VERSION ""

NS_ :

BS_:

BU_:

BO_ 19 PDU_2248: 6 Vector__XXX
 SG_ PrplSysWhlFlrCtlPriAxlRtTrqCmd : 7|15@0+ (2,-22534) [-22534|43000] "Nm" EBCM
 SG_ PrplSysWhlFlrCtlPriAxlRtActv : 8|1@0+ (1,0) [0|1] "" EBCM

BO_ 1026 PDU_2252: 24 Vector__XXX
 SG_ FE44SDGHSR_LtFstHptcStReqSeqNum : 1|2@0+ (1,0) [0|3] "counts" CGM
 SG_ FE44SDGHSR_LtFstHptcStReqPuls : 7|6@0+ (1,0) [0|63] "pulses" CGM
 SG_ FE44SDGHSR_LtSloHptcStReqSeqNum : 9|2@0+ (1,0) [0|3] "counts" CGM
 SG_ FE44SDGHSR_LtSloHptcStReqPuls : 15|6@0+ (1,0) [0|63] "pulses" CGM
 SG_ FE44SDGHSR_RtFstHptcStReqSeqNum : 17|2@0+ (1,0) [0|3] "counts" CGM
 SG_ FE44SDGHSR_RtFstHptcStReqPuls : 23|6@0+ (1,0) [0|63] "pulses" CGM
 SG_ FE44SDGHSR_RtSloHptcStReqSeqNum : 25|2@0+ (1,0) [0|3] "counts" CGM
 SG_ FE44SDGHSR_RtSloHptcStReqPuls : 31|6@0+ (1,0) [0|63] "pulses" CGM
 SG_ FFE44HSR_FrstRptHptcStReqSeqNum : 33|2@0+ (1,0) [0|3] "counts" CGM
 SG_ FFE44HSR_FrstRptHptcStReqPuls : 39|6@0+ (1,0) [0|63] "pulses" CGM
 SG_ FFE44HSR_FstHptcStReqSeqNum : 41|2@0+ (1,0) [0|3] "counts" CGM
 SG_ FFE44HSR_FstHptcStReqPuls : 47|6@0+ (1,0) [0|63] "pulses" CGM
 SG_ FFE44HSR_SloHptcStReqSeqNum : 49|2@0+ (1,0) [0|3] "counts" CGM
 SG_ FFE44HSR_SloHptcStReqPuls : 55|6@0+ (1,0) [0|63] "pulses" CGM
 SG_ FRE44HSR_FrstRptHptcStReqSeqNum : 57|2@0+ (1,0) [0|3] "counts" CGM
 SG_ FRE44HSR_FrstRptHptcStReqPuls : 63|6@0+ (1,0) [0|63] "pulses" CGM
 SG_ FRE44HSR_FstHptcStReqSeqNum : 65|2@0+ (1,0) [0|3] "counts" CGM
 SG_ FRE44HSR_FstHptcStReqPuls : 71|6@0+ (1,0) [0|63] "pulses" CGM
 SG_ FRE44HSR_SloHptcStReqSeqNum : 73|2@0+ (1,0) [0|3] "counts" CGM
 SG_ FRE44HSR_SloHptcStReqPuls : 79|6@0+ (1,0) [0|63] "pulses" CGM
 SG_ PrkAsstFllFrZn2ChEvntSt : 81|2@0+ (1,0) [0|2] "" CGM
 SG_ PrkAsstFllFrZn1ChEvntSt : 83|2@0+ (1,0) [0|2] "" CGM
 SG_ PrkAsstFlChEvntSt : 85|2@0+ (1,0) [0|2] "" CGM
 SG_ E44MutSts : 87|2@0+ (1,0) [0|2] "" CGM
 SG_ PrkAsstFllFrZn6ChEvntSt : 89|2@0+ (1,0) [0|2] "" CGM
 SG_ PrkAsstFllFrZn5ChEvntSt : 91|2@0+ (1,0) [0|2] "" CGM
 SG_ PrkAsstFllFrZn4ChEvntSt : 93|2@0+ (1,0) [0|2] "" CGM
 SG_ PrkAsstFllFrZn3ChEvntSt : 95|2@0+ (1,0) [0|2] "" CGM
 SG_ PrkAsstFllRrZn4ChEvntSt : 97|2@0+ (1,0) [0|2] "" CGM
 SG_ PrkAsstFllRrZn3ChEvntSt : 99|2@0+ (1,0) [0|2] "" CGM
 SG_ PrkAsstFllRrZn2ChEvntSt : 101|2@0+ (1,0) [0|2] "" CGM
 SG_ PrkAsstFllRrZn1ChEvntSt : 103|2@0+ (1,0) [0|2] "" CGM
 SG_ PrkAsstFrLftSdZn1ChEvntSt : 105|2@0+ (1,0) [0|2] "" CGM
 SG_ PrkAsstFrFrstRprtChEvntSt : 107|2@0+ (1,0) [0|2] "" CGM
 SG_ PrkAsstFllRrZn6ChEvntSt : 109|2@0+ (1,0) [0|2] "" CGM
 SG_ PrkAsstFllRrZn5ChEvntSt : 111|2@0+ (1,0) [0|2] "" CGM
 SG_ PrkAsstFrLftSdZn5ChEvntSt : 113|2@0+ (1,0) [0|2] "" CGM
 SG_ PrkAsstFrLftSdZn4ChEvntSt : 115|2@0+ (1,0) [0|2] "" CGM
 SG_ PrkAsstFrLftSdZn3ChEvntSt : 117|2@0+ (1,0) [0|2] "" CGM
 SG_ PrkAsstFrLftSdZn2ChEvntSt : 119|2@0+ (1,0) [0|2] "" CGM
 SG_ PrkAsstFrRghtSdZn3ChEvntSt : 121|2@0+ (1,0) [0|2] "" CGM
 SG_ PrkAsstFrRghtSdZn2ChEvntSt : 123|2@0+ (1,0) [0|2] "" CGM
 SG_ PrkAsstFrRghtSdZn1ChEvntSt : 125|2@0+ (1,0) [0|2] "" CGM
 SG_ PrkAsstFrLftSdZn6ChEvntSt : 127|2@0+ (1,0) [0|2] "" CGM
 SG_ PrkAsstFrRgrChEvntSt : 129|2@0+ (1,0) [0|2] "" CGM
 SG_ PrkAsstFrRghtSdZn6ChEvntSt : 131|2@0+ (1,0) [0|2] "" CGM
 SG_ PrkAsstFrRghtSdZn5ChEvntSt : 133|2@0+ (1,0) [0|2] "" CGM
 SG_ PrkAsstFrRghtSdZn4ChEvntSt : 135|2@0+ (1,0) [0|2] "" CGM
 SG_ PrkAsstRrLftSdZn3ChEvntSt : 137|2@0+ (1,0) [0|2] "" CGM
 SG_ PrkAsstRrLftSdZn2ChEvntSt : 139|2@0+ (1,0) [0|2] "" CGM
 SG_ PrkAsstRrLftSdZn1ChEvntSt : 141|2@0+ (1,0) [0|2] "" CGM
 SG_ PrkAsstRrFrstRprtChEvntSt : 143|2@0+ (1,0) [0|2] "" CGM
 SG_ PrkAsstRrRghtSdZn1ChEvntSt : 145|2@0+ (1,0) [0|2] "" CGM
 SG_ PrkAsstRrLftSdZn6ChEvntSt : 147|2@0+ (1,0) [0|2] "" CGM
 SG_ PrkAsstRrLftSdZn5ChEvntSt : 149|2@0+ (1,0) [0|2] "" CGM
 SG_ PrkAsstRrLftSdZn4ChEvntSt : 151|2@0+ (1,0) [0|2] "" CGM
 SG_ PrkAsstRrRghtSdZn5ChEvntSt : 153|2@0+ (1,0) [0|2] "" CGM
 SG_ PrkAsstRrRghtSdZn4ChEvntSt : 155|2@0+ (1,0) [0|2] "" CGM
 SG_ PrkAsstRrRghtSdZn3ChEvntSt : 157|2@0+ (1,0) [0|2] "" CGM
 SG_ PrkAsstRrRghtSdZn2ChEvntSt : 159|2@0+ (1,0) [0|2] "" CGM
 SG_ SuprRmtPrkMnvrPrgs : 163|14@0+ (0.01,0) [0|163.83] "" CGM
 SG_ PrkAsstRrRgrChEvntSt : 165|2@0+ (1,0) [0|2] "" CGM
 SG_ PrkAsstRrRghtSdZn6ChEvntSt : 167|2@0+ (1,0) [0|2] "" CGM
 SG_ SuprRmtPrkWrnIndReq : 181|7@0+ (1,0) [0|70] "" CGM
 SG_ SuprRmtPrkDctvSftBtnReq : 186|2@0+ (1,0) [0|3] "" CGM
 SG_ SuprRmtPrkFcsReq : 188|2@0+ (1,0) [0|3] "" CGM
 SG_ SuprRmtPrkAutoStrgIconReq : 190|2@0+ (1,0) [0|2] "" CGM

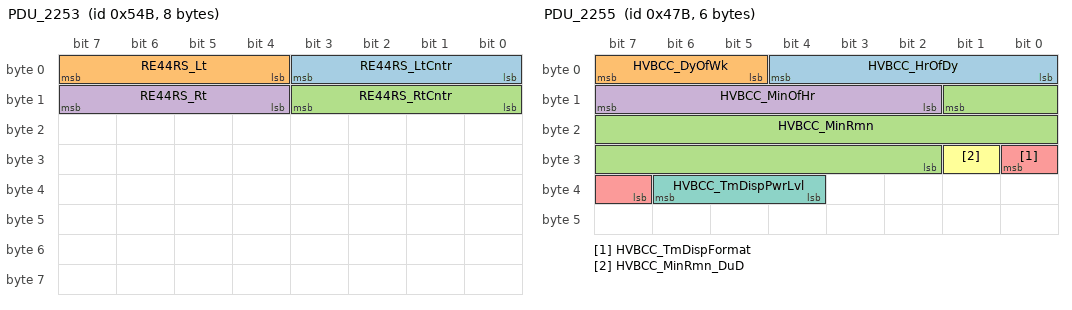
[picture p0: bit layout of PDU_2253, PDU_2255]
BO_ 1355 PDU_2253: 8 Vector__XXX
 SG_ RE44RS_LtCntr : 3|4@0+ (1,0) [0|14] "" CGM
 SG_ RE44RS_Lt : 7|4@0+ (1,0) [0|14] "" CGM
 SG_ RE44RS_RtCntr : 11|4@0+ (1,0) [0|14] "" CGM
 SG_ RE44RS_Rt : 15|4@0+ (1,0) [0|14] "" CGM

BO_ 1147 PDU_2255: 6 Vector__XXX
 SG_ HVBCC_HrOfDy : 4|5@0+ (1,0) [0|31] "h" Vector__XXX
 SG_ HVBCC_DyOfWk : 7|3@0+ (1,0) [0|7] "" Vector__XXX
 SG_ HVBCC_MinRmn : 9|16@0+ (1,0) [0|65535] "min" Vector__XXX
 SG_ HVBCC_MinOfHr : 15|6@0+ (1,0) [0|63] "min" Vector__XXX
 SG_ HVBCC_TmDispFormat : 24|2@0+ (1,0) [0|2] "" Vector__XXX
 SG_ HVBCC_MinRmn_DuD : 25|1@0+ (1,0) [0|1] "" Vector__XXX
 SG_ HVBCC_TmDispPwrLvl : 38|3@0+ (1,0) [0|4] "" VDM

BO_ 669 PDU_2256: 12 Vector__XXX
 SG_ Sig0101 : 7|1@0+ (1,0) [0|1] "" FOPM

BO_ 1321 PDU_2257: 12 Vector__XXX
 SG_ DMSDrwDrvrCstSetAval : 0|1@0+ (1,0) [0|1] "" CGM
 SG_ DMSDrwDrvrCstAvlFlg7 : 1|1@0+ (1,0) [0|1] "" CGM
 SG_ DMSDrwDrvrCstAvlFlg6 : 2|1@0+ (1,0) [0|1] "" CGM
 SG_ DMSDrwDrvrCstAvlFlg5 : 3|1@0+ (1,0) [0|1] "" CGM
 SG_ DMSDrwDrvrCstAvlFlg4 : 4|1@0+ (1,0) [0|1] "" CGM
 SG_ DMSDrwDrvrCstAvlFlg3 : 5|1@0+ (1,0) [0|1] "" CGM
 SG_ DMSDrwDrvrCstAvlFlg2 : 6|1@0+ (1,0) [0|1] "" CGM
 SG_ DMSDrwDrvrCstAvlFlg1 : 7|1@0+ (1,0) [0|1] "" CGM
 SG_ DMSIntnDrvrCstSetAval : 8|1@0+ (1,0) [0|1] "" CGM
 SG_ DMSIntnDrvrCstAvlFlg7 : 9|1@0+ (1,0) [0|1] "" CGM
 SG_ DMSIntnDrvrCstAvlFlg6 : 10|1@0+ (1,0) [0|1] "" CGM
 SG_ DMSIntnDrvrCstAvlFlg5 : 11|1@0+ (1,0) [0|1] "" CGM
 SG_ DMSIntnDrvrCstAvlFlg4 : 12|1@0+ (1,0) [0|1] "" CGM
 SG_ DMSIntnDrvrCstAvlFlg3 : 13|1@0+ (1,0) [0|1] "" CGM
 SG_ DMSIntnDrvrCstAvlFlg2 : 14|1@0+ (1,0) [0|1] "" CGM
 SG_ DMSIntnDrvrCstAvlFlg1 : 15|1@0+ (1,0) [0|1] "" CGM

BO_ 1318 PDU_2258: 12 Vector__XXX
 SG_ DMSDrwIntnDrvrDtnAlrtMutReqd : 3|1@0+ (1,0) [0|1] "" CGM
 SG_ DMSDrwIntnDrvrLvl1ChmEvntStat : 5|2@0+ (1,0) [0|2] "" CGM
 SG_ DMSDrwIntnDrvrLvl2ChmEvntStat : 7|2@0+ (1,0) [0|2] "" CGM

BO_ 1304 PDU_2259: 12 Vector__XXX
 SG_ DMSDrwDrvrDispTmSnLstBrk : 7|11@0+ (1,0) [0|2047] "min" CGM
 SG_ DMSDrwIntnDrvrHptcStReqPuls : 12|6@0+ (1,0) [0|63] "Pulses" CGM
 SG_ DMSDrwDrvrCstCurrSetVal : 16|3@0+ (1,0) [0|3] "" CGM
 SG_ DMSDrwIntnDrvrWrnIndReq : 20|4@0+ (1,0) [0|11] "" CGM
 SG_ DMSDrwIntnDrvrHptcStReqSeqNum : 22|2@0+ (1,0) [0|3] "Counts" CGM
 SG_ DMSDrwDrvrIndReq : 26|3@0+ (1,0) [0|5] "" CGM
 SG_ DMSDrwDrvrDispLvl : 29|3@0+ (1,0) [0|5] "" CGM
 SG_ DMSIntnDrvrIndReq : 33|3@0+ (1,0) [0|5] "" CGM
 SG_ DMSIntnDrvrDispLvl : 36|3@0+ (1,0) [0|5] "" CGM
 SG_ DMSIntnDrvrCstCurrSetVal : 39|3@0+ (1,0) [0|2] "" CGM
 SG_ DMSTnDrvrDrwIntnOffUnvIndOn : 42|1@0+ (1,0) [0|1] "" CGM
 SG_ DMSIntnDrvrDispFcsInd : 44|2@0+ (1,0) [0|2] "" CGM
 SG_ DMSDrwIntnDrvrDtnMtzdStBltPulRq : 46|2@0+ (1,0) [0|1] "" CGM

BO_ 544 PDU_2260: 16 Vector__XXX
 SG_ DMSEyeLocInfoXCrdnt : 7|15@0- (1,0) [-16384|16383] "mm" HUD_CAN
 SG_ DMSEyeLocInfoYCrdnt : 8|15@0- (1,0) [-16384|16383] "mm" HUD_CAN
 SG_ DMSEyeLocInfoZCrdnt : 25|15@0- (1,0) [-16384|16383] "mm" HUD_CAN
 SG_ DMSEyeGzInfoPrd : 42|14@0+ (0.05,0) [0|819.15] "Sec" HUD_CAN
 SG_ DMSEyeGzVctrPtch : 60|13@0- (0.001,0) [-4.096|4.095] "rad" HUD_CAN
 SG_ DMSEyeGzVctrRoll : 79|13@0- (0.001,0) [-4.096|4.095] "rad" HUD_CAN
 SG_ DMSEyeGzVctrYaw : 82|13@0- (0.001,0) [-4.096|4.095] "rad" HUD_CAN

BO_ 1341 PDU_2261: 12 Vector__XXX
 SG_ SD227_ARC : 4|2@0+ (1,0) [0|3] "" ECP_E
 SG_ VehDynsTkDtctSts : 7|3@0+ (1,0) [0|2] "" VICM,ECP_E

BO_ 1239 PDU_2273: 12 Vector__XXX
 SG_ PrkAsstTrHtchPsntCstAvlFlg1 : 0|1@0+ (1,0) [0|1] "" CGM
 SG_ PrkAsstONOFFCstAvlFlg7 : 1|1@0+ (1,0) [0|1] "" CGM
 SG_ PrkAsstONOFFCstAvlFlg6 : 2|1@0+ (1,0) [0|1] "" CGM
 SG_ PrkAsstONOFFCstAvlFlg5 : 3|1@0+ (1,0) [0|1] "" CGM
 SG_ PrkAsstONOFFCstAvlFlg4 : 4|1@0+ (1,0) [0|1] "" CGM
 SG_ PrkAsstONOFFCstAvlFlg3 : 5|1@0+ (1,0) [0|1] "" CGM
 SG_ PrkAsstONOFFCstAvlFlg2 : 6|1@0+ (1,0) [0|1] "" CGM
 SG_ PrkAsstONOFFCstAvlFlg1 : 7|1@0+ (1,0) [0|1] "" CGM
 SG_ PrkAsstTrHtchPsntCstAvlFlg7 : 10|1@0+ (1,0) [0|1] "" CGM
 SG_ PrkAsstTrHtchPsntCstAvlFlg6 : 11|1@0+ (1,0) [0|1] "" CGM
 SG_ PrkAsstTrHtchPsntCstAvlFlg5 : 12|1@0+ (1,0) [0|1] "" CGM
 SG_ PrkAsstTrHtchPsntCstAvlFlg4 : 13|1@0+ (1,0) [0|1] "" CGM
 SG_ PrkAsstTrHtchPsntCstAvlFlg3 : 14|1@0+ (1,0) [0|1] "" CGM
 SG_ PrkAsstTrHtchPsntCstAvlFlg2 : 15|1@0+ (1,0) [0|1] "" CGM

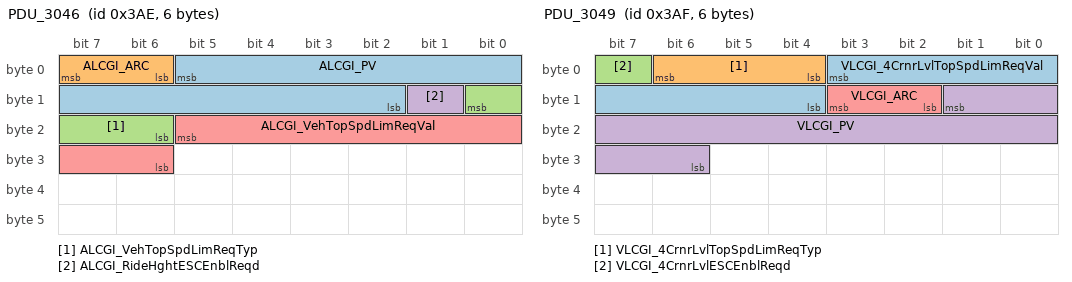
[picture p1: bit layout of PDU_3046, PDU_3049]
BO_ 942 PDU_3046: 6 Vector__XXX
 SG_ ALCGI_PV : 5|12@0+ (1,0) [0|4095] "" ECP_E
 SG_ ALCGI_ARC : 7|2@0+ (1,0) [0|3] "" ECP_E
 SG_ ALCGI_VehTopSpdLimReqTyp : 8|3@0+ (1,0) [0|6] "" ECP_E
 SG_ ALCGI_RideHghtESCEnblReqd : 9|1@0+ (1,0) [0|1] "" ECP_E
 SG_ ALCGI_VehTopSpdLimReqVal : 21|8@0+ (2,0) [0|510] "kph" ECP_E

BO_ 943 PDU_3049: 6 Vector__XXX
 SG_ VLCGI_4CrnrLvlTopSpdLimReqVal : 3|8@0+ (2,0) [0|510] "kph" ECM,PCM,ECP_E
 SG_ VLCGI_4CrnrLvlTopSpdLimReqTyp : 6|3@0+ (1,0) [0|6] "" ECM,PCM,ECP_E
 SG_ VLCGI_4CrnrLvlESCEnblReqd : 7|1@0+ (1,0) [0|1] "" ECM,PCM,ECP_E
 SG_ VLCGI_PV : 9|12@0+ (1,0) [0|4095] "" ECM,PCM,ECP_E
 SG_ VLCGI_ARC : 11|2@0+ (1,0) [0|3] "" ECM,PCM,ECP_E

BO_ 1346 PDU_3052: 6 Vector__XXX
 SG_ RrwdImpMtgnAval : 7|1@0+ (1,0) [0|1] "" Vector__XXX

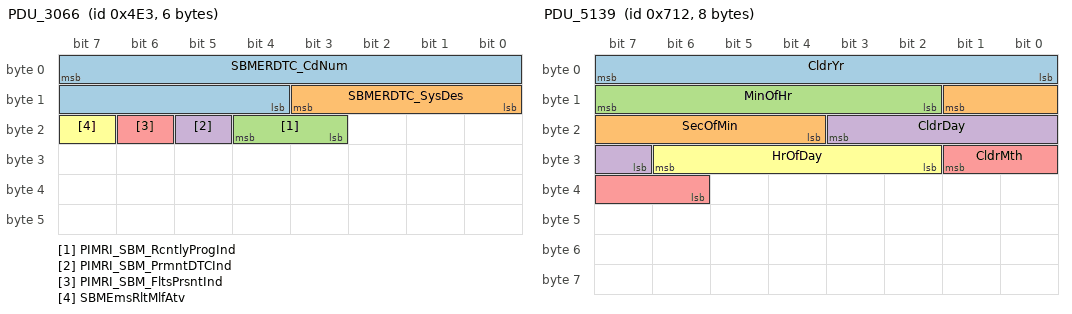
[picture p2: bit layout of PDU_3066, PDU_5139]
BO_ 1251 PDU_3066: 6 Vector__XXX
 SG_ SBMERDTC_CdNum : 7|12@0+ (1,0) [0|4095] "count" ECP_E
 SG_ SBMERDTC_SysDes : 11|4@0+ (1,0) [0|15] "" ECP_E
 SG_ PIMRI_SBM_RcntlyProgInd : 20|2@0+ (1,0) [0|3] "" ECM,PCM,ECP_E
 SG_ PIMRI_SBM_PrmntDTCInd : 21|1@0+ (1,0) [0|1] "" ECM,PCM,ECP_E
 SG_ PIMRI_SBM_FltsPrsntInd : 22|1@0+ (1,0) [0|1] "" ECM,PCM,ECP_E
 SG_ SBMEmsRltMlfAtv : 23|1@0+ (1,0) [0|1] "" ECP_E

BO_ 1429 PDU_4058: 6 Vector__XXX
 SG_ RrClsrAjrStat : 6|1@0+ (1,0) [0|1] "" ACP2_MCU,BSM,VICM,EOCM,EOCM_HC_Superset,FCM,E44
 SG_ RrClsrAjrStat_Inv : 7|1@0+ (1,0) [0|1] "" ACP2_MCU,BSM,VICM,EOCM,EOCM_HC_Superset,FCM

BO_ 1810 PDU_5139: 8 Vector__XXX
 SG_ CldrYr : 7|8@0+ (1,2000) [2000|2255] "year" BSM,VICM,FCM
 SG_ SecOfMin : 9|6@0+ (1,0) [0|63] "seconds" BSM,VICM,FCM
 SG_ MinOfHr : 15|6@0+ (1,0) [0|63] "minutes" BSM,VICM,FCM
 SG_ CldrDay : 19|5@0+ (1,0) [0|31] "day" BSM,VICM,FCM
 SG_ CldrMth : 25|4@0+ (1,0) [0|12] "" BSM,VICM,FCM
 SG_ HrOfDay : 30|5@0+ (1,0) [0|31] "hour" BSM,VICM,FCM

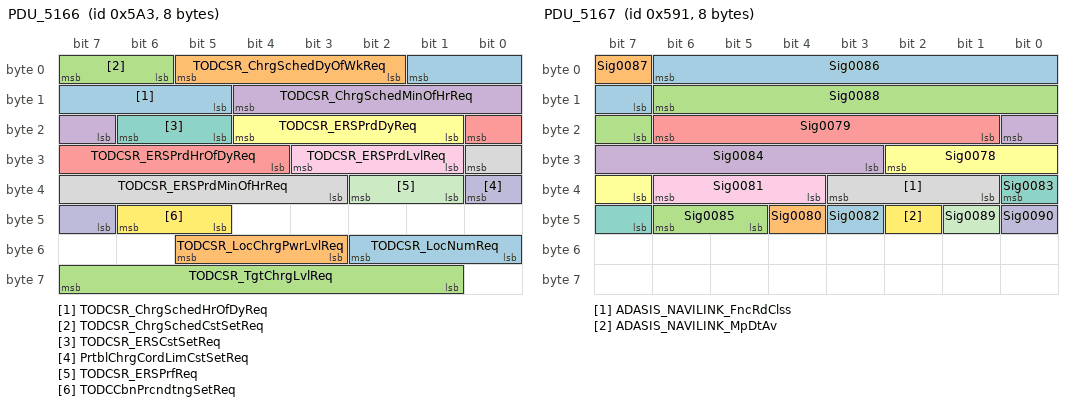
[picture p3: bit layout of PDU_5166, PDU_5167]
BO_ 1443 PDU_5166: 8 Vector__XXX
 SG_ TODCSR_ChrgSchedHrOfDyReq : 1|5@0+ (1,0) [0|31] "h" VICM
 SG_ TODCSR_ChrgSchedDyOfWkReq : 5|4@0+ (1,0) [0|10] "" VICM
 SG_ TODCSR_ChrgSchedCstSetReq : 7|2@0+ (1,0) [0|2] "" VICM
 SG_ TODCSR_ChrgSchedMinOfHrReq : 12|6@0+ (1,0) [0|63] "min" VICM
 SG_ TODCSR_ERSPrdHrOfDyReq : 16|5@0+ (1,0) [0|31] "h" VICM
 SG_ TODCSR_ERSPrdDyReq : 20|4@0+ (1,0) [0|10] "" VICM
 SG_ TODCSR_ERSCstSetReq : 22|2@0+ (1,0) [0|2] "" VICM
 SG_ TODCSR_ERSPrdMinOfHrReq : 24|6@0+ (1,0) [0|63] "min" VICM
 SG_ TODCSR_ERSPrdLvlReq : 27|3@0+ (1,0) [0|5] "" VICM
 SG_ PrtblChrgCordLimCstSetReq : 32|2@0+ (1,0) [0|2] "" VICM
 SG_ TODCSR_ERSPrfReq : 34|2@0+ (1,0) [0|3] "" VICM
 SG_ TODCCbnPrcndtngSetReq : 46|2@0+ (1,0) [0|2] "" VICM
 SG_ TODCSR_LocNumReq : 50|3@0+ (1,0) [0|5] "" VICM
 SG_ TODCSR_LocChrgPwrLvlReq : 53|3@0+ (1,0) [0|4] "" VICM
 SG_ TODCSR_TgtChrgLvlReq : 63|7@0+ (1,0) [0|127] "%" VICM

BO_ 1425 PDU_5167: 8 Vector__XXX
 SG_ Sig0086 : 6|8@0+ (1,0) [0|255] "" AHL_AFL,FCM
 SG_ Sig0087 : 7|1@0+ (1,0) [0|1] "" FCM
 SG_ Sig0088 : 14|8@0+ (1,0) [0|255] "" FCM
 SG_ Sig0084 : 16|6@0+ (1,0) [0|63] "" AHL_AFL,FCM
 SG_ Sig0079 : 22|6@0+ (1,0) [0|31] "" FCM
 SG_ Sig0078 : 26|4@0+ (1,0) [0|8] "" FCM
 SG_ Sig0083 : 32|2@0+ (1,0) [0|3] "" FCM
 SG_ ADASIS_NAVILINK_FncRdClss : 35|3@0+ (1,0) [0|7] "" AHL_AFL,FCM
 SG_ Sig0081 : 38|3@0+ (1,0) [0|7] "" FCM
 SG_ Sig0090 : 40|1@0+ (1,0) [0|1] "" AHL_AFL,FCM
 SG_ Sig0089 : 41|1@0+ (1,0) [0|1] "" AHL_AFL,FCM
 SG_ ADASIS_NAVILINK_MpDtAv : 42|1@0+ (1,0) [0|1] "" FCM
 SG_ Sig0082 : 43|1@0+ (1,0) [0|1] "" AHL_AFL,FCM
 SG_ Sig0080 : 44|1@0+ (1,0) [0|1] "" AHL_AFL,FCM
 SG_ Sig0085 : 46|2@0+ (1,0) [0|3] "" FCM

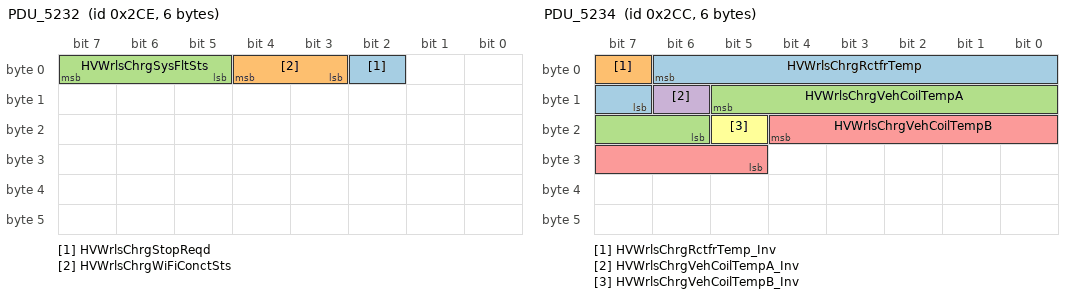
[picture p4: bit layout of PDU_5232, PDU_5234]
BO_ 718 PDU_5232: 6 Vector__XXX
 SG_ HVWrlsChrgStopReqd : 2|1@0+ (1,0) [0|1] "" VICM
 SG_ HVWrlsChrgWiFiConctSts : 4|2@0+ (1,0) [0|2] "" VICM
 SG_ HVWrlsChrgSysFltSts : 7|3@0+ (1,0) [0|6] "" VICM

BO_ 730 PDU_5233: 6 Vector__XXX
 SG_ HVWrlsChrgLivngObjDtd : 6|1@0+ (1,0) [0|1] "" VICM
 SG_ HVWrlsChrgFrgnObjDtd : 7|1@0+ (1,0) [0|1] "" VICM

BO_ 716 PDU_5234: 6 Vector__XXX
 SG_ HVWrlsChrgRctfrTemp : 6|8@0+ (1,-40) [-40|215] "deg C" VICM
 SG_ HVWrlsChrgRctfrTemp_Inv : 7|1@0+ (1,0) [0|1] "" VICM
 SG_ HVWrlsChrgVehCoilTempA : 13|8@0+ (1,-40) [-40|215] "deg C" VICM
 SG_ HVWrlsChrgVehCoilTempA_Inv : 14|1@0+ (1,0) [0|1] "" VICM
 SG_ HVWrlsChrgVehCoilTempB : 20|8@0+ (1,-40) [-40|215] "deg C" VICM
 SG_ HVWrlsChrgVehCoilTempB_Inv : 21|1@0+ (1,0) [0|1] "" VICM

BO_ 717 PDU_5235: 6 Vector__XXX
 SG_ HVWrlsChrgIntopbltCkSts : 5|2@0+ (1,0) [0|2] "" VICM
 SG_ HVWrlsChrgIntopbltCkFldRsn : 7|2@0+ (1,0) [0|2] "" VICM

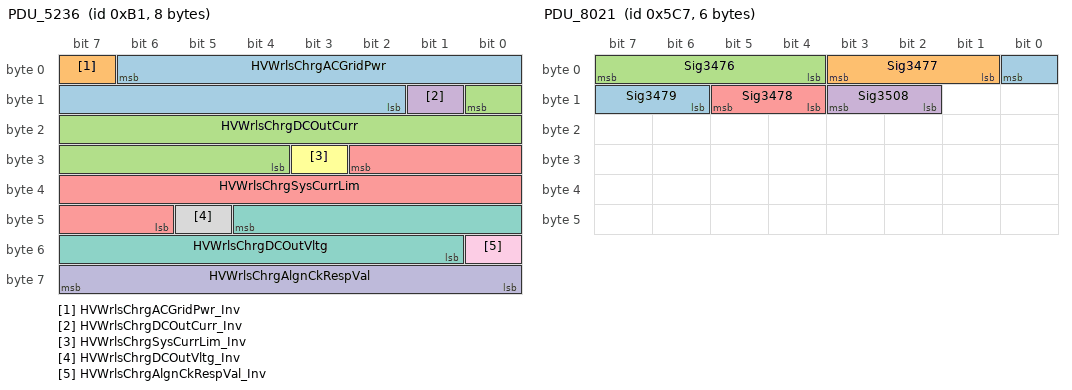
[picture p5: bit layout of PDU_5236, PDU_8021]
BO_ 177 PDU_5236: 8 Vector__XXX
 SG_ HVWrlsChrgACGridPwr : 6|13@0+ (0.1,0) [0|819.1] "KW" VICM
 SG_ HVWrlsChrgACGridPwr_Inv : 7|1@0+ (1,0) [0|1] "" VICM
 SG_ HVWrlsChrgDCOutCurr : 8|13@0+ (0.02,0) [0|163.82] "A" VICM
 SG_ HVWrlsChrgDCOutCurr_Inv : 9|1@0+ (1,0) [0|1] "" VICM
 SG_ HVWrlsChrgSysCurrLim : 26|13@0+ (0.02,0) [0|163.82] "A" VICM
 SG_ HVWrlsChrgSysCurrLim_Inv : 27|1@0+ (1,0) [0|1] "" VICM
 SG_ HVWrlsChrgDCOutVltg : 44|12@0+ (0.125,0) [0|511.875] "V" VICM
 SG_ HVWrlsChrgDCOutVltg_Inv : 45|1@0+ (1,0) [0|1] "" VICM
 SG_ HVWrlsChrgAlgnCkRespVal_Inv : 48|1@0+ (1,0) [0|1] "" VICM
 SG_ HVWrlsChrgAlgnCkRespVal : 63|8@0+ (0.392157,0) [0|100] "pct" VICM

BO_ 535 PDU_5237: 6 Vector__XXX
 SG_ HVWrlsChrgSysStat : 7|3@0+ (1,0) [0|6] "" VICM

BO_ 1479 PDU_8021: 6 Vector__XXX
 SG_ Sig3479 : 0|3@0+ (1,0) [0|7] "" AHL_AFL
 SG_ Sig3477 : 3|3@0+ (1,0) [0|7] "" AHL_AFL
 SG_ Sig3476 : 7|4@0+ (1,0) [0|9] "" AHL_AFL,NVM
 SG_ Sig3508 : 11|2@0+ (1,0) [0|2] "" AHL_AFL,CGM
 SG_ Sig3478 : 13|2@0+ (1,0) [0|3] "" AHL_AFL

BO_ 1824 PDU_8061: 8 Vector__XXX
 SG_ Sig7678 : 0|1@0+ (1,0) [0|1] "" Vector__XXX
 SG_ Sig7675 : 1|1@0+ (1,0) [0|1] "" Vector__XXX
 SG_ Sig7674 : 2|1@0+ (1,0) [0|1] "" Vector__XXX
 SG_ Sig7673 : 3|1@0+ (1,0) [0|1] "" Vector__XXX
 SG_ Sig7672 : 4|1@0+ (1,0) [0|1] "" Vector__XXX
 SG_ Sig7671 : 5|1@0+ (1,0) [0|1] "" Vector__XXX
 SG_ Sig7670 : 6|1@0+ (1,0) [0|1] "" Vector__XXX
 SG_ Sig7669 : 7|1@0+ (1,0) [0|1] "" Vector__XXX
 SG_ Sig7686 : 8|1@0+ (1,0) [0|1] "" Vector__XXX
 SG_ Sig7685 : 9|1@0+ (1,0) [0|1] "" Vector__XXX
 SG_ Sig7684 : 10|1@0+ (1,0) [0|1] "" Vector__XXX
 SG_ Sig7683 : 11|1@0+ (1,0) [0|1] "" Vector__XXX
 SG_ Sig7682 : 12|1@0+ (1,0) [0|1] "" Vector__XXX
 SG_ Sig7681 : 13|1@0+ (1,0) [0|1] "" Vector__XXX
 SG_ Sig7680 : 14|1@0+ (1,0) [0|1] "" Vector__XXX
 SG_ TrfcSgnMemOfstEnbld : 15|1@0+ (1,0) [0|1] "" ECM,PCM,ECP_E
 SG_ Sig7698 : 16|1@0+ (1,0) [0|1] "" Vector__XXX
 SG_ Sig7697 : 17|1@0+ (1,0) [0|1] "" Vector__XXX
 SG_ Sig7696 : 18|1@0+ (1,0) [0|1] "" Vector__XXX
 SG_ Sig7695 : 19|1@0+ (1,0) [0|1] "" Vector__XXX
 SG_ Sig7694 : 20|1@0+ (1,0) [0|1] "" Vector__XXX
 SG_ Sig7693 : 21|1@0+ (1,0) [0|1] "" Vector__XXX
 SG_ Sig7692 : 22|1@0+ (1,0) [0|1] "" Vector__XXX
 SG_ Sig7688 : 23|1@0+ (1,0) [0|1] "" Vector__XXX
 SG_ Sig7699 : 31|1@0+ (1,0) [0|1] "" Vector__XXX

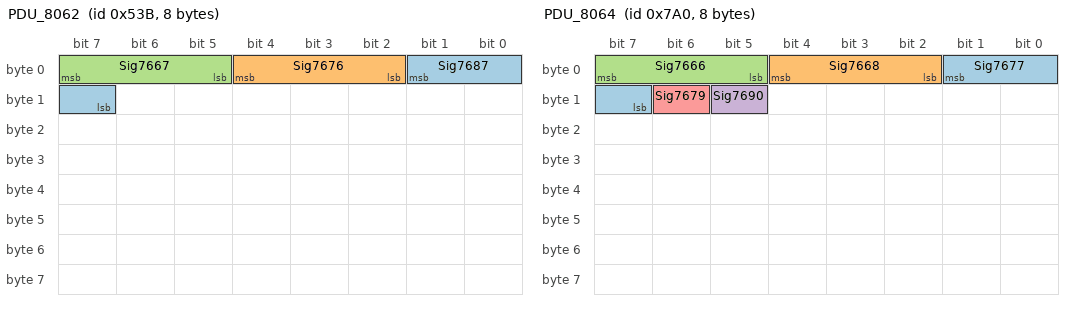
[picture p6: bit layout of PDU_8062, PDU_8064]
BO_ 1339 PDU_8062: 8 Vector__XXX
 SG_ Sig7687 : 1|3@0+ (1,0) [0|2] "" FCM
 SG_ Sig7676 : 4|3@0+ (1,0) [0|2] "" FCM
 SG_ Sig7667 : 7|3@0+ (1,0) [0|2] "" FCM

BO_ 1242 PDU_8063: 8 Vector__XXX
 SG_ Sig7691 : 5|2@0+ (1,0) [0|2] "" Vector__XXX
 SG_ Sig7689 : 7|2@0+ (1,0) [0|2] "" Vector__XXX

BO_ 1952 PDU_8064: 8 Vector__XXX
 SG_ Sig7677 : 1|3@0+ (1,0) [0|2] "" Vector__XXX
 SG_ Sig7668 : 4|3@0+ (1,0) [0|2] "" Vector__XXX
 SG_ Sig7666 : 7|3@0+ (1,0) [0|2] "" Vector__XXX
 SG_ Sig7690 : 13|1@0+ (1,0) [0|1] "" Vector__XXX
 SG_ Sig7679 : 14|1@0+ (1,0) [0|1] "" Vector__XXX

BO_ 728 PDU_9034: 8 Vector__XXX
 SG_ EE46ecGridVltgTgt : 7|11@0+ (0.01,0) [0|20.47] "Volts" FOPM
 SG_ OutsdAmbtLgtLvl : 12|8@0+ (20,0) [0|5100] "Lux" NVM
 SG_ ACCompNormLd : 17|8@0+ (0.1,0) [0|25.5] "l/min" ECM,PCM
 SG_ ACCompNormLd_Inv : 18|1@0+ (1,0) [0|1] "" ECM,PCM
 SG_ OutsdAmbtLgtLvl_Inv : 19|1@0+ (1,0) [0|1] "" NVM
 SG_ OutsdAmbtLgtLvl_DuD : 20|1@0+ (1,0) [0|1] "" NVM
 SG_ PFMinIdlBsRq : 33|3@0+ (1,0) [0|4] "" ECM,PCM
 SG_ StBltShfIntlkReqSts : 40|2@0+ (1,0) [0|3] "" ECM,PCM
 SG_ LDWCtrlSwSts : 42|2@0+ (1,0) [0|3] "" ACP2_MCU,EOCM,EOCM_HC_Superset,FCM
 SG_ EE46ecGridVltgOvrrdPrty : 44|2@0+ (1,0) [0|3] "" FOPM
 SG_ ACCompModReq : 46|2@0+ (1,0) [0|3] "" ECM,PCM
 SG_ FOPPriGridOvrrdActv : 48|1@0+ (1,0) [0|1] "" FOPM
 SG_ EPMGridIsltnReqd : 49|1@0+ (1,0) [0|1] "" FOPM
 SG_ ClntCircPmpRq : 50|1@0+ (1,0) [0|1] "" ECM,PCM
 SG_ ClmtCtrlHtrEngRunRq : 51|1@0+ (1,0) [0|1] "" ECM,PCM,ECP_X1
 SG_ BdyCtrlEmsRltMlfAtv : 52|1@0+ (1,0) [0|1] "" ECM,PCM
 SG_ ACCmpsrFldOn : 53|1@0+ (1,0) [0|1] "" ECM,PCM
 SG_ ACCmEngRunReq : 54|1@0+ (1,0) [0|1] "" ECM,PCM,ECP_X1
 SG_ PlatEngSpdCmdSysTyp : 62|2@0+ (1,0) [0|2] "" ECM
 SG_ LdMeToCarActv : 63|1@0+ (1,0) [0|1] "" AHL_AFL

BO_ 1442 PDU_9035: 32 Vector__XXX
 SG_ IBS12VBatCurrExtndRng : 0|22@0+ (0.001,-2097.15) [-2097.15|2097.15] "Amp" ECM,PCM
 SG_ IBS12VEnhdBatSOC : 32|8@0+ (0.39,0) [0|99.45] "%" ECM,PCM
 SG_ IBS12VBatCurrExtndRng_Inv : 33|1@0+ (1,0) [0|1] "" ECM,PCM
 SG_ IBS12VEnhdBatSOCErr : 40|8@0+ (0.39,0) [0|99.45] "%" ECM,PCM
 SG_ IBS12VEnhdBatSOCMin : 48|8@0+ (0.39,0) [0|99.45] "%" ECM,PCM
 SG_ IBS12VEstdBatTemp : 56|8@0+ (1,-40) [-40|215] "Degree C" ECM,PCM
 SG_ IBS12VEstdBatTemp_Inv : 64|1@0+ (1,0) [0|1] "" ECM,PCM
 SG_ IBSBatSOH : 79|8@0+ (0.39,0) [0|99.45] "%" ECM,PCM
 SG_ IBSEnhdBatSOF : 87|8@0+ (0.05,0) [0|12.75] "Volts" ECM,PCM
 SG_ IBSMinCrnkgVltg : 93|15@0+ (0.001,0) [0|32.767] "Volts" ECM,PCM
 SG_ IBSIntrnlFltPr_Inv : 94|1@0+ (1,0) [0|1] "" ECM,PCM
 SG_ IBSIntrnlFltPr : 95|1@0+ (1,0) [0|1] "" ECM,PCM
 SG_ IBSRwBatSOC : 110|8@0+ (0.39,0) [0|99.45] "%" ECM,PCM
 SG_ IBSRwBatSOCErr : 118|8@0+ (0.39,0) [0|99.45] "%" ECM,PCM
 SG_ ElpsdTimeCnt : 125|24@0+ (1,0) [0|1.67772e+007] "min" ECM,PCM,RDCM,TCM
 SG_ EnhdElpsdTmCnt : 149|24@0+ (1,0) [0|1.67772e+007] "min" ECM,PCM,TCM
 SG_ BCERDTC_CdNum : 173|12@0+ (1,0) [0|4095] "counts" ECM,PCM
 SG_ BCERDTC_SysDes : 177|4@0+ (1,0) [0|15] "" ECM,PCM
 SG_ EngOffTmExtndRng : 189|8@0+ (4,0) [0|1020] "min" ADIMa,ADIMb,DCM,ECM,PCM,RDCM,TCCM,TCM,ECP_E
 SG_ EngOffTmExtndRng_Inv : 197|1@0+ (1,0) [0|1] "" ADIMa,ADIMb,DCM,ECM,PCM,RDCM,TCCM,TCM,ECP_E
 SG_ EngPrfID : 204|8@0+ (2,0) [0|510] "kW" ECM,PCM
 SG_ EnhdElpsdTmCntDgrd : 208|1@0+ (1,0) [0|1] "" ECM,PCM,TCM
 SG_ ElpsdTimeCntRstOcc : 209|1@0+ (1,0) [0|1] "" ECM,PCM,RDCM,TCM
 SG_ IBS12VBatVlt : 219|15@0+ (0.001,0) [0|32.767] "" ECM,PCM
 SG_ TrnstStrgLogisticsMdActivation : 220|1@0+ (1,0) [0|1] "" ACP2_MCU,EOCM,EOCM_HC_Superset
 SG_ RstrctdPwrtrnOpModeReqd : 221|1@0+ (1,0) [0|1] "" ECM,PCM
 SG_ PrtctdIdlShftrLckReq : 222|1@0+ (1,0) [0|1] "" ECM,PCM
 SG_ FgLmpFrtFncActv : 223|1@0+ (1,0) [0|1] "" AHL_AFL
 SG_ ExtLgtChrgphyFrtActvn : 235|4@0+ (1,0) [0|6] "" AHL_AFL
 SG_ IBS12VBatVlt_Inv : 236|1@0+ (1,0) [0|1] "" ECM,PCM

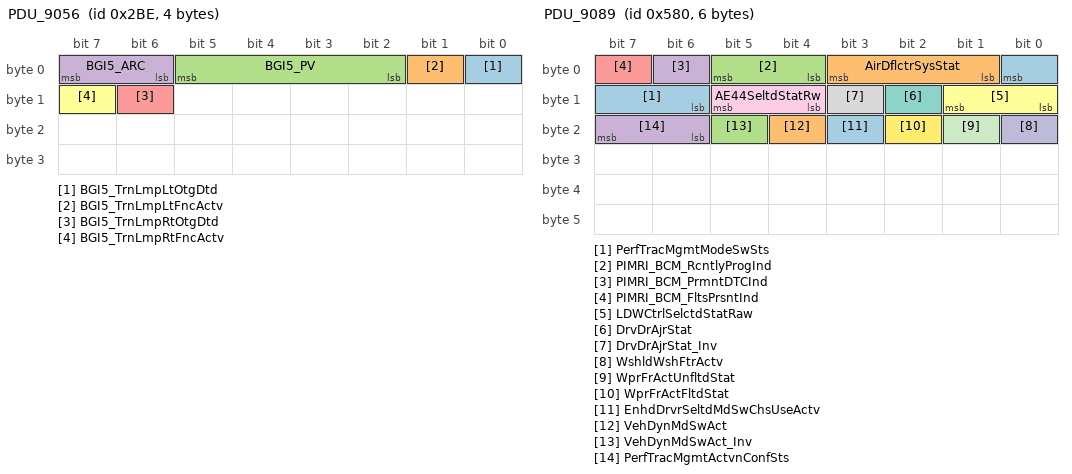
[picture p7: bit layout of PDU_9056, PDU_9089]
BO_ 702 PDU_9056: 4 Vector__XXX
 SG_ BGI5_TrnLmpLtOtgDtd : 0|1@0+ (1,0) [0|1] "" ACP2_MCU,EOCM,EOCM_HC_Superset
 SG_ BGI5_TrnLmpLtFncActv : 1|1@0+ (1,0) [0|1] "" ACP2_MCU,EOCM,EOCM_HC_Superset
 SG_ BGI5_PV : 5|4@0+ (1,0) [0|15] "" ACP2_MCU,EOCM,EOCM_HC_Superset
 SG_ BGI5_ARC : 7|2@0+ (1,0) [0|3] "" ACP2_MCU,EOCM,EOCM_HC_Superset
 SG_ BGI5_TrnLmpRtOtgDtd : 14|1@0+ (1,0) [0|1] "" ACP2_MCU,EOCM,EOCM_HC_Superset
 SG_ BGI5_TrnLmpRtFncActv : 15|1@0+ (1,0) [0|1] "" ACP2_MCU,EOCM,EOCM_HC_Superset

BO_ 1464 PDU_9064: 2 Vector__XXX
 SG_ VehIdNmDig1 : 7|8@0+ (1,0) [0|255] "" AHL_AFL,ARS,ECM,PCM

BO_ 1408 PDU_9089: 6 Vector__XXX
 SG_ PerfTracMgmtModeSwSts : 0|3@0+ (1,0) [0|4] "" EBCM
 SG_ AirDflctrSysStat : 3|3@0+ (1,0) [0|5] "" EBCM
 SG_ PIMRI_BCM_RcntlyProgInd : 5|2@0+ (1,0) [0|3] "" ECM,PCM
 SG_ PIMRI_BCM_PrmntDTCInd : 6|1@0+ (1,0) [0|1] "" ECM,PCM
 SG_ PIMRI_BCM_FltsPrsntInd : 7|1@0+ (1,0) [0|1] "" ECM,PCM
 SG_ LDWCtrlSelctdStatRaw : 9|2@0+ (1,0) [0|2] "" ACP2_MCU,EOCM,EOCM_HC_Superset,FCM
 SG_ DrvDrAjrStat : 10|1@0+ (1,0) [0|1] "" ACP2_MCU,EBCM,ECM,EOCM,EOCM_HC_Superset,FCM,PCM
 SG_ DrvDrAjrStat_Inv : 11|1@0+ (1,0) [0|1] "" ACP2_MCU,EBCM,ECM,EOCM,EOCM_HC_Superset,FCM,PCM
 SG_ AE44SeltdStatRw : 13|2@0+ (1,0) [0|3] "" E44
 SG_ WshldWshFtrActv : 16|1@0+ (1,0) [0|1] "" ACP2_MCU,EOCM,EOCM_HC_Superset,FCM
 SG_ WprFrActUnfltdStat : 17|1@0+ (1,0) [0|1] "" ACP2_MCU,ECM,EOCM,EOCM_HC_Superset,FCM,PCM
 SG_ WprFrActFltdStat : 18|1@0+ (1,0) [0|1] "" ACP2_MCU,AHL_AFL,EBCM,EOCM,EOCM_HC_Superset,FCM
 SG_ EnhdDrvrSeltdMdSwChsUseActv : 19|1@0+ (1,0) [0|1] "" EBCM
 SG_ VehDynMdSwAct : 20|1@0+ (1,0) [0|1] "" EBCM,ECM,PCM
 SG_ VehDynMdSwAct_Inv : 21|1@0+ (1,0) [0|1] "" EBCM
 SG_ PerfTracMgmtActvnConfSts : 23|2@0+ (1,0) [0|2] "" EBCM

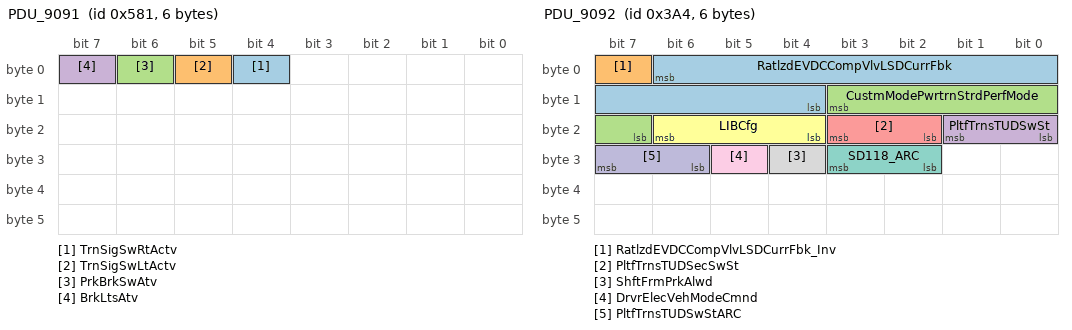
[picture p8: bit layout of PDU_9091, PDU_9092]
BO_ 1409 PDU_9091: 6 Vector__XXX
 SG_ TrnSigSwRtActv : 4|1@0+ (1,0) [0|1] "" ACP2_MCU,EOCM,EOCM_HC_Superset,FCM,E44
 SG_ TrnSigSwLtActv : 5|1@0+ (1,0) [0|1] "" ACP2_MCU,EOCM,EOCM_HC_Superset,FCM,E44
 SG_ PrkBrkSwAtv : 6|1@0+ (1,0) [0|1] "" ACP2_MCU,ECM,EOCM,EOCM_HC_Superset,FCM,PCM,TCM
 SG_ BrkLtsAtv : 7|1@0+ (1,0) [0|1] "" AHL_AFL

BO_ 932 PDU_9092: 6 Vector__XXX
 SG_ RatlzdEVDCCompVlvLSDCurrFbk : 6|11@0+ (1,0) [0|2047] "mA" BSM
 SG_ RatlzdEVDCCompVlvLSDCurrFbk_Inv : 7|1@0+ (1,0) [0|1] "" BSM
 SG_ CustmModePwrtrnStrdPerfMode : 11|5@0+ (1,0) [0|14] "" EBCM,ECM,PCM
 SG_ PltfTrnsTUDSwSt : 17|2@0+ (1,0) [0|3] "" ECM,PCM,TCM
 SG_ PltfTrnsTUDSecSwSt : 19|2@0+ (1,0) [0|3] "" PCM,TCM
 SG_ LIBCfg : 22|3@0+ (1,0) [0|2] "" LIB1
 SG_ SD118_ARC : 27|2@0+ (1,0) [0|3] "" BSM
 SG_ ShftFrmPrkAlwd : 28|1@0+ (1,0) [0|1] "" ECM,PCM
 SG_ DrvrElecVehModeCmnd : 29|1@0+ (1,0) [0|1] "" BSM,ECM,PCM,ECP_X1
 SG_ PltfTrnsTUDSwStARC : 31|2@0+ (1,0) [0|3] "" PCM,TCM

BO_ 1426 PDU_9094: 8 Vector__XXX
 SG_ DM1Unavailable : 0|1@0+ (1,0) [0|1] "" EBCM,ECM,PCM
 SG_ DM1Status : 1|1@0+ (1,0) [0|1] "" ACP2_MCU,AHL_AFL,BSM,EBCM,ECM,EOCM,EOCM_HC_Superset,FCM,PCM,RDCM
 SG_ DM1Pending : 2|1@0+ (1,0) [0|1] "" EBCM,ECM,PCM
 SG_ DM1Name : 7|5@0+ (1,0) [0|25] "" ACP2_MCU,AHL_AFL,BSM,EBCM,ECM,EOCM,EOCM_HC_Superset,FCM,PCM,RDCM
 SG_ DM2Unavailable : 8|1@0+ (1,0) [0|1] "" EBCM,ECM,PCM
 SG_ DM2Status : 9|1@0+ (1,0) [0|1] "" ACP2_MCU,AHL_AFL,BSM,EBCM,ECM,EOCM,EOCM_HC_Superset,FCM,PCM,RDCM
 SG_ DM2Pending : 10|1@0+ (1,0) [0|1] "" EBCM,ECM,PCM
 SG_ DM2Name : 15|5@0+ (1,0) [0|25] "" ACP2_MCU,AHL_AFL,BSM,EBCM,ECM,EOCM,EOCM_HC_Superset,FCM,PCM,RDCM
 SG_ DM3Unavailable : 16|1@0+ (1,0) [0|1] "" EBCM,ECM,PCM
 SG_ DM3Status : 17|1@0+ (1,0) [0|1] "" ACP2_MCU,AHL_AFL,BSM,EBCM,ECM,EOCM,EOCM_HC_Superset,FCM,PCM,RDCM
 SG_ DM3Pending : 18|1@0+ (1,0) [0|1] "" EBCM,ECM,PCM
 SG_ DM3Name : 23|5@0+ (1,0) [0|25] "" ACP2_MCU,AHL_AFL,BSM,EBCM,ECM,EOCM,EOCM_HC_Superset,FCM,PCM,RDCM
 SG_ DM4Unavailable : 24|1@0+ (1,0) [0|1] "" EBCM,ECM,PCM
 SG_ DM4Status : 25|1@0+ (1,0) [0|1] "" ACP2_MCU,AHL_AFL,BSM,EBCM,ECM,EOCM,EOCM_HC_Superset,FCM,PCM,RDCM
 SG_ DM4Pending : 26|1@0+ (1,0) [0|1] "" EBCM,ECM,PCM
 SG_ DM4Name : 31|5@0+ (1,0) [0|25] "" ACP2_MCU,AHL_AFL,BSM,EBCM,ECM,EOCM,EOCM_HC_Superset,FCM,PCM,RDCM
 SG_ DM5Unavailable : 32|1@0+ (1,0) [0|1] "" EBCM,ECM,PCM
 SG_ DM5Status : 33|1@0+ (1,0) [0|1] "" ACP2_MCU,AHL_AFL,BSM,EBCM,ECM,EOCM,EOCM_HC_Superset,FCM,PCM,RDCM
 SG_ DM5Pending : 34|1@0+ (1,0) [0|1] "" EBCM,ECM,PCM
 SG_ DM5Name : 39|5@0+ (1,0) [0|25] "" ACP2_MCU,AHL_AFL,BSM,EBCM,ECM,EOCM,EOCM_HC_Superset,FCM,PCM,RDCM
 SG_ DM6Unavailable : 40|1@0+ (1,0) [0|1] "" EBCM,ECM,PCM
 SG_ DM6Status : 41|1@0+ (1,0) [0|1] "" ACP2_MCU,AHL_AFL,BSM,EBCM,ECM,EOCM,EOCM_HC_Superset,FCM,PCM,RDCM
 SG_ DM6Pending : 42|1@0+ (1,0) [0|1] "" EBCM,ECM,PCM
 SG_ DM6Name : 47|5@0+ (1,0) [0|25] "" ACP2_MCU,AHL_AFL,BSM,EBCM,ECM,EOCM,EOCM_HC_Superset,FCM,PCM,RDCM
 SG_ DM7Unavailable : 48|1@0+ (1,0) [0|1] "" EBCM,ECM,PCM
 SG_ DM7Status : 49|1@0+ (1,0) [0|1] "" ACP2_MCU,AHL_AFL,BSM,EBCM,ECM,EOCM,EOCM_HC_Superset,FCM,PCM,RDCM
 SG_ DM7Pending : 50|1@0+ (1,0) [0|1] "" EBCM,ECM,PCM
 SG_ DM7Name : 55|5@0+ (1,0) [0|25] "" ACP2_MCU,AHL_AFL,BSM,EBCM,ECM,EOCM,EOCM_HC_Superset,FCM,PCM,RDCM
 SG_ DM8Unavailable : 56|1@0+ (1,0) [0|1] "" EBCM,ECM,PCM
 SG_ DM8Status : 57|1@0+ (1,0) [0|1] "" ACP2_MCU,AHL_AFL,BSM,EBCM,ECM,EOCM,EOCM_HC_Superset,FCM,PCM,RDCM
 SG_ DM8Pending : 58|1@0+ (1,0) [0|1] "" EBCM,ECM,PCM
 SG_ DM8Name : 63|5@0+ (1,0) [0|25] "" ACP2_MCU,AHL_AFL,BSM,EBCM,ECM,EOCM,EOCM_HC_Superset,FCM,PCM,RDCM

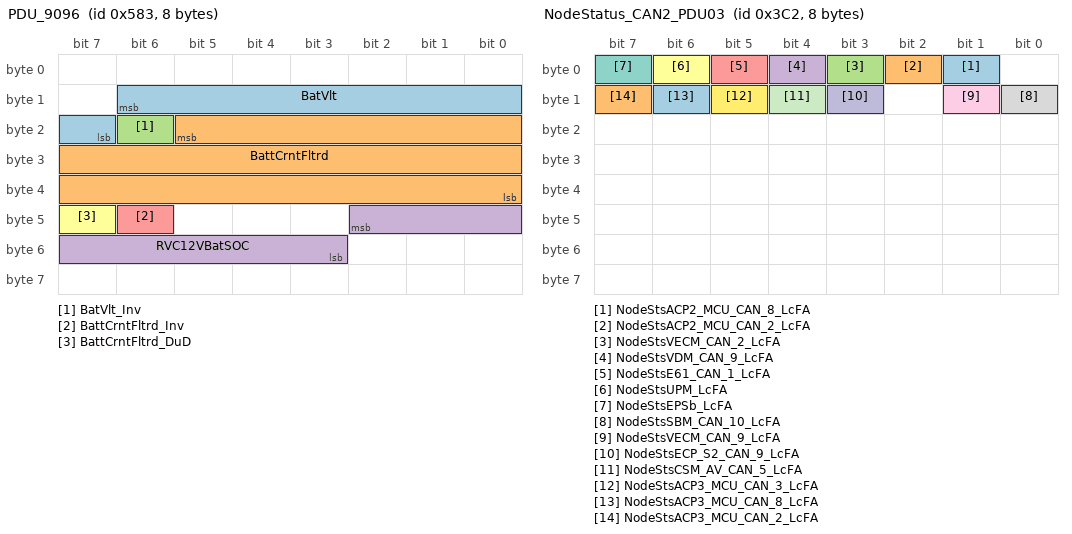
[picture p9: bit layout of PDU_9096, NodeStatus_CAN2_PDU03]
BO_ 1411 PDU_9096: 8 Vector__XXX
 SG_ BatVlt : 14|8@0+ (0.1,3) [3|28.5] "volts" ECM,PCM,TCM
 SG_ BattCrntFltrd : 21|22@0- (0.001,0) [-2097.15|2097.15] "Amps" BSM
 SG_ BatVlt_Inv : 22|1@0+ (1,0) [0|1] "" ECM,PCM
 SG_ RVC12VBatSOC : 42|8@0+ (0.5,0) [0|127.5] "%" ECM,PCM
 SG_ BattCrntFltrd_Inv : 46|1@0+ (1,0) [0|1] "" BSM
 SG_ BattCrntFltrd_DuD : 47|1@0+ (1,0) [0|1] "" BSM

BO_ 2147745822 Message0890_PDU: 1 Vector__XXX
 SG_ Sig4411 : 7|1@0+ (1,0) [0|1] "" CGM

BO_ 963 NodeStatus_CAN2_PDU01: 8 Vector__XXX
 SG_ NodeStsADIMb_CAN_9_LcFA : 0|1@0+ (1,0) [0|1] "" ACP2_MCU,ADIMa,AHL_AFL,AHS,ARS,BSM,VECM,VICM,BSM_MH,DCM,DMS,EBCM,ECM,ECP_MC,EOCM,EOCM_HC_Superset,EPSRAa,EPS,EPSb,FCM,HUD_CAN,LIB1,NVM,E44,PCM,RDCM,TCCM,TCM,ECP_E,ECP_S,ECP_S2,ECP_X1
 SG_ NodeStsADIMb_CAN_3_LcFA : 1|1@0+ (1,0) [0|1] "" ACP2_MCU,ADIMa,AHL_AFL,AHS,ARS,BSM,VECM,VICM,BSM_MH,DCM,DMS,EBCM,ECM,ECP_MC,EOCM,EOCM_HC_Superset,EPSRAa,EPS,EPSb,FCM,HUD_CAN,LIB1,NVM,E44,PCM,RDCM,TCCM,TCM,ECP_E,ECP_S,ECP_S2,ECP_X1
 SG_ NodeStsADIMb_CAN_2_LcFA : 2|1@0+ (1,0) [0|1] "" ACP2_MCU,ADIMa,AHL_AFL,AHS,ARS,BSM,VECM,VICM,BSM_MH,DCM,DMS,EBCM,ECM,ECP_MC,EOCM,EOCM_HC_Superset,EPSRAa,EPS,EPSb,FCM,HUD_CAN,LIB1,NVM,E44,PCM,RDCM,TCCM,TCM,ECP_E,ECP_S,ECP_S2,ECP_X1
 SG_ NodeStsADIMb_CAN_10_LcFA : 3|1@0+ (1,0) [0|1] "" ACP2_MCU,ADIMa,AHL_AFL,AHS,ARS,BSM,VECM,VICM,BSM_MH,DCM,DMS,ECM,ECP_MC,EOCM,EOCM_HC_Superset,EPSRAa,EPS,EPSb,FCM,HUD_CAN,LIB1,NVM,E44,PCM,RDCM,TCCM,TCM,ECP_E,ECP_S,ECP_S2,ECP_X1
 SG_ NodeStsADIMa_CAN_9_LcFA : 4|1@0+ (1,0) [0|1] "" ACP2_MCU,ADIMb,AHL_AFL,AHS,ARS,BSM,VECM,VICM,BSM_MH,DCM,DMS,EBCM,ECM,ECP_MC,EOCM,EOCM_HC_Superset,EPSRAa,EPS,EPSb,FCM,HUD_CAN,LIB1,NVM,E44,PCM,RDCM,TCCM,TCM,ECP_E,ECP_S,ECP_S2,ECP_X1
 SG_ NodeStsADIMa_CAN_3_LcFA : 5|1@0+ (1,0) [0|1] "" ACP2_MCU,ADIMb,AHL_AFL,AHS,ARS,BSM,VECM,VICM,BSM_MH,DCM,DMS,EBCM,ECM,ECP_MC,EOCM,EOCM_HC_Superset,EPSRAa,EPS,EPSb,FCM,HUD_CAN,LIB1,NVM,E44,PCM,RDCM,TCCM,TCM,ECP_E,ECP_S,ECP_S2,ECP_X1
 SG_ NodeStsADIMa_CAN_2_LcFA : 6|1@0+ (1,0) [0|1] "" ACP2_MCU,ADIMb,AHL_AFL,AHS,ARS,BSM,VECM,VICM,BSM_MH,DCM,DMS,EBCM,ECM,ECP_MC,EOCM,EOCM_HC_Superset,EPSRAa,EPS,EPSb,FCM,HUD_CAN,LIB1,NVM,E44,PCM,RDCM,TCCM,TCM,ECP_E,ECP_S,ECP_S2,ECP_X1
 SG_ NodeStsADIMa_CAN_10_LcFA : 7|1@0+ (1,0) [0|1] "" ACP2_MCU,ADIMb,AHL_AFL,AHS,ARS,BSM,VECM,VICM,BSM_MH,DCM,DMS,EBCM,ECM,ECP_MC,EOCM,EOCM_HC_Superset,EPSRAa,EPS,EPSb,FCM,HUD_CAN,LIB1,NVM,E44,PCM,RDCM,TCCM,TCM,ECP_E,ECP_S,ECP_S2,ECP_X1
 SG_ NodeStsAE44_CAN_1_LcFA : 8|1@0+ (1,0) [0|1] "" ACP2_MCU,ADIMa,ADIMb,AHL_AFL,AHS,ARS,BSM,VECM,VICM,BSM_MH,DCM,DMS,EBCM,ECM,ECP_MC,EOCM,EOCM_HC_Superset,EPSRAa,EPS,EPSb,FCM,HUD_CAN,LIB1,NVM,PCM,RDCM,TCCM,TCM,ECP_E,ECP_S,ECP_S2,ECP_X1
 SG_ NodeStsE5_LcFA : 10|1@0+ (1,0) [0|1] "" ACP2_MCU,ADIMb,AHL_AFL,AHS,ARS,BSM,VECM,VICM,BSM_MH,DCM,DMS,EBCM,ECM,ECP_MC,EOCM,EOCM_HC_Superset,EPSRAa,EPS,EPSb,FCM,HUD_CAN,LIB1,NVM,E44,PCM,RDCM,TCCM,TCM,ECP_E,ECP_S,ECP_S2,ECP_X1
 SG_ NodeStsAMP_LcFA : 11|1@0+ (1,0) [0|1] "" ACP2_MCU,ADIMa,ADIMb,AHL_AFL,AHS,ARS,BSM,VECM,VICM,BSM_MH,DCM,DMS,EBCM,ECM,ECP_MC,EOCM,EOCM_HC_Superset,EPSRAa,EPS,EPSb,FCM,HUD_CAN,LIB1,NVM,E44,PCM,RDCM,TCCM,TCM,ECP_E,ECP_S,ECP_S2,ECP_X1
 SG_ NodeStsALC_LcFA : 12|1@0+ (1,0) [0|1] "" ACP2_MCU,ADIMa,ADIMb,AHL_AFL,AHS,ARS,BSM,VECM,VICM,BSM_MH,DCM,DMS,EBCM,ECM,ECP_MC,EOCM,EOCM_HC_Superset,EPSRAa,EPS,EPSb,FCM,HUD_CAN,LIB1,NVM,E44,PCM,RDCM,TCCM,TCM,ECP_E,ECP_S,ECP_S2,ECP_X1
 SG_ NodeStsAHS_LcFA : 13|1@0+ (1,0) [0|1] "" ACP2_MCU,ADIMa,ADIMb,AHL_AFL,ARS,BSM,VECM,VICM,BSM_MH,DCM,DMS,EBCM,ECM,ECP_MC,EOCM,EOCM_HC_Superset,EPSRAa,EPS,EPSb,FCM,HUD_CAN,LIB1,NVM,E44,PCM,RDCM,TCCM,TCM,ECP_E,ECP_S,ECP_S2,ECP_X1
 SG_ NodeStsAHL_AFL_CAN_2_LcFA : 14|1@0+ (1,0) [0|1] "" ACP2_MCU,ADIMa,ADIMb,AHS,ARS,BSM,VECM,VICM,BSM_MH,DCM,DMS,EBCM,ECM,ECP_MC,EOCM,EOCM_HC_Superset,EPSRAa,EPS,EPSb,FCM,HUD_CAN,LIB1,NVM,E44,PCM,RDCM,TCCM,TCM,ECP_E,ECP_S,ECP_S2,ECP_X1
 SG_ NodeStsAGC_LcFA : 15|1@0+ (1,0) [0|1] "" ACP2_MCU,ADIMa,ADIMb,AHL_AFL,AHS,ARS,BSM,VECM,VICM,BSM_MH,DCM,DMS,EBCM,ECM,ECP_MC,EOCM,EOCM_HC_Superset,EPSRAa,EPS,EPSb,FCM,HUD_CAN,LIB1,NVM,E44,PCM,RDCM,TCCM,TCM,ECP_E,ECP_S,ECP_S2,ECP_X1
 SG_ NodeStsBSM_MH_LcFA : 17|1@0+ (1,0) [0|1] "" ACP2_MCU,ADIMa,ADIMb,AHL_AFL,AHS,ARS,BSM,VECM,VICM,DCM,DMS,EBCM,ECM,ECP_MC,EOCM,EOCM_HC_Superset,EPSRAa,EPS,EPSb,FCM,HUD_CAN,LIB1,NVM,E44,PCM,RDCM,TCCM,TCM,ECP_E,ECP_S,ECP_S2,ECP_X1
 SG_ NodeStsBSM_CAN_3_LcFA : 18|1@0+ (1,0) [0|1] "" ACP2_MCU,ADIMa,ADIMb,AHL_AFL,AHS,ARS,VECM,VICM,BSM_MH,DCM,DMS,EBCM,ECM,ECP_MC,EOCM,EOCM_HC_Superset,EPSRAa,EPS,EPSb,FCM,HUD_CAN,LIB1,NVM,E44,PCM,RDCM,TCCM,TCM,ECP_E,ECP_S,ECP_S2,ECP_X1
 SG_ NodeStsBSM_CAN_2_LcFA : 19|1@0+ (1,0) [0|1] "" ACP2_MCU,ADIMa,ADIMb,AHL_AFL,AHS,ARS,VECM,VICM,BSM_MH,DCM,DMS,EBCM,ECM,ECP_MC,EOCM,EOCM_HC_Superset,EPSRAa,EPS,EPSb,FCM,HUD_CAN,LIB1,NVM,E44,PCM,RDCM,TCCM,TCM,ECP_E,ECP_S,ECP_S2,ECP_X1
 SG_ NodeStsBCM_LcFA : 20|1@0+ (1,0) [0|1] "" ACP2_MCU,AHL_AFL,AHS,ARS,BSM,VECM,VICM,BSM_MH,DCM,DMS,EBCM,ECM,ECP_MC,EOCM,EOCM_HC_Superset,EPSRAa,EPS,EPSb,FCM,HUD_CAN,LIB1,NVM,PCM,RDCM,TCCM,TCM,ECP_E,ECP_S,ECP_S2,ECP_X1
 SG_ NodeStsARS_LcFA : 21|1@0+ (1,0) [0|1] "" ACP2_MCU,ADIMa,ADIMb,AHL_AFL,AHS,BSM,VECM,VICM,BSM_MH,DCM,DMS,EBCM,ECM,ECP_MC,EOCM,EOCM_HC_Superset,EPSRAa,EPS,EPSb,FCM,HUD_CAN,LIB1,NVM,E44,PCM,RDCM,TCCM,TCM,ECP_E,ECP_S,ECP_S2,ECP_X1
 SG_ NodeStsE8_LcFA : 22|1@0+ (1,0) [0|1] "" ACP2_MCU,ADIMa,ADIMb,AHL_AFL,AHS,ARS,BSM,VECM,VICM,BSM_MH,DCM,DMS,EBCM,ECM,ECP_MC,EOCM,EOCM_HC_Superset,EPSRAa,EPS,EPSb,FCM,HUD_CAN,LIB1,NVM,E44,PCM,RDCM,TCCM,TCM,ECP_E,ECP_S,ECP_S2,ECP_X1
 SG_ NodeStsAE44_CAN_2_LcFA : 23|1@0+ (1,0) [0|1] "" ACP2_MCU,ADIMa,ADIMb,AHL_AFL,AHS,ARS,BSM,VECM,VICM,BSM_MH,DCM,DMS,EBCM,ECM,ECP_MC,EOCM,EOCM_HC_Superset,EPSRAa,EPS,EPSb,FCM,HUD_CAN,LIB1,NVM,PCM,RDCM,TCCM,TCM,ECP_E,ECP_S,ECP_S2,ECP_X1
 SG_ NodeStsEBCM_AV_CAN_2_LcFA : 24|1@0+ (1,0) [0|1] "" ACP2_MCU,ADIMa,ADIMb,AHL_AFL,AHS,ARS,BSM,VECM,VICM,BSM_MH,DCM,DMS,EBCM,ECM,ECP_MC,EOCM,EOCM_HC_Superset,EPSRAa,EPS,EPSb,FCM,HUD_CAN,LIB1,NVM,E44,PCM,RDCM,TCCM,TCM,ECP_E,ECP_S,ECP_S2,ECP_X1
 SG_ NodeStsDMS_LcFA : 25|1@0+ (1,0) [0|1] "" ACP2_MCU,ADIMa,ADIMb,AHL_AFL,AHS,ARS,BSM,VECM,VICM,BSM_MH,DCM,EBCM,ECM,ECP_MC,EOCM,EOCM_HC_Superset,EPSRAa,EPS,EPSb,FCM,HUD_CAN,LIB1,NVM,E44,PCM,RDCM,TCCM,TCM,ECP_E,ECP_S,ECP_S2,ECP_X1
 SG_ NodeStsE12_LcFA : 26|1@0+ (1,0) [0|1] "" ACP2_MCU,ADIMa,ADIMb,AHL_AFL,AHS,ARS,BSM,VECM,VICM,BSM_MH,DCM,DMS,EBCM,ECM,ECP_MC,EOCM,EOCM_HC_Superset,EPSRAa,EPS,EPSb,FCM,HUD_CAN,LIB1,NVM,E44,PCM,RDCM,TCCM,TCM,ECP_E,ECP_S,ECP_S2,ECP_X1
 SG_ NodeStsDCM_LcFA : 27|1@0+ (1,0) [0|1] "" ACP2_MCU,ADIMa,ADIMb,AHL_AFL,AHS,ARS,BSM,VECM,VICM,BSM_MH,DMS,EBCM,ECM,ECP_MC,EOCM,EOCM_HC_Superset,EPSRAa,EPS,EPSb,FCM,HUD_CAN,LIB1,NVM,E44,PCM,RDCM,TCCM,TCM,ECP_E,ECP_S,ECP_S2,ECP_X1
 SG_ NodeStsCSM_CAN_5_LcFA : 28|1@0+ (1,0) [0|1] "" ACP2_MCU,ADIMa,ADIMb,AHL_AFL,AHS,ARS,BSM,VECM,VICM,BSM_MH,DCM,DMS,EBCM,ECM,ECP_MC,EOCM,EOCM_HC_Superset,EPSRAa,EPS,EPSb,FCM,HUD_CAN,LIB1,NVM,E44,PCM,RDCM,TCCM,TCM,ECP_E,ECP_S,ECP_S2,ECP_X1
 SG_ NodeStsECP_E_CAN_9_LcFA : 32|1@0+ (1,0) [0|1] "" ACP2_MCU,ADIMa,ADIMb,AHL_AFL,AHS,ARS,BSM,VECM,VICM,BSM_MH,DCM,DMS,EBCM,ECM,ECP_MC,EOCM,EOCM_HC_Superset,EPSRAa,EPS,EPSb,FCM,HUD_CAN,LIB1,NVM,E44,PCM,RDCM,TCCM,TCM,ECP_S,ECP_S2,ECP_X1
 SG_ NodeStsECP_E_CAN_2_LcFA : 33|1@0+ (1,0) [0|1] "" ACP2_MCU,ADIMa,ADIMb,AHL_AFL,AHS,ARS,BSM,VECM,VICM,BSM_MH,DCM,DMS,EBCM,ECM,ECP_MC,EOCM,EOCM_HC_Superset,EPSRAa,EPS,EPSb,FCM,HUD_CAN,LIB1,NVM,E44,PCM,RDCM,TCCM,TCM,ECP_S,ECP_S2,ECP_X1
 SG_ NodeStsECM_CAN_3_LcFA : 34|1@0+ (1,0) [0|1] "" ACP2_MCU,ADIMa,ADIMb,AHL_AFL,AHS,ARS,BSM,VECM,VICM,BSM_MH,DCM,DMS,EBCM,ECP_MC,EOCM,EOCM_HC_Superset,EPSRAa,EPS,EPSb,FCM,HUD_CAN,LIB1,NVM,E44,PCM,RDCM,TCCM,TCM,ECP_E,ECP_S,ECP_S2,ECP_X1
 SG_ NodeStsECM_CAN_2_LcFA : 35|1@0+ (1,0) [0|1] "" ACP2_MCU,ADIMa,ADIMb,AHL_AFL,AHS,ARS,BSM,VECM,VICM,BSM_MH,DCM,DMS,EBCM,ECP_MC,EOCM,EOCM_HC_Superset,EPSRAa,EPS,EPSb,FCM,HUD_CAN,LIB1,NVM,E44,PCM,RDCM,TCCM,TCM,ECP_E,ECP_S,ECP_S2,ECP_X1
 SG_ NodeStsEBCM_CAN_3_LcFA : 37|1@0+ (1,0) [0|1] "" ACP2_MCU,ADIMa,ADIMb,AHL_AFL,AHS,ARS,BSM,VECM,VICM,BSM_MH,DCM,DMS,EBCM,ECM,ECP_MC,EOCM,EOCM_HC_Superset,EPSRAa,EPS,EPSb,FCM,HUD_CAN,LIB1,NVM,E44,PCM,RDCM,TCCM,TCM,ECP_E,ECP_S,ECP_S2,ECP_X1
 SG_ NodeStsEBCM_CAN_2_LcFA : 38|1@0+ (1,0) [0|1] "" ACP2_MCU,ADIMa,ADIMb,AHL_AFL,AHS,ARS,BSM,VECM,VICM,BSM_MH,DCM,DMS,EBCM,ECM,ECP_MC,EOCM,EOCM_HC_Superset,EPSRAa,EPS,EPSb,FCM,HUD_CAN,LIB1,NVM,E44,PCM,RDCM,TCCM,TCM,ECP_E,ECP_S,ECP_S2,ECP_X1
 SG_ NodeStsEBCM_AV_CAN_3_LcFA : 39|1@0+ (1,0) [0|1] "" ACP2_MCU,ADIMa,ADIMb,AHL_AFL,AHS,ARS,BSM,VECM,VICM,BSM_MH,DCM,DMS,EBCM,ECM,ECP_MC,EOCM,EOCM_HC_Superset,EPSRAa,EPS,EPSb,FCM,HUD_CAN,LIB1,NVM,E44,PCM,RDCM,TCCM,TCM,ECP_E,ECP_S,ECP_S2,ECP_X1
 SG_ NodeStsEOCM_CAN_3_LcFA : 40|1@0+ (1,0) [0|1] "" ACP2_MCU,ADIMa,ADIMb,AHL_AFL,AHS,ARS,BSM,VECM,VICM,BSM_MH,DCM,DMS,EBCM,ECM,ECP_MC,EOCM_HC_Superset,EPSRAa,EPS,EPSb,FCM,HUD_CAN,LIB1,NVM,E44,PCM,RDCM,TCCM,TCM,ECP_E,ECP_S,ECP_S2,ECP_X1
 SG_ NodeStsEOCM_CAN_2_LcFA : 41|1@0+ (1,0) [0|1] "" ACP2_MCU,ADIMa,ADIMb,AHL_AFL,AHS,ARS,BSM,VECM,VICM,BSM_MH,DCM,DMS,EBCM,ECM,ECP_MC,EOCM_HC_Superset,EPSRAa,EPS,EPSb,FCM,HUD_CAN,LIB1,NVM,E44,PCM,RDCM,TCCM,TCM,ECP_E,ECP_S,ECP_S2,ECP_X1
 SG_ NodeStsELM_LcFA : 42|1@0+ (1,0) [0|1] "" ACP2_MCU,ADIMa,ADIMb,AHL_AFL,AHS,ARS,BSM,VECM,VICM,BSM_MH,DCM,DMS,EBCM,ECM,ECP_MC,EOCM,EOCM_HC_Superset,EPSRAa,EPS,EPSb,FCM,HUD_CAN,LIB1,NVM,E44,PCM,RDCM,TCCM,TCM,ECP_E,ECP_S,ECP_S2,ECP_X1
 SG_ NodeStsECP_X1_CAN_3_LcFA : 43|1@0+ (1,0) [0|1] "" ACP2_MCU,ADIMa,ADIMb,AHL_AFL,AHS,ARS,BSM,VECM,VICM,BSM_MH,DCM,DMS,EBCM,ECM,ECP_MC,EOCM,EOCM_HC_Superset,EPSRAa,EPS,EPSb,FCM,HUD_CAN,LIB1,NVM,E44,PCM,RDCM,TCCM,TCM,ECP_E,ECP_S,ECP_S2
 SG_ NodeStsECP_X1_CAN_2_LcFA : 44|1@0+ (1,0) [0|1] "" ACP2_MCU,ADIMa,ADIMb,AHL_AFL,AHS,ARS,BSM,VECM,VICM,BSM_MH,DCM,DMS,EBCM,ECM,ECP_MC,EOCM,EOCM_HC_Superset,EPSRAa,EPS,EPSb,FCM,HUD_CAN,LIB1,NVM,E44,PCM,RDCM,TCCM,TCM,ECP_E,ECP_S,ECP_S2
 SG_ NodeStsECP_S_CAN_9_LcFA : 45|1@0+ (1,0) [0|1] "" ACP2_MCU,ADIMa,ADIMb,AHL_AFL,AHS,ARS,BSM,VECM,VICM,BSM_MH,DCM,DMS,EBCM,ECM,ECP_MC,EOCM,EOCM_HC_Superset,EPSRAa,EPS,EPSb,FCM,HUD_CAN,LIB1,NVM,E44,PCM,RDCM,TCCM,TCM,ECP_E,ECP_S2,ECP_X1
 SG_ NodeStsECP_S_CAN_2_LcFA : 46|1@0+ (1,0) [0|1] "" ACP2_MCU,ADIMa,ADIMb,AHL_AFL,AHS,ARS,BSM,VECM,VICM,BSM_MH,DCM,DMS,EBCM,ECM,ECP_MC,EOCM,EOCM_HC_Superset,EPSRAa,EPS,EPSb,FCM,HUD_CAN,LIB1,NVM,E44,PCM,RDCM,TCCM,TCM,ECP_E,ECP_S2,ECP_X1
 SG_ NodeStsECP_MC_LcFA : 47|1@0+ (1,0) [0|1] "" ACP2_MCU,ADIMa,ADIMb,AHL_AFL,AHS,ARS,BSM,VECM,VICM,BSM_MH,DCM,DMS,EBCM,ECM,EOCM,EOCM_HC_Superset,EPSRAa,EPS,EPSb,FCM,HUD_CAN,LIB1,NVM,E44,PCM,RDCM,TCCM,TCM,ECP_E,ECP_S,ECP_S2,ECP_X1
 SG_ NodeStsEPSRAa_LcFA : 48|1@0+ (1,0) [0|1] "" ACP2_MCU,ADIMa,ADIMb,AHL_AFL,AHS,ARS,BSM,VECM,VICM,BSM_MH,DCM,DMS,EBCM,ECM,ECP_MC,EOCM,EOCM_HC_Superset,EPS,EPSb,FCM,HUD_CAN,LIB1,NVM,E44,PCM,RDCM,TCCM,TCM,ECP_E,ECP_S,ECP_S2,ECP_X1
 SG_ NodeStsEPS_LcFA : 49|1@0+ (1,0) [0|1] "" ACP2_MCU,ADIMa,ADIMb,AHL_AFL,AHS,ARS,BSM,VECM,VICM,BSM_MH,DCM,DMS,EBCM,ECM,ECP_MC,EOCM,EOCM_HC_Superset,EPSRAa,EPSb,FCM,HUD_CAN,LIB1,NVM,E44,PCM,RDCM,TCCM,TCM,ECP_E,ECP_S,ECP_S2,ECP_X1
 SG_ NodeStsE19_LcFA : 50|1@0+ (1,0) [0|1] "" ACP2_MCU,ADIMa,ADIMb,AHL_AFL,AHS,ARS,BSM,VECM,VICM,BSM_MH,DCM,DMS,EBCM,ECM,ECP_MC,EOCM,EOCM_HC_Superset,EPSRAa,EPS,EPSb,FCM,HUD_CAN,LIB1,NVM,E44,PCM,RDCM,TCCM,TCM,VDM,ECP_E,ECP_S,ECP_S2,ECP_X1
 SG_ NodeStsEOCM_HCP2_LcFA : 51|1@0+ (1,0) [0|1] "" ACP2_MCU,ADIMa,ADIMb,AHL_AFL,AHS,ARS,BSM,VECM,VICM,BSM_MH,DCM,DMS,EBCM,ECM,ECP_MC,EOCM,EOCM_HC_Superset,EPSRAa,EPS,EPSb,FCM,HUD_CAN,LIB1,NVM,E44,PCM,RDCM,TCCM,TCM,ECP_E,ECP_S,ECP_S2,ECP_X1
 SG_ NodeStsEOCM_HCP1_CAN_8_LcFA : 52|1@0+ (1,0) [0|1] "" ACP2_MCU,ADIMa,ADIMb,AHL_AFL,AHS,ARS,BSM,VECM,VICM,BSM_MH,DCM,DMS,EBCM,ECM,ECP_MC,EOCM,EOCM_HC_Superset,EPSRAa,EPS,EPSb,FCM,HUD_CAN,LIB1,NVM,E44,PCM,RDCM,TCCM,TCM,ECP_E,ECP_S,ECP_S2,ECP_X1
 SG_ NodeStsEOCM_HCP1_CAN_3_LcFA : 53|1@0+ (1,0) [0|1] "" ACP2_MCU,ADIMa,ADIMb,AHL_AFL,AHS,ARS,BSM,VECM,VICM,BSM_MH,DCM,DMS,EBCM,ECM,ECP_MC,EOCM,EOCM_HC_Superset,EPSRAa,EPS,EPSb,FCM,HUD_CAN,LIB1,NVM,E44,PCM,RDCM,TCCM,TCM,ECP_E,ECP_S,ECP_S2,ECP_X1
 SG_ NodeStsEOCM_HCP1_CAN_2_LcFA : 54|1@0+ (1,0) [0|1] "" ACP2_MCU,ADIMa,ADIMb,AHL_AFL,AHS,ARS,BSM,VECM,VICM,BSM_MH,DCM,DMS,EBCM,ECM,ECP_MC,EOCM,EOCM_HC_Superset,EPSRAa,EPS,EPSb,FCM,HUD_CAN,LIB1,NVM,E44,PCM,RDCM,TCCM,TCM,ECP_E,ECP_S,ECP_S2,ECP_X1
 SG_ NodeStsEOCM_CAN_8_LcFA : 55|1@0+ (1,0) [0|1] "" ACP2_MCU,ADIMa,ADIMb,AHL_AFL,AHS,ARS,BSM,VECM,VICM,BSM_MH,DCM,DMS,EBCM,ECM,ECP_MC,EOCM_HC_Superset,EPSRAa,EPS,EPSb,FCM,HUD_CAN,LIB1,NVM,E44,PCM,RDCM,TCCM,TCM,ECP_E,ECP_S,ECP_S2,ECP_X1
 SG_ NodeStsHVAC_FP_F_LcFA : 56|1@0+ (1,0) [0|1] "" ACP2_MCU,ADIMa,ADIMb,AHL_AFL,AHS,ARS,BSM,VECM,VICM,BSM_MH,DCM,DMS,EBCM,ECM,ECP_MC,EOCM,EOCM_HC_Superset,EPSRAa,EPS,EPSb,FCM,HUD_CAN,LIB1,NVM,E44,PCM,RDCM,TCCM,TCM,ECP_E,ECP_S,ECP_S2,ECP_X1
 SG_ NodeStsHUD_CAN_LcFA : 57|1@0+ (1,0) [0|1] "" ACP2_MCU,ADIMa,ADIMb,AHL_AFL,AHS,ARS,BSM,VECM,VICM,BSM_MH,DCM,DMS,EBCM,ECM,ECP_MC,EOCM,EOCM_HC_Superset,EPSRAa,EPS,EPSb,FCM,LIB1,NVM,E44,PCM,RDCM,TCCM,TCM,ECP_E,ECP_S,ECP_S2,ECP_X1
 SG_ NodeStsE22_LcFA : 58|1@0+ (1,0) [0|1] "" ACP2_MCU,ADIMa,ADIMb,AHL_AFL,AHS,ARS,BSM,VECM,VICM,BSM_MH,DCM,DMS,EBCM,ECM,ECP_MC,EOCM,EOCM_HC_Superset,EPSRAa,EPS,EPSb,FCM,HUD_CAN,LIB1,NVM,E44,PCM,RDCM,TCCM,TCM,ECP_E,ECP_S,ECP_S2,ECP_X1
 SG_ NodeStsFOPM_CAN_3_LcFA : 59|1@0+ (1,0) [0|1] "" ACP2_MCU,ADIMa,ADIMb,AHL_AFL,AHS,ARS,BSM,VECM,VICM,BSM_MH,DCM,DMS,EBCM,ECM,ECP_MC,EOCM,EOCM_HC_Superset,EPSRAa,EPS,EPSb,FCM,HUD_CAN,LIB1,NVM,E44,PCM,RDCM,TCCM,TCM,ECP_E,ECP_S,ECP_S2,ECP_X1
 SG_ NodeStsFOPM_CAN_2_LcFA : 60|1@0+ (1,0) [0|1] "" ACP2_MCU,ADIMa,ADIMb,AHL_AFL,AHS,ARS,BSM,VECM,VICM,BSM_MH,DCM,DMS,EBCM,ECM,ECP_MC,EOCM,EOCM_HC_Superset,EPSRAa,EPS,EPSb,FCM,HUD_CAN,LIB1,NVM,E44,PCM,RDCM,TCCM,TCM,ECP_E,ECP_S,ECP_S2,ECP_X1
 SG_ NodeStsFCM_LcFA : 61|1@0+ (1,0) [0|1] "" ACP2_MCU,ADIMa,ADIMb,AHL_AFL,AHS,ARS,BSM,VECM,VICM,BSM_MH,DCM,DMS,EBCM,ECM,ECP_MC,EOCM,EOCM_HC_Superset,EPSRAa,EPS,EPSb,HUD_CAN,LIB1,NVM,E44,PCM,RDCM,TCCM,TCM,ECP_E,ECP_S,ECP_S2,ECP_X1
 SG_ NodeStsFCM_LC_LcFA : 62|1@0+ (1,0) [0|1] "" ACP2_MCU,ADIMa,ADIMb,AHL_AFL,AHS,ARS,BSM,VECM,VICM,BSM_MH,DCM,DMS,EBCM,ECM,ECP_MC,EOCM,EOCM_HC_Superset,EPSRAa,EPS,EPSb,FCM,HUD_CAN,LIB1,NVM,E44,PCM,RDCM,TCCM,TCM,ECP_E,ECP_S,ECP_S2,ECP_X1
 SG_ NodeStsE20_LcFA : 63|1@0+ (1,0) [0|1] "" ACP2_MCU,ADIMa,ADIMb,AHL_AFL,AHS,ARS,BSM,VECM,VICM,BSM_MH,DCM,DMS,EBCM,ECM,ECP_MC,EOCM,EOCM_HC_Superset,EPSRAa,EPS,EPSb,FCM,HUD_CAN,LIB1,NVM,E44,PCM,RDCM,TCCM,TCM,ECP_E,ECP_S,ECP_S2,ECP_X1

BO_ 964 NodeStatus_CAN2_PDU02: 8 Vector__XXX
 SG_ NodeStsMFC_LcFA : 0|1@0+ (1,0) [0|1] "" ACP2_MCU,ADIMa,ADIMb,AHL_AFL,AHS,ARS,BSM,VECM,VICM,BSM_MH,DCM,DMS,EBCM,ECM,ECP_MC,EOCM,EOCM_HC_Superset,EPSRAa,EPS,EPSb,FCM,HUD_CAN,LIB1,NVM,E44,PCM,RDCM,TCCM,TCM,ECP_E,ECP_S,ECP_S2,ECP_X1
 SG_ NodeStsLRR_LcFA : 1|1@0+ (1,0) [0|1] "" ACP2_MCU,ADIMa,ADIMb,AHL_AFL,AHS,ARS,BSM,VECM,VICM,BSM_MH,DCM,DMS,EBCM,ECM,ECP_MC,EOCM,EOCM_HC_Superset,EPSRAa,EPS,EPSb,FCM,HUD_CAN,LIB1,NVM,E44,PCM,RDCM,TCCM,TCM,ECP_E,ECP_S,ECP_S2,ECP_X1
 SG_ NodeStsLIB1_LcFA : 3|1@0+ (1,0) [0|1] "" ACP2_MCU,ADIMa,ADIMb,AHL_AFL,AHS,ARS,BSM,VECM,VICM,BSM_MH,DCM,DMS,EBCM,ECM,ECP_MC,EOCM,EOCM_HC_Superset,EPSRAa,EPS,EPSb,FCM,HUD_CAN,NVM,E44,PCM,RDCM,TCCM,TCM,ECP_E,ECP_S,ECP_S2,ECP_X1
 SG_ NodeStsIPC_CAN_5_LcFA : 4|1@0+ (1,0) [0|1] "" ACP2_MCU,ADIMa,ADIMb,AHL_AFL,AHS,ARS,BSM,VECM,VICM,BSM_MH,DCM,DMS,EBCM,ECM,ECP_MC,EOCM,EOCM_HC_Superset,EPSRAa,EPS,EPSb,FCM,HUD_CAN,LIB1,NVM,PCM,RDCM,TCCM,TCM,ECP_E,ECP_S,ECP_S2,ECP_X1
 SG_ NodeStsICS_Info_LcFA : 5|1@0+ (1,0) [0|1] "" ACP2_MCU,ADIMa,ADIMb,AHL_AFL,AHS,ARS,BSM,VECM,VICM,BSM_MH,DCM,DMS,EBCM,ECM,ECP_MC,EOCM,EOCM_HC_Superset,EPSRAa,EPS,EPSb,FCM,HUD_CAN,LIB1,NVM,E44,PCM,RDCM,TCCM,TCM,ECP_E,ECP_S,ECP_S2,ECP_X1
 SG_ NodeStsICCM_CAN_3_LcFA : 6|1@0+ (1,0) [0|1] "" ACP2_MCU,ADIMa,ADIMb,AHL_AFL,AHS,ARS,BSM,VECM,VICM,BSM_MH,DCM,DMS,EBCM,ECM,ECP_MC,EOCM,EOCM_HC_Superset,EPSRAa,EPS,EPSb,FCM,HUD_CAN,LIB1,NVM,E44,PCM,RDCM,TCCM,TCM,ECP_E,ECP_S,ECP_S2,ECP_X1
 SG_ NodeStsHVAC_FP_R_LcFA : 7|1@0+ (1,0) [0|1] "" ACP2_MCU,ADIMa,ADIMb,AHL_AFL,AHS,ARS,BSM,VECM,VICM,BSM_MH,DCM,DMS,EBCM,ECM,ECP_MC,EOCM,EOCM_HC_Superset,EPSRAa,EPS,EPSb,FCM,HUD_CAN,LIB1,NVM,E44,PCM,RDCM,TCCM,TCM,ECP_E,ECP_S,ECP_S2,ECP_X1
 SG_ NodeStsE38_LcFA : 8|1@0+ (1,0) [0|1] "" ACP2_MCU,ADIMa,ADIMb,AHL_AFL,AHS,ARS,BSM,VECM,VICM,BSM_MH,DCM,DMS,EBCM,ECM,ECP_MC,EOCM,EOCM_HC_Superset,EPSRAa,EPS,EPSb,FCM,HUD_CAN,LIB1,NVM,E44,PCM,RDCM,TCCM,TCM,ECP_E,ECP_S,ECP_S2,ECP_X1
 SG_ NodeStsE37_LcFA : 9|1@0+ (1,0) [0|1] "" ACP2_MCU,ADIMa,ADIMb,AHL_AFL,AHS,ARS,BSM,VECM,VICM,BSM_MH,DCM,DMS,EBCM,ECM,ECP_MC,EOCM,EOCM_HC_Superset,EPSRAa,EPS,EPSb,FCM,HUD_CAN,LIB1,NVM,E44,PCM,RDCM,TCCM,TCM,ECP_E,ECP_S,ECP_S2,ECP_X1
 SG_ NodeStsE36_LcFA : 10|1@0+ (1,0) [0|1] "" ACP2_MCU,ADIMa,ADIMb,AHL_AFL,AHS,ARS,BSM,VECM,VICM,BSM_MH,DCM,DMS,EBCM,ECM,ECP_MC,EOCM,EOCM_HC_Superset,EPSRAa,EPS,EPSb,FCM,HUD_CAN,LIB1,NVM,E44,PCM,RDCM,TCCM,TCM,ECP_E,ECP_S,ECP_S2,ECP_X1
 SG_ NodeStsE35_LcFA : 11|1@0+ (1,0) [0|1] "" ACP2_MCU,ADIMa,ADIMb,AHL_AFL,AHS,ARS,BSM,VECM,VICM,BSM_MH,DCM,DMS,EBCM,ECM,ECP_MC,EOCM,EOCM_HC_Superset,EPSRAa,EPS,EPSb,FCM,HUD_CAN,LIB1,NVM,E44,PCM,RDCM,TCCM,TCM,ECP_E,ECP_S,ECP_S2,ECP_X1
 SG_ NodeStsE34_LcFA : 12|1@0+ (1,0) [0|1] "" ACP2_MCU,ADIMa,ADIMb,AHL_AFL,AHS,ARS,BSM,VECM,VICM,BSM_MH,DCM,DMS,EBCM,ECM,ECP_MC,EOCM,EOCM_HC_Superset,EPSRAa,EPS,EPSb,FCM,HUD_CAN,LIB1,NVM,E44,PCM,RDCM,TCCM,TCM,ECP_E,ECP_S,ECP_S2,ECP_X1
 SG_ NodeStsE33_LcFA : 13|1@0+ (1,0) [0|1] "" ACP2_MCU,ADIMa,ADIMb,AHL_AFL,AHS,ARS,BSM,VECM,VICM,BSM_MH,DCM,DMS,EBCM,ECM,ECP_MC,EOCM,EOCM_HC_Superset,EPSRAa,EPS,EPSb,FCM,HUD_CAN,LIB1,NVM,E44,PCM,RDCM,TCCM,TCM,ECP_E,ECP_S,ECP_S2,ECP_X1
 SG_ NodeStsE32_LcFA : 14|1@0+ (1,0) [0|1] "" ACP2_MCU,ADIMa,ADIMb,AHL_AFL,AHS,ARS,BSM,VECM,VICM,BSM_MH,DCM,DMS,EBCM,ECM,ECP_MC,EOCM,EOCM_HC_Superset,EPSRAa,EPS,EPSb,FCM,HUD_CAN,LIB1,NVM,E44,PCM,RDCM,TCCM,TCM,ECP_E,ECP_S,ECP_S2,ECP_X1
 SG_ NodeStsE31_LcFA : 15|1@0+ (1,0) [0|1] "" ACP2_MCU,ADIMa,ADIMb,AHL_AFL,AHS,ARS,BSM,VECM,VICM,BSM_MH,DCM,DMS,EBCM,ECM,ECP_MC,EOCM,EOCM_HC_Superset,EPSRAa,EPS,EPSb,FCM,HUD_CAN,LIB1,NVM,E44,PCM,RDCM,TCCM,TCM,ECP_E,ECP_S,ECP_S2,ECP_X1
 SG_ NodeStsRDCM_LcFA : 16|1@0+ (1,0) [0|1] "" ACP2_MCU,ADIMa,ADIMb,AHL_AFL,AHS,ARS,BSM,VECM,VICM,BSM_MH,DCM,DMS,EBCM,ECM,ECP_MC,EOCM,EOCM_HC_Superset,EPSRAa,EPS,EPSb,FCM,HUD_CAN,LIB1,NVM,E44,PCM,TCCM,TCM,ECP_E,ECP_S,ECP_S2,ECP_X1
 SG_ NodeStsRadioLow_LcFA : 17|1@0+ (1,0) [0|1] "" ACP2_MCU,ADIMa,ADIMb,AHL_AFL,AHS,ARS,BSM,VECM,VICM,BSM_MH,DCM,DMS,EBCM,ECM,ECP_MC,EOCM,EOCM_HC_Superset,EPSRAa,EPS,EPSb,FCM,HUD_CAN,LIB1,NVM,PCM,RDCM,TCCM,TCM,ECP_E,ECP_S,ECP_S2,ECP_X1
 SG_ NodeStsE48_LcFA : 18|1@0+ (1,0) [0|1] "" ACP2_MCU,AHL_AFL,AHS,ARS,BSM,VECM,VICM,BSM_MH,DCM,DMS,EBCM,ECM,ECP_MC,EOCM,EOCM_HC_Superset,EPSRAa,EPS,EPSb,FCM,HUD_CAN,LIB1,NVM,E44,PCM,RDCM,TCCM,TCM,ECP_E,ECP_S,ECP_S2,ECP_X1
 SG_ NodeStsPDR_LcFA : 19|1@0+ (1,0) [0|1] "" ACP2_MCU,ADIMa,ADIMb,AHL_AFL,AHS,ARS,BSM,VECM,VICM,BSM_MH,DCM,DMS,EBCM,ECM,ECP_MC,EOCM,EOCM_HC_Superset,EPSRAa,EPS,EPSb,FCM,HUD_CAN,LIB1,NVM,E44,PCM,RDCM,TCCM,TCM,ECP_E,ECP_S,ECP_S2,ECP_X1
 SG_ NodeStsE44_LcFA : 20|1@0+ (1,0) [0|1] "" ACP2_MCU,ADIMa,ADIMb,AHL_AFL,AHS,ARS,BSM,VECM,VICM,BSM_MH,DCM,DMS,EBCM,ECM,ECP_MC,EOCM,EOCM_HC_Superset,EPSRAa,EPS,EPSb,FCM,HUD_CAN,LIB1,NVM,E44,PCM,RDCM,TCCM,TCM,ECP_E,ECP_S,ECP_S2,ECP_X1
 SG_ NodeStsNVM_LcFA : 21|1@0+ (1,0) [0|1] "" ACP2_MCU,ADIMa,ADIMb,AHL_AFL,AHS,ARS,BSM,VECM,VICM,BSM_MH,DCM,DMS,EBCM,ECM,ECP_MC,EOCM,EOCM_HC_Superset,EPSRAa,EPS,EPSb,FCM,HUD_CAN,LIB1,E44,PCM,RDCM,TCCM,TCM,ECP_E,ECP_S,ECP_S2,ECP_X1
 SG_ NodeStsE40_LcFA : 22|1@0+ (1,0) [0|1] "" ACP2_MCU,ADIMa,ADIMb,AHL_AFL,AHS,ARS,BSM,VECM,VICM,BSM_MH,DCM,DMS,EBCM,ECM,ECP_MC,EOCM,EOCM_HC_Superset,EPSRAa,EPS,EPSb,FCM,HUD_CAN,LIB1,NVM,E44,PCM,RDCM,TCCM,TCM,ECP_E,ECP_S,ECP_S2,ECP_X1
 SG_ NodeStsE39_LcFA : 23|1@0+ (1,0) [0|1] "" ACP2_MCU,ADIMa,ADIMb,AHL_AFL,AHS,ARS,BSM,VECM,VICM,BSM_MH,DCM,DMS,EBCM,ECM,ECP_MC,EOCM,EOCM_HC_Superset,EPSRAa,EPS,EPSb,FCM,HUD_CAN,LIB1,NVM,E44,PCM,RDCM,TCCM,TCM,ECP_E,ECP_S,ECP_S2,ECP_X1
 SG_ Sig4413 : 25|1@0+ (1,0) [0|1] "" Vector__XXX
 SG_ NodeStsE53_LcFA : 26|1@0+ (1,0) [0|1] "" ACP2_MCU,ADIMb,AHL_AFL,AHS,ARS,BSM,VECM,VICM,BSM_MH,DCM,DMS,EBCM,ECM,ECP_MC,EOCM,EOCM_HC_Superset,EPSRAa,EPS,EPSb,FCM,HUD_CAN,LIB1,NVM,E44,PCM,RDCM,TCCM,TCM,ECP_E,ECP_S,ECP_S2,ECP_X1
 SG_ NodeStsE52_LcFA : 27|1@0+ (1,0) [0|1] "" ACP2_MCU,ADIMb,AHL_AFL,AHS,ARS,BSM,VECM,VICM,BSM_MH,DCM,DMS,EBCM,ECM,ECP_MC,EOCM,EOCM_HC_Superset,EPSRAa,EPS,EPSb,FCM,HUD_CAN,LIB1,NVM,E44,PCM,RDCM,TCCM,TCM,ECP_E,ECP_S,ECP_S2,ECP_X1
 SG_ NodeStsE51_LcFA : 28|1@0+ (1,0) [0|1] "" ACP2_MCU,ADIMb,AHL_AFL,AHS,ARS,BSM,VECM,VICM,BSM_MH,DCM,DMS,EBCM,ECM,ECP_MC,EOCM,EOCM_HC_Superset,EPSRAa,EPS,EPSb,FCM,HUD_CAN,LIB1,NVM,E44,PCM,RDCM,TCCM,TCM,ECP_E,ECP_S,ECP_S2,ECP_X1
 SG_ NodeStsE50_LcFA : 29|1@0+ (1,0) [0|1] "" ACP2_MCU,ADIMb,AHL_AFL,AHS,ARS,BSM,VECM,VICM,BSM_MH,DCM,DMS,EBCM,ECM,ECP_MC,EOCM,EOCM_HC_Superset,EPSRAa,EPS,EPSb,FCM,HUD_CAN,LIB1,NVM,E44,PCM,RDCM,TCCM,TCM,ECP_E,ECP_S,ECP_S2,ECP_X1
 SG_ NodeStsSADS_LcFA : 30|1@0+ (1,0) [0|1] "" ACP2_MCU,ADIMa,ADIMb,AHL_AFL,AHS,ARS,BSM,VECM,VICM,BSM_MH,DCM,DMS,EBCM,ECM,ECP_MC,EOCM,EOCM_HC_Superset,EPSRAa,EPS,EPSb,FCM,HUD_CAN,LIB1,NVM,E44,PCM,RDCM,TCCM,TCM,ECP_E,ECP_S,ECP_S2,ECP_X1
 SG_ NodeStsRSC_LcFA : 31|1@0+ (1,0) [0|1] "" ACP2_MCU,ADIMa,ADIMb,AHL_AFL,AHS,ARS,BSM,VECM,VICM,BSM_MH,DCM,DMS,EBCM,ECM,ECP_MC,EOCM,EOCM_HC_Superset,EPSRAa,EPS,EPSb,FCM,HUD_CAN,LIB1,NVM,E44,PCM,RDCM,TCCM,TCM,ECP_E,ECP_S,ECP_S2,ECP_X1
 SG_ NodeStsSRR_RF_LcFA : 32|1@0+ (1,0) [0|1] "" ACP2_MCU,ADIMa,ADIMb,AHL_AFL,AHS,ARS,BSM,VECM,VICM,BSM_MH,DCM,DMS,EBCM,ECM,ECP_MC,EOCM,EOCM_HC_Superset,EPSRAa,EPS,EPSb,FCM,HUD_CAN,LIB1,NVM,E44,PCM,RDCM,TCCM,TCM,ECP_E,ECP_S,ECP_S2,ECP_X1
 SG_ NodeStsSRR_LR_CR_LcFA : 33|1@0+ (1,0) [0|1] "" ACP2_MCU,ADIMa,ADIMb,AHL_AFL,AHS,ARS,BSM,VECM,VICM,BSM_MH,DCM,DMS,EBCM,ECM,ECP_MC,EOCM,EOCM_HC_Superset,EPSRAa,EPS,EPSb,FCM,HUD_CAN,LIB1,NVM,E44,PCM,RDCM,TCCM,TCM,ECP_E,ECP_S,ECP_S2,ECP_X1
 SG_ NodeStsSRR_LF_LcFA : 34|1@0+ (1,0) [0|1] "" ACP2_MCU,ADIMa,ADIMb,AHL_AFL,AHS,ARS,BSM,VECM,VICM,BSM_MH,DCM,DMS,EBCM,ECM,ECP_MC,EOCM,EOCM_HC_Superset,EPSRAa,EPS,EPSb,FCM,HUD_CAN,LIB1,NVM,E44,PCM,RDCM,TCCM,TCM,ECP_E,ECP_S,ECP_S2,ECP_X1
 SG_ NodeStsSIB_LcFA : 35|1@0+ (1,0) [0|1] "" ACP2_MCU,ADIMa,ADIMb,AHL_AFL,AHS,ARS,BSM,VECM,VICM,BSM_MH,DCM,DMS,EBCM,ECM,ECP_MC,EOCM,EOCM_HC_Superset,EPSRAa,EPS,EPSb,FCM,HUD_CAN,LIB1,NVM,E44,PCM,RDCM,TCCM,TCM,ECP_E,ECP_S,ECP_S2,ECP_X1
 SG_ NodeStsSDM_LcFA : 36|1@0+ (1,0) [0|1] "" ACP2_MCU,ADIMa,ADIMb,AHL_AFL,AHS,ARS,BSM,VECM,VICM,BSM_MH,DCM,DMS,EBCM,ECM,ECP_MC,EOCM,EOCM_HC_Superset,EPSRAa,EPS,EPSb,FCM,HUD_CAN,LIB1,NVM,E44,PCM,RDCM,TCCM,TCM,ECP_E,ECP_S,ECP_S2,ECP_X1
 SG_ NodeStsE56_LcFA : 37|1@0+ (1,0) [0|1] "" ACP2_MCU,ADIMa,ADIMb,AHL_AFL,AHS,ARS,BSM,VECM,VICM,BSM_MH,DCM,DMS,EBCM,ECM,ECP_MC,EOCM,EOCM_HC_Superset,EPSRAa,EPS,EPSb,FCM,HUD_CAN,LIB1,NVM,E44,PCM,RDCM,TCCM,TCM,ECP_E,ECP_S,ECP_S2,ECP_X1
 SG_ NodeStsE55_LcFA : 38|1@0+ (1,0) [0|1] "" ACP2_MCU,ADIMa,ADIMb,AHL_AFL,AHS,ARS,BSM,VECM,VICM,BSM_MH,DCM,DMS,EBCM,ECM,ECP_MC,EOCM,EOCM_HC_Superset,EPSRAa,EPS,EPSb,FCM,HUD_CAN,LIB1,NVM,E44,PCM,RDCM,TCCM,TCM,ECP_E,ECP_S,ECP_S2,ECP_X1
 SG_ NodeStsE54_LcFA : 39|1@0+ (1,0) [0|1] "" ACP2_MCU,ADIMa,ADIMb,AHL_AFL,AHS,ARS,BSM,VECM,VICM,BSM_MH,DCM,DMS,EBCM,ECM,ECP_MC,EOCM,EOCM_HC_Superset,EPSRAa,EPS,EPSb,FCM,HUD_CAN,LIB1,NVM,E44,PCM,RDCM,TCCM,TCM,ECP_E,ECP_S,ECP_S2,ECP_X1
 SG_ NodeStsTCP_CAN_5_LcFA : 40|1@0+ (1,0) [0|1] "" ACP2_MCU,ADIMa,ADIMb,AHL_AFL,AHS,ARS,BSM,VECM,VICM,BSM_MH,DCM,DMS,EBCM,ECM,ECP_MC,EOCM,EOCM_HC_Superset,EPSRAa,EPS,EPSb,FCM,HUD_CAN,LIB1,NVM,E44,PCM,RDCM,TCCM,TCM,VDM,ECP_E,ECP_S,ECP_S2,ECP_X1
 SG_ NodeStsTCM_CAN_2_LcFA : 41|1@0+ (1,0) [0|1] "" ACP2_MCU,ADIMa,ADIMb,AHL_AFL,AHS,ARS,BSM,VECM,VICM,BSM_MH,DCM,DMS,EBCM,ECM,ECP_MC,EOCM,EOCM_HC_Superset,EPSRAa,EPS,EPSb,FCM,HUD_CAN,LIB1,NVM,E44,PCM,RDCM,TCCM,ECP_E,ECP_S,ECP_S2,ECP_X1
 SG_ NodeStsTCCM_LcFA : 43|1@0+ (1,0) [0|1] "" ACP2_MCU,ADIMa,ADIMb,AHL_AFL,AHS,ARS,BSM,VECM,VICM,BSM_MH,DCM,DMS,EBCM,ECM,ECP_MC,EOCM,EOCM_HC_Superset,EPSRAa,EPS,EPSb,FCM,HUD_CAN,LIB1,NVM,E44,PCM,RDCM,TCM,ECP_E,ECP_S,ECP_S2,ECP_X1
 SG_ NodeStsE57_LcFA : 44|1@0+ (1,0) [0|1] "" ACP2_MCU,ADIMa,ADIMb,AHL_AFL,AHS,ARS,BSM,VECM,VICM,BSM_MH,DCM,DMS,EBCM,ECM,ECP_MC,EOCM,EOCM_HC_Superset,EPSRAa,EPS,EPSb,FCM,HUD_CAN,LIB1,NVM,E44,PCM,RDCM,TCCM,TCM,ECP_E,ECP_S,ECP_S2,ECP_X1
 SG_ NodeStsSRR_SRR_LcFA : 45|1@0+ (1,0) [0|1] "" ACP2_MCU,ADIMa,ADIMb,AHL_AFL,AHS,ARS,BSM,VECM,VICM,BSM_MH,DCM,DMS,EBCM,ECM,ECP_MC,EOCM,EOCM_HC_Superset,EPSRAa,EPS,EPSb,FCM,HUD_CAN,LIB1,NVM,E44,PCM,RDCM,TCCM,TCM,ECP_E,ECP_S,ECP_S2,ECP_X1
 SG_ NodeStsSRR_SLR_LcFA : 46|1@0+ (1,0) [0|1] "" ACP2_MCU,ADIMa,ADIMb,AHL_AFL,AHS,ARS,BSM,VECM,VICM,BSM_MH,DCM,DMS,EBCM,ECM,ECP_MC,EOCM,EOCM_HC_Superset,EPSRAa,EPS,EPSb,FCM,HUD_CAN,LIB1,NVM,E44,PCM,RDCM,TCCM,TCM,ECP_E,ECP_S,ECP_S2,ECP_X1
 SG_ NodeStsSRR_RR_LcFA : 47|1@0+ (1,0) [0|1] "" ACP2_MCU,ADIMa,ADIMb,AHL_AFL,AHS,ARS,BSM,VECM,VICM,BSM_MH,DCM,DMS,EBCM,ECM,ECP_MC,EOCM,EOCM_HC_Superset,EPSRAa,EPS,EPSb,FCM,HUD_CAN,LIB1,NVM,E44,PCM,RDCM,TCCM,TCM,ECP_E,ECP_S,ECP_S2,ECP_X1
 SG_ NodeStsWCM_LcFA : 48|1@0+ (1,0) [0|1] "" ACP2_MCU,ADIMa,ADIMb,AHL_AFL,AHS,ARS,BSM,VECM,VICM,BSM_MH,DCM,DMS,EBCM,ECM,ECP_MC,EOCM,EOCM_HC_Superset,EPSRAa,EPS,EPSb,FCM,HUD_CAN,LIB1,NVM,E44,PCM,RDCM,TCCM,TCM,ECP_E,ECP_S,ECP_S2,ECP_X1
 SG_ NodeStsE63_LcFA : 49|1@0+ (1,0) [0|1] "" ACP2_MCU,ADIMa,ADIMb,AHL_AFL,AHS,ARS,BSM,VECM,VICM,BSM_MH,DCM,DMS,EBCM,ECM,ECP_MC,EOCM,EOCM_HC_Superset,EPSRAa,EPS,EPSb,FCM,HUD_CAN,LIB1,NVM,E44,PCM,RDCM,TCCM,TCM,ECP_E,ECP_S,ECP_S2,ECP_X1
 SG_ NodeStsVLM_LcFA : 50|1@0+ (1,0) [0|1] "" ACP2_MCU,ADIMa,ADIMb,AHL_AFL,AHS,ARS,BSM,VECM,VICM,BSM_MH,DCM,DMS,EBCM,ECM,ECP_MC,EOCM,EOCM_HC_Superset,EPSRAa,EPS,EPSb,FCM,HUD_CAN,LIB1,NVM,E44,PCM,RDCM,TCCM,TCM,ECP_E,ECP_S,ECP_S2,ECP_X1
 SG_ NodeStsVKM_LcFA : 51|1@0+ (1,0) [0|1] "" ACP2_MCU,ADIMa,ADIMb,AHL_AFL,AHS,ARS,BSM,VECM,VICM,BSM_MH,DCM,DMS,EBCM,ECM,ECP_MC,EOCM,EOCM_HC_Superset,EPSRAa,EPS,EPSb,FCM,HUD_CAN,LIB1,NVM,E44,PCM,RDCM,TCCM,TCM,ECP_E,ECP_S,ECP_S2,ECP_X1
 SG_ NodeStsVICM_CAN_9_LcFA : 52|1@0+ (1,0) [0|1] "" ACP2_MCU,ADIMa,ADIMb,AHL_AFL,AHS,ARS,BSM,VECM,BSM_MH,DCM,DMS,EBCM,ECM,ECP_MC,EOCM,EOCM_HC_Superset,EPSRAa,EPS,EPSb,FCM,HUD_CAN,LIB1,NVM,E44,PCM,RDCM,TCCM,TCM,ECP_E,ECP_S,ECP_S2,ECP_X1
 SG_ NodeStsVICM_CAN_2_LcFA : 53|1@0+ (1,0) [0|1] "" ACP2_MCU,ADIMa,ADIMb,AHL_AFL,AHS,ARS,BSM,VECM,BSM_MH,DCM,DMS,EBCM,ECM,ECP_MC,EOCM,EOCM_HC_Superset,EPSRAa,EPS,EPSb,FCM,HUD_CAN,LIB1,NVM,E44,PCM,RDCM,TCCM,TCM,ECP_E,ECP_S,ECP_S2,ECP_X1
 SG_ NodeStsVCU_CAN_5_LcFA : 54|1@0+ (1,0) [0|1] "" ACP2_MCU,ADIMa,ADIMb,AHL_AFL,AHS,ARS,BSM,VECM,VICM,BSM_MH,DCM,DMS,EBCM,ECM,ECP_MC,EOCM,EOCM_HC_Superset,EPSRAa,EPS,EPSb,FCM,HUD_CAN,LIB1,NVM,PCM,RDCM,TCCM,TCM,ECP_E,ECP_S,ECP_S2,ECP_X1
 SG_ NodeStsE60_LcFA : 55|1@0+ (1,0) [0|1] "" ACP2_MCU,ADIMa,ADIMb,AHL_AFL,AHS,ARS,BSM,VECM,VICM,BSM_MH,DCM,DMS,EBCM,ECM,ECP_MC,EOCM,EOCM_HC_Superset,EPSRAa,EPS,EPSb,FCM,HUD_CAN,LIB1,NVM,E44,PCM,RDCM,TCCM,TCM,ECP_E,ECP_S,ECP_S2,ECP_X1
 SG_ NodeStsECP_S2_CAN_2_LcFA : 56|1@0+ (1,0) [0|1] "" ACP2_MCU,ADIMa,ADIMb,AHL_AFL,AHS,ARS,BSM,VECM,VICM,BSM_MH,DCM,DMS,EBCM,ECM,ECP_MC,EOCM,EOCM_HC_Superset,EPSRAa,EPS,EPSb,FCM,HUD_CAN,LIB1,NVM,E44,PCM,RDCM,TCCM,TCM,ECP_E,ECP_S,ECP_X1
 SG_ NodeStsE45_LcFA : 57|1@0+ (1,0) [0|1] "" ACP2_MCU,ADIMa,ADIMb,AHL_AFL,AHS,ARS,BSM,VECM,VICM,BSM_MH,DCM,DMS,EBCM,ECM,ECP_MC,EOCM,EOCM_HC_Superset,EPSRAa,EPS,EPSb,FCM,HUD_CAN,LIB1,NVM,E44,PCM,RDCM,TCCM,TCM,ECP_E,ECP_S,ECP_S2,ECP_X1
 SG_ NodeStsVDM_CAN_2_LcFA : 58|1@0+ (1,0) [0|1] "" ACP2_MCU,ADIMa,ADIMb,AHL_AFL,AHS,ARS,BSM,VECM,VICM,BSM_MH,DCM,DMS,EBCM,ECM,ECP_MC,EOCM,EOCM_HC_Superset,EPSRAa,EPS,EPSb,FCM,HUD_CAN,LIB1,NVM,E44,PCM,RDCM,TCCM,TCM,ECP_E,ECP_S,ECP_S2,ECP_X1
 SG_ NodeStsWE48_LcFA : 59|1@0+ (1,0) [0|1] "" ACP2_MCU,ADIMa,ADIMb,AHL_AFL,AHS,ARS,BSM,VECM,VICM,BSM_MH,DCM,DMS,EBCM,ECM,ECP_MC,EOCM,EOCM_HC_Superset,EPSRAa,EPS,EPSb,FCM,HUD_CAN,LIB1,NVM,E44,PCM,RDCM,TCCM,TCM,ECP_E,ECP_S,ECP_S2,ECP_X1
 SG_ NodeStsPCM_CAN_3_LcFA : 60|1@0+ (1,0) [0|1] "" ACP2_MCU,ADIMa,ADIMb,AHL_AFL,AHS,ARS,BSM,VECM,VICM,BSM_MH,DCM,DMS,EBCM,ECM,ECP_MC,EOCM,EOCM_HC_Superset,EPSRAa,EPS,EPSb,FCM,HUD_CAN,LIB1,NVM,E44,RDCM,TCCM,TCM,ECP_E,ECP_S,ECP_S2,ECP_X1
 SG_ NodeStsPCM_CAN_2_LcFA : 61|1@0+ (1,0) [0|1] "" ACP2_MCU,ADIMa,ADIMb,AHL_AFL,AHS,ARS,BSM,VECM,VICM,BSM_MH,DCM,DMS,EBCM,ECM,ECP_MC,EOCM,EOCM_HC_Superset,EPSRAa,EPS,EPSb,FCM,HUD_CAN,LIB1,NVM,E44,RDCM,TCCM,TCM,ECP_E,ECP_S,ECP_S2,ECP_X1
 SG_ NodeStsSDM_AV_LcFA : 62|1@0+ (1,0) [0|1] "" ACP2_MCU,ADIMa,ADIMb,AHL_AFL,AHS,ARS,BSM,VECM,VICM,BSM_MH,DCM,DMS,EBCM,ECM,ECP_MC,EOCM,EOCM_HC_Superset,EPSRAa,EPS,EPSb,FCM,HUD_CAN,LIB1,NVM,E44,PCM,RDCM,TCCM,TCM,ECP_E,ECP_S,ECP_S2,ECP_X1

BO_ 962 NodeStatus_CAN2_PDU03: 8 Vector__XXX
 SG_ NodeStsACP2_MCU_CAN_8_LcFA : 1|1@0+ (1,0) [0|1] "" ADIMa,ADIMb,AHL_AFL,AHS,ARS,BSM,VECM,VICM,BSM_MH,DCM,DMS,ECP_MC,EOCM,EOCM_HC_Superset,EPSRAa,EPS,EPSb,FCM,HUD_CAN,LIB1,NVM,E44,RDCM,TCCM,TCM,ECP_E,ECP_S,ECP_S2,ECP_X1
 SG_ NodeStsACP2_MCU_CAN_2_LcFA : 2|1@0+ (1,0) [0|1] "" ADIMa,ADIMb,AHL_AFL,AHS,ARS,BSM,VECM,VICM,BSM_MH,DCM,DMS,EBCM,ECM,ECP_MC,EOCM,EOCM_HC_Superset,EPSRAa,EPS,EPSb,FCM,HUD_CAN,LIB1,NVM,E44,PCM,RDCM,TCCM,TCM,ECP_E,ECP_S,ECP_S2,ECP_X1
 SG_ NodeStsVECM_CAN_2_LcFA : 3|1@0+ (1,0) [0|1] "" ACP2_MCU,ADIMa,ADIMb,AHL_AFL,AHS,ARS,BSM,VICM,BSM_MH,DCM,DMS,EBCM,ECM,ECP_MC,EOCM,EOCM_HC_Superset,EPSRAa,EPS,EPSb,FCM,HUD_CAN,LIB1,NVM,E44,PCM,RDCM,TCCM,TCM,ECP_E,ECP_S,ECP_S2,ECP_X1
 SG_ NodeStsVDM_CAN_9_LcFA : 4|1@0+ (1,0) [0|1] "" ACP2_MCU,ADIMa,ADIMb,AHL_AFL,AHS,ARS,BSM,VECM,VICM,BSM_MH,DCM,DMS,EBCM,ECM,ECP_MC,EOCM,EOCM_HC_Superset,EPSRAa,EPS,EPSb,FCM,HUD_CAN,LIB1,NVM,E44,PCM,RDCM,TCCM,TCM,ECP_E,ECP_S,ECP_S2,ECP_X1
 SG_ NodeStsE61_CAN_1_LcFA : 5|1@0+ (1,0) [0|1] "" ACP2_MCU,ADIMa,ADIMb,AHL_AFL,AHS,ARS,BSM,VECM,VICM,BSM_MH,DCM,DMS,EBCM,ECM,ECP_MC,EOCM,EOCM_HC_Superset,EPSRAa,EPS,EPSb,FCM,HUD_CAN,LIB1,NVM,E44,PCM,RDCM,TCCM,TCM,ECP_E,ECP_S,ECP_S2,ECP_X1
 SG_ NodeStsUPM_LcFA : 6|1@0+ (1,0) [0|1] "" ACP2_MCU,ADIMa,ADIMb,AHL_AFL,AHS,ARS,BSM,VECM,VICM,BSM_MH,DCM,DMS,EBCM,ECM,ECP_MC,EOCM,EOCM_HC_Superset,EPSRAa,EPS,EPSb,FCM,HUD_CAN,LIB1,NVM,E44,PCM,RDCM,TCCM,TCM,ECP_E,ECP_S,ECP_S2,ECP_X1
 SG_ NodeStsEPSb_LcFA : 7|1@0+ (1,0) [0|1] "" ACP2_MCU,ADIMa,ADIMb,AHL_AFL,AHS,ARS,BSM,VECM,VICM,BSM_MH,DCM,DMS,EBCM,ECM,ECP_MC,EOCM,EOCM_HC_Superset,EPSRAa,EPS,FCM,HUD_CAN,LIB1,NVM,E44,PCM,RDCM,TCCM,TCM,ECP_E,ECP_S,ECP_S2,ECP_X1
 SG_ NodeStsSBM_CAN_10_LcFA : 8|1@0+ (1,0) [0|1] "" ACP2_MCU,ADIMa,ADIMb,AHL_AFL,AHS,ARS,BSM,VECM,VICM,BSM_MH,DCM,DMS,EBCM,ECM,ECP_MC,EOCM,EOCM_HC_Superset,EPSRAa,EPS,EPSb,FCM,HUD_CAN,LIB1,NVM,E44,PCM,RDCM,TCCM,TCM,ECP_E,ECP_S,ECP_S2,ECP_X1
 SG_ NodeStsVECM_CAN_9_LcFA : 9|1@0+ (1,0) [0|1] "" ACP2_MCU,ADIMa,ADIMb,AHL_AFL,AHS,ARS,BSM,VICM,BSM_MH,DCM,DMS,EBCM,ECM,ECP_MC,EOCM,EOCM_HC_Superset,EPSRAa,EPS,EPSb,FCM,HUD_CAN,LIB1,NVM,E44,PCM,RDCM,TCCM,TCM,ECP_E,ECP_S,ECP_S2,ECP_X1
 SG_ NodeStsECP_S2_CAN_9_LcFA : 11|1@0+ (1,0) [0|1] "" ACP2_MCU,ADIMa,ADIMb,AHL_AFL,AHS,ARS,BSM,VECM,VICM,BSM_MH,DCM,DMS,EBCM,ECM,ECP_MC,EOCM,EOCM_HC_Superset,EPSRAa,EPS,EPSb,FCM,HUD_CAN,LIB1,NVM,E44,PCM,RDCM,TCCM,TCM,ECP_E,ECP_S,ECP_X1
 SG_ NodeStsCSM_AV_CAN_5_LcFA : 12|1@0+ (1,0) [0|1] "" ACP2_MCU,ADIMa,ADIMb,AHL_AFL,AHS,ARS,BSM,VECM,VICM,BSM_MH,DCM,DMS,EBCM,ECM,ECP_MC,EOCM,EOCM_HC_Superset,EPSRAa,EPS,EPSb,FCM,HUD_CAN,LIB1,NVM,E44,PCM,RDCM,TCCM,TCM,ECP_E,ECP_S,ECP_S2,ECP_X1
 SG_ NodeStsACP3_MCU_CAN_3_LcFA : 13|1@0+ (1,0) [0|1] "" ACP2_MCU,ADIMa,ADIMb,AHL_AFL,AHS,ARS,BSM,VECM,VICM,BSM_MH,DCM,DMS,EBCM,ECM,ECP_MC,EOCM,EOCM_HC_Superset,EPSRAa,EPS,EPSb,FCM,HUD_CAN,LIB1,NVM,E44,PCM,RDCM,TCCM,TCM,ECP_E,ECP_S,ECP_S2,ECP_X1
 SG_ NodeStsACP3_MCU_CAN_8_LcFA : 14|1@0+ (1,0) [0|1] "" ACP2_MCU,ADIMa,ADIMb,AHL_AFL,AHS,ARS,BSM,VECM,VICM,BSM_MH,DCM,DMS,EBCM,ECM,ECP_MC,EOCM,EOCM_HC_Superset,EPSRAa,EPS,EPSb,FCM,HUD_CAN,LIB1,NVM,E44,PCM,RDCM,TCCM,TCM,ECP_E,ECP_S,ECP_S2,ECP_X1
 SG_ NodeStsACP3_MCU_CAN_2_LcFA : 15|1@0+ (1,0) [0|1] "" ACP2_MCU,ADIMa,ADIMb,AHL_AFL,AHS,ARS,BSM,VECM,VICM,BSM_MH,DCM,DMS,EBCM,ECM,ECP_MC,EOCM,EOCM_HC_Superset,EPSRAa,EPS,EPSb,FCM,HUD_CAN,LIB1,NVM,E44,PCM,RDCM,TCCM,TCM,ECP_E,ECP_S,ECP_S2,ECP_X1

BO_ 2564502513 OBD_Req_From_E58_To_AllOBDNodes_: 7 Vector__XXX

BO_ 2564475889 Message0911_PDU: 8 Vector__XXX

BO_ 2564434161 OBD_Req_From_E58_To_EBCM_CAN_2_c: 8 Vector__XXX

BO_ 2564428273 Message0917_PDU: 8 Vector__XXX

BO_ 2564429809 OBD_Req_From_E58_To_ECP_E_CAN_2_: 8 Vector__XXX

BO_ 2564431345 Message0920_PDU: 8 Vector__XXX

BO_ 2564431601 Message0922_PDU: 8 Vector__XXX

BO_ 2564482545 Message0928_PDU: 8 Vector__XXX

BO_ 2564482801 Message0932_PDU: 8 Vector__XXX

BO_ 2564428017 Message0934_PDU: 8 Vector__XXX

BO_ 2564430065 Message0936_PDU: 8 Vector__XXX

BO_ 2564476401 Message0938_PDU: 8 Vector__XXX

BO_ 2564485579 Message0944_PDU: 8 Vector__XXX

BO_ 2564485416 OBD_Rsp_From_EBCM_CAN_2_connecto: 8 Vector__XXX

BO_ 2564485393 Message0950_PDU: 8 Vector__XXX

BO_ 2564485399 OBD_Rsp_From_ECP_E_CAN_2_connect: 8 Vector__XXX

BO_ 2564485405 Message0953_PDU: 8 Vector__XXX

BO_ 2564485406 Message0955_PDU: 8 Vector__XXX

BO_ 2564485605 Message0961_PDU: 8 Vector__XXX

BO_ 2564485606 Message0965_PDU: 8 Vector__XXX

BO_ 2564485392 Message0967_PDU: 8 Vector__XXX

BO_ 2564485400 Message0969_PDU: 8 Vector__XXX

BO_ 2564485581 Message0971_PDU: 8 Vector__XXX

BO_ 1382 OccptRstrntInfo_PCSM_PDU: 8 Vector__XXX
 SG_ OccptRstrntInfo_PCSM : 7|64@0+ (1,0) [0|1.84467e+019] "" VICM,ECM,FCM,PCM

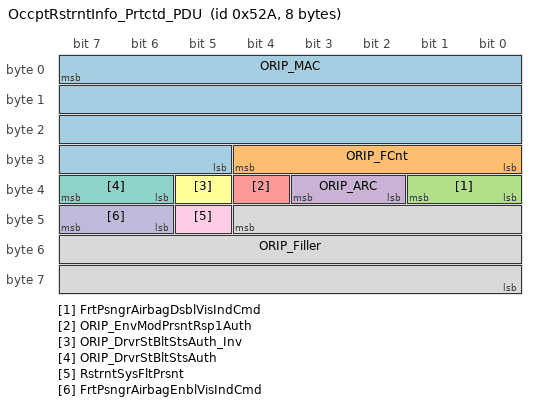
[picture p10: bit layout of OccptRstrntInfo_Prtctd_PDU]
BO_ 1322 OccptRstrntInfo_Prtctd_PDU: 8 Vector__XXX
 SG_ ORIP_MAC : 7|27@0+ (1,0) [0|1.34218e+008] "" VICM,ECM,FCM,PCM
 SG_ ORIP_FCnt : 28|5@0+ (1,0) [0|31] "" VICM,ECM,FCM,PCM
 SG_ FrtPsngrAirbagDsblVisIndCmd : 33|2@0+ (1,0) [0|2] "" VICM,ECM,FCM,PCM
 SG_ ORIP_ARC : 35|2@0+ (1,0) [0|3] "" VICM,ECM,FCM,PCM
 SG_ ORIP_EnvModPrsntRsp1Auth : 36|1@0+ (1,0) [0|1] "" VICM,ECM,FCM,PCM,TCM
 SG_ ORIP_DrvrStBltStsAuth_Inv : 37|1@0+ (1,0) [0|1] "" VICM,ECM,FCM,E44,PCM
 SG_ ORIP_DrvrStBltStsAuth : 39|2@0+ (1,0) [0|2] "" VICM,ECM,FCM,E44,PCM
 SG_ ORIP_Filler : 44|21@0+ (1,0) [0|2.09715e+006] "" VICM,ECM,FCM,PCM
 SG_ RstrntSysFltPrsnt : 45|1@0+ (1,0) [0|1] "" VICM,ECM,FCM,PCM
 SG_ FrtPsngrAirbagEnblVisIndCmd : 47|2@0+ (1,0) [0|2] "" VICM,ECM,FCM,PCM

BO_ 2147745833 Message0976_PDU: 1 Vector__XXX
 SG_ Sig4429 : 7|1@0+ (1,0) [0|1] "" CGM

BO_ 272 PCM_NM_PDU_On_CAN_2_Cluster: 8 Vector__XXX
 SG_ ISignal_PCM_CAN_2_Cluster : 23|48@0+ (1,0) [0|281474976710655] "" ACP2_MCU,ADIMa,ADIMb,AHL_AFL,AHS,ARS,BSM,VECM,VICM,BSM_MH,CGM,DCM,DMS,EBCM,ECM,ECP_MC,EOCM,EOCM_HC_Superset,EPSRAa,EPS,EPSb,FCM,FOPM,HUD_CAN,LIB1,NVM,E44,RDCM,TCCM,TCM,VDM,ECP_E,ECP_S,ECP_S2,ECP_X1

BO_ 713 PTImmblzerInfo_PDU: 8 Vector__XXX
 SG_ PTImmblzerInfo : 7|64@0+ (1,0) [0|1.84467e+019] "" ECM,PCM

BO_ 1354 Park_Assist_CAN1_PDU05: 8 Vector__XXX
 SG_ FE44RS_LtCntr : 3|4@0+ (1,0) [0|14] "" CGM
 SG_ FE44RS_Lt : 7|4@0+ (1,0) [0|14] "" CGM
 SG_ FE44RS_RtCntr : 11|4@0+ (1,0) [0|14] "" CGM
 SG_ FE44RS_Rt : 15|4@0+ (1,0) [0|14] "" CGM
 SG_ E44VehPathCrv : 23|12@0- (0.001,0) [-2.048|2.047] "" CGM
 SG_ E44IM_FaildIndOn : 24|1@0+ (1,0) [0|1] "" CGM
 SG_ E44IM_DsbldIndOn : 25|1@0+ (1,0) [0|1] "" CGM
 SG_ E44VisObjIndStatReq : 27|2@0+ (1,0) [0|3] "" CGM
 SG_ E44Rgn : 32|3@0+ (1,0) [0|1] "" CGM
 SG_ E44IM_TeenDrvrE44OffUnvIndOn : 33|1@0+ (1,0) [0|1] "" CGM
 SG_ E44IM_SnsrDstbdIndOn : 34|1@0+ (1,0) [0|1] "" CGM
 SG_ E44IM_SnsrClnIndOn : 35|1@0+ (1,0) [0|1] "" CGM
 SG_ E44IM_SnsrBlckdIndOn : 36|1@0+ (1,0) [0|1] "" CGM
 SG_ E44IM_RrOffIndOn : 37|1@0+ (1,0) [0|1] "" CGM
 SG_ E44IM_OffIndOn : 38|1@0+ (1,0) [0|1] "" CGM
 SG_ E44IM_FrtOffIndOn : 39|1@0+ (1,0) [0|1] "" CGM
 SG_ PrkAsstActIndCmnd : 42|1@0+ (1,0) [0|1] "" CGM
 SG_ PrkAsstStat : 45|3@0+ (1,0) [0|7] "" ACP2_MCU,CGM,EOCM,EOCM_HC_Superset,FCM

BO_ 913 PrplGenInfo3_PCSM_PDU: 8 Vector__XXX
 SG_ PrplGenInfo3_PCSM : 7|64@0+ (1,0) [0|1.84467e+019] "" ADIMa,ADIMb,EBCM

BA_DEF_ SG_  "SignalType" STRING ;
BA_DEF_ SG_  "SignalLongName" STRING ;
BA_DEF_ BO_  "GenMsgCycleTime" INT 0 10000;
BA_DEF_ BO_  "GenMsgSendType" ENUM "cyclicX","spontanX","cyclicIfActiveX","spontanWithDelay","cyclicAndSpontanX","cyclicAndSpontanWithDelay","spontanWithRepetition","cyclicIfActiveAndSpontanWD";
BA_DEF_ BO_  "VFrameFormat" ENUM  "StandardCAN","ExtendedCAN","reserved","reserved","reserved","reserved","reserved","reserved","reserved","reserved","reserved","reserved","reserved","reserved","StandardCAN_FD","ExtendedCAN_FD";
BA_DEF_DEF_  "SignalType" "";
BA_DEF_DEF_  "SignalLongName" "";
BA_DEF_DEF_  "GenMsgCycleTime" 0;
BA_DEF_DEF_  "GenMsgSendType" "cyclicX";
BA_DEF_DEF_  "VFrameFormat" "StandardCAN";
BA_ "GenMsgCycleTime" BO_ 19 12.5;
BA_ "VFrameFormat" BO_ 19 14;
BA_ "GenMsgCycleTime" BO_ 1026 1000;
BA_ "VFrameFormat" BO_ 1026 14;
BA_ "GenMsgCycleTime" BO_ 1355 1000;
BA_ "VFrameFormat" BO_ 1355 14;
BA_ "GenMsgCycleTime" BO_ 1147 1000;
BA_ "VFrameFormat" BO_ 1147 14;
BA_ "GenMsgCycleTime" BO_ 669 100;
BA_ "VFrameFormat" BO_ 669 14;
BA_ "GenMsgCycleTime" BO_ 1321 1000;
BA_ "VFrameFormat" BO_ 1321 14;
BA_ "GenMsgCycleTime" BO_ 1318 1000;
BA_ "VFrameFormat" BO_ 1318 14;
BA_ "GenMsgCycleTime" BO_ 1304 1000;
BA_ "VFrameFormat" BO_ 1304 14;
BA_ "GenMsgCycleTime" BO_ 544 50;
BA_ "VFrameFormat" BO_ 544 14;
BA_ "GenMsgCycleTime" BO_ 1341 1000;
BA_ "VFrameFormat" BO_ 1341 14;
BA_ "GenMsgCycleTime" BO_ 1239 1000;
BA_ "VFrameFormat" BO_ 1239 14;
BA_ "GenMsgCycleTime" BO_ 942 250;
BA_ "VFrameFormat" BO_ 942 14;
BA_ "GenMsgCycleTime" BO_ 943 250;
BA_ "VFrameFormat" BO_ 943 14;
BA_ "GenMsgCycleTime" BO_ 1346 1000;
BA_ "VFrameFormat" BO_ 1346 14;
BA_ "GenMsgCycleTime" BO_ 1251 1000;
BA_ "VFrameFormat" BO_ 1251 14;
BA_ "GenMsgCycleTime" BO_ 1429 1000;
BA_ "VFrameFormat" BO_ 1429 14;
BA_ "GenMsgCycleTime" BO_ 1810 1000;
BA_ "VFrameFormat" BO_ 1810 14;
BA_ "GenMsgCycleTime" BO_ 1443 1000;
BA_ "VFrameFormat" BO_ 1443 14;
BA_ "GenMsgCycleTime" BO_ 1425 1000;
BA_ "VFrameFormat" BO_ 1425 14;
BA_ "GenMsgCycleTime" BO_ 718 100;
BA_ "VFrameFormat" BO_ 718 14;
BA_ "GenMsgCycleTime" BO_ 730 150;
BA_ "VFrameFormat" BO_ 730 14;
BA_ "GenMsgCycleTime" BO_ 716 200;
BA_ "VFrameFormat" BO_ 716 14;
BA_ "GenMsgCycleTime" BO_ 717 250;
BA_ "VFrameFormat" BO_ 717 14;
BA_ "GenMsgCycleTime" BO_ 177 50;
BA_ "VFrameFormat" BO_ 177 14;
BA_ "GenMsgCycleTime" BO_ 535 50;
BA_ "VFrameFormat" BO_ 535 14;
BA_ "GenMsgCycleTime" BO_ 1479 1000;
BA_ "VFrameFormat" BO_ 1479 14;
BA_ "GenMsgCycleTime" BO_ 1824 1000;
BA_ "VFrameFormat" BO_ 1824 14;
BA_ "GenMsgCycleTime" BO_ 1339 1000;
BA_ "VFrameFormat" BO_ 1339 14;
BA_ "GenMsgCycleTime" BO_ 1242 1000;
BA_ "VFrameFormat" BO_ 1242 14;
BA_ "GenMsgCycleTime" BO_ 1952 1000;
BA_ "VFrameFormat" BO_ 1952 14;
BA_ "GenMsgCycleTime" BO_ 728 100;
BA_ "VFrameFormat" BO_ 728 14;
BA_ "GenMsgCycleTime" BO_ 1442 1000;
BA_ "VFrameFormat" BO_ 1442 14;
BA_ "GenMsgCycleTime" BO_ 702 100;
BA_ "VFrameFormat" BO_ 702 14;
BA_ "GenMsgCycleTime" BO_ 1464 1000;
BA_ "VFrameFormat" BO_ 1464 14;
BA_ "GenMsgCycleTime" BO_ 1408 1000;
BA_ "VFrameFormat" BO_ 1408 14;
BA_ "GenMsgCycleTime" BO_ 1409 1000;
BA_ "VFrameFormat" BO_ 1409 14;
BA_ "GenMsgCycleTime" BO_ 932 250;
BA_ "VFrameFormat" BO_ 932 14;
BA_ "GenMsgCycleTime" BO_ 1426 1000;
BA_ "VFrameFormat" BO_ 1426 14;
BA_ "GenMsgCycleTime" BO_ 1411 1000;
BA_ "VFrameFormat" BO_ 1411 14;
BA_ "GenMsgCycleTime" BO_ 2147745822 1000;
BA_ "GenMsgCycleTime" BO_ 963 1000;
BA_ "VFrameFormat" BO_ 963 14;
BA_ "GenMsgCycleTime" BO_ 964 1000;
BA_ "VFrameFormat" BO_ 964 14;
BA_ "GenMsgCycleTime" BO_ 962 1000;
BA_ "VFrameFormat" BO_ 962 14;
BA_ "GenMsgCycleTime" BO_ 1382 3500;
BA_ "VFrameFormat" BO_ 1382 14;
BA_ "GenMsgCycleTime" BO_ 1322 1000;
BA_ "VFrameFormat" BO_ 1322 14;
BA_ "GenMsgCycleTime" BO_ 2147745833 1000;
BA_ "GenMsgCycleTime" BO_ 713 100;
BA_ "VFrameFormat" BO_ 713 14;
BA_ "GenMsgCycleTime" BO_ 1354 1000;
BA_ "VFrameFormat" BO_ 1354 14;
BA_ "VFrameFormat" BO_ 913 14;
BA_ "SignalLongName" SG_ 19 PrplSysWhlFlrCtlPriAxlRtTrqCmd "Propulsion System Wheel Flare Control Primary Axle Right Torque Command";
BA_ "SignalType" SG_ 19 PrplSysWhlFlrCtlPriAxlRtActv "ENM";
BA_ "SignalLongName" SG_ 19 PrplSysWhlFlrCtlPriAxlRtActv "Propulsion System Wheel Flare Control Primary Axle Right Active";
BA_ "SignalLongName" SG_ 1026 FE44SDGHSR_LtFstHptcStReqSeqNum "Full Park Assist Side Distance Guard Haptic Seat Request : Left Fast Haptic Seat Request Sequence Number";
BA_ "SignalLongName" SG_ 1026 FE44SDGHSR_LtFstHptcStReqPuls "Full Park Assist Side Distance Guard Haptic Seat Request : Left Fast Haptic Seat Request Pulses";
BA_ "SignalLongName" SG_ 1026 FE44SDGHSR_LtSloHptcStReqSeqNum "Full Park Assist Side Distance Guard Haptic Seat Request : Left Slow Haptic Seat Request Sequence Number";
BA_ "SignalLongName" SG_ 1026 FE44SDGHSR_LtSloHptcStReqPuls "Full Park Assist Side Distance Guard Haptic Seat Request : Left Slow Haptic Seat Request Pulses";
BA_ "SignalLongName" SG_ 1026 FE44SDGHSR_RtFstHptcStReqSeqNum "Full Park Assist Side Distance Guard Haptic Seat Request : Right Fast Haptic Seat Request Sequence Number";
BA_ "SignalLongName" SG_ 1026 FE44SDGHSR_RtFstHptcStReqPuls "Full Park Assist Side Distance Guard Haptic Seat Request : Right Fast Haptic Seat Request Pulses";
BA_ "SignalLongName" SG_ 1026 FE44SDGHSR_RtSloHptcStReqSeqNum "Full Park Assist Side Distance Guard Haptic Seat Request : Right Slow Haptic Seat Request Sequence Number";
BA_ "SignalLongName" SG_ 1026 FE44SDGHSR_RtSloHptcStReqPuls "Full Park Assist Side Distance Guard Haptic Seat Request : Right Slow Haptic Seat Request Pulses";
BA_ "SignalLongName" SG_ 1026 FFE44HSR_FrstRptHptcStReqSeqNum "Full Front Park Assist Haptic Seat Request : First Report Haptic Seat Request Sequence Number";
BA_ "SignalLongName" SG_ 1026 FFE44HSR_FrstRptHptcStReqPuls "Full Front Park Assist Haptic Seat Request : First Report Haptic Seat Request Pulses";
BA_ "SignalLongName" SG_ 1026 FFE44HSR_FstHptcStReqSeqNum "Full Front Park Assist Haptic Seat Request : Fast Haptic Seat Request Sequence Number";
BA_ "SignalLongName" SG_ 1026 FFE44HSR_FstHptcStReqPuls "Full Front Park Assist Haptic Seat Request : Fast Haptic Seat Request Pulses";
BA_ "SignalLongName" SG_ 1026 FFE44HSR_SloHptcStReqSeqNum "Full Front Park Assist Haptic Seat Request : Slow Haptic Seat Request Sequence Number";
BA_ "SignalLongName" SG_ 1026 FFE44HSR_SloHptcStReqPuls "Full Front Park Assist Haptic Seat Request : Slow Haptic Seat Request Pulses";
BA_ "SignalLongName" SG_ 1026 FRE44HSR_FrstRptHptcStReqSeqNum "Full Rear Park Assist Haptic Seat Request : First Report Haptic Seat Request Sequence Number";
BA_ "SignalLongName" SG_ 1026 FRE44HSR_FrstRptHptcStReqPuls "Full Rear Park Assist Haptic Seat Request : First Report Haptic Seat Request Pulses";
BA_ "SignalLongName" SG_ 1026 FRE44HSR_FstHptcStReqSeqNum "Full Rear Park Assist Haptic Seat Request : Fast Haptic Seat Request Sequence Number";
BA_ "SignalLongName" SG_ 1026 FRE44HSR_FstHptcStReqPuls "Full Rear Park Assist Haptic Seat Request : Fast Haptic Seat Request Pulses";
BA_ "SignalLongName" SG_ 1026 FRE44HSR_SloHptcStReqSeqNum "Full Rear Park Assist Haptic Seat Request : Slow Haptic Seat Request Sequence Number";
BA_ "SignalLongName" SG_ 1026 FRE44HSR_SloHptcStReqPuls "Full Rear Park Assist Haptic Seat Request : Slow Haptic Seat Request Pulses";
BA_ "SignalType" SG_ 1026 PrkAsstFllFrZn2ChEvntSt "ENM";
BA_ "SignalLongName" SG_ 1026 PrkAsstFllFrZn2ChEvntSt "Park Assist Full Front Zone 2 Chime Event State";
BA_ "SignalType" SG_ 1026 PrkAsstFllFrZn1ChEvntSt "ENM";
BA_ "SignalLongName" SG_ 1026 PrkAsstFllFrZn1ChEvntSt "Park Assist Full Front Zone 1 Chime Event State";
BA_ "SignalType" SG_ 1026 PrkAsstFlChEvntSt "ENM";
BA_ "SignalLongName" SG_ 1026 PrkAsstFlChEvntSt "Park Assist Fail Chime Event State";
BA_ "SignalType" SG_ 1026 E44MutSts "ENM";
BA_ "SignalLongName" SG_ 1026 E44MutSts "Park Assist Mute Status";
BA_ "SignalType" SG_ 1026 PrkAsstFllFrZn6ChEvntSt "ENM";
BA_ "SignalLongName" SG_ 1026 PrkAsstFllFrZn6ChEvntSt "Park Assist Full Front Zone 6 Chime Event State";
BA_ "SignalType" SG_ 1026 PrkAsstFllFrZn5ChEvntSt "ENM";
BA_ "SignalLongName" SG_ 1026 PrkAsstFllFrZn5ChEvntSt "Park Assist Full Front Zone 5 Chime Event State";
BA_ "SignalType" SG_ 1026 PrkAsstFllFrZn4ChEvntSt "ENM";
BA_ "SignalLongName" SG_ 1026 PrkAsstFllFrZn4ChEvntSt "Park Assist Full Front Zone 4 Chime Event State";
BA_ "SignalType" SG_ 1026 PrkAsstFllFrZn3ChEvntSt "ENM";
BA_ "SignalLongName" SG_ 1026 PrkAsstFllFrZn3ChEvntSt "Park Assist Full Front Zone 3 Chime Event State";
BA_ "SignalType" SG_ 1026 PrkAsstFllRrZn4ChEvntSt "ENM";
BA_ "SignalLongName" SG_ 1026 PrkAsstFllRrZn4ChEvntSt "Park Assist Full Rear Zone 4 Chime Event State";
BA_ "SignalType" SG_ 1026 PrkAsstFllRrZn3ChEvntSt "ENM";
BA_ "SignalLongName" SG_ 1026 PrkAsstFllRrZn3ChEvntSt "Park Assist Full Rear Zone 3 Chime Event State";
BA_ "SignalType" SG_ 1026 PrkAsstFllRrZn2ChEvntSt "ENM";
BA_ "SignalLongName" SG_ 1026 PrkAsstFllRrZn2ChEvntSt "Park Assist Full Rear Zone 2 Chime Event State";
BA_ "SignalType" SG_ 1026 PrkAsstFllRrZn1ChEvntSt "ENM";
BA_ "SignalLongName" SG_ 1026 PrkAsstFllRrZn1ChEvntSt "Park Assist Full Rear Zone 1 Chime Event State";
BA_ "SignalType" SG_ 1026 PrkAsstFrLftSdZn1ChEvntSt "ENM";
BA_ "SignalLongName" SG_ 1026 PrkAsstFrLftSdZn1ChEvntSt "Park Assist Front Left Side Zone 1 Chime Event State";
BA_ "SignalType" SG_ 1026 PrkAsstFrFrstRprtChEvntSt "ENM";
BA_ "SignalLongName" SG_ 1026 PrkAsstFrFrstRprtChEvntSt "Park Assist Front First Report Chime Event State";
BA_ "SignalType" SG_ 1026 PrkAsstFllRrZn6ChEvntSt "ENM";
BA_ "SignalLongName" SG_ 1026 PrkAsstFllRrZn6ChEvntSt "Park Assist Full Rear Zone 6 Chime Event State";
BA_ "SignalType" SG_ 1026 PrkAsstFllRrZn5ChEvntSt "ENM";
BA_ "SignalLongName" SG_ 1026 PrkAsstFllRrZn5ChEvntSt "Park Assist Full Rear Zone 5 Chime Event State";
BA_ "SignalType" SG_ 1026 PrkAsstFrLftSdZn5ChEvntSt "ENM";
BA_ "SignalLongName" SG_ 1026 PrkAsstFrLftSdZn5ChEvntSt "Park Assist Front Left Side Zone 5 Chime Event State";
BA_ "SignalType" SG_ 1026 PrkAsstFrLftSdZn4ChEvntSt "ENM";
BA_ "SignalLongName" SG_ 1026 PrkAsstFrLftSdZn4ChEvntSt "Park Assist Front Left Side Zone 4 Chime Event State";
BA_ "SignalType" SG_ 1026 PrkAsstFrLftSdZn3ChEvntSt "ENM";
BA_ "SignalLongName" SG_ 1026 PrkAsstFrLftSdZn3ChEvntSt "Park Assist Front Left Side Zone 3 Chime Event State";
BA_ "SignalType" SG_ 1026 PrkAsstFrLftSdZn2ChEvntSt "ENM";
BA_ "SignalLongName" SG_ 1026 PrkAsstFrLftSdZn2ChEvntSt "Park Assist Front Left Side Zone 2 Chime Event State";
BA_ "SignalType" SG_ 1026 PrkAsstFrRghtSdZn3ChEvntSt "ENM";
BA_ "SignalLongName" SG_ 1026 PrkAsstFrRghtSdZn3ChEvntSt "Park Assist Front Right Side Zone 3 Chime Event State";
BA_ "SignalType" SG_ 1026 PrkAsstFrRghtSdZn2ChEvntSt "ENM";
BA_ "SignalLongName" SG_ 1026 PrkAsstFrRghtSdZn2ChEvntSt "Park Assist Front Right Side Zone 2 Chime Event State";
BA_ "SignalType" SG_ 1026 PrkAsstFrRghtSdZn1ChEvntSt "ENM";
BA_ "SignalLongName" SG_ 1026 PrkAsstFrRghtSdZn1ChEvntSt "Park Assist Front Right Side Zone 1 Chime Event State";
BA_ "SignalType" SG_ 1026 PrkAsstFrLftSdZn6ChEvntSt "ENM";
BA_ "SignalLongName" SG_ 1026 PrkAsstFrLftSdZn6ChEvntSt "Park Assist Front Left Side Zone 6 Chime Event State";
BA_ "SignalType" SG_ 1026 PrkAsstFrRgrChEvntSt "ENM";
BA_ "SignalLongName" SG_ 1026 PrkAsstFrRgrChEvntSt "Park Assist Front Roger Chime Event State";
BA_ "SignalType" SG_ 1026 PrkAsstFrRghtSdZn6ChEvntSt "ENM";
BA_ "SignalLongName" SG_ 1026 PrkAsstFrRghtSdZn6ChEvntSt "Park Assist Front Right Side Zone 6 Chime Event State";
BA_ "SignalType" SG_ 1026 PrkAsstFrRghtSdZn5ChEvntSt "ENM";
BA_ "SignalLongName" SG_ 1026 PrkAsstFrRghtSdZn5ChEvntSt "Park Assist Front Right SideZone 5 Chime Event State";
BA_ "SignalType" SG_ 1026 PrkAsstFrRghtSdZn4ChEvntSt "ENM";
BA_ "SignalLongName" SG_ 1026 PrkAsstFrRghtSdZn4ChEvntSt "Park Assist Front Right Side Zone 4 Chime Event State";
BA_ "SignalType" SG_ 1026 PrkAsstRrLftSdZn3ChEvntSt "ENM";
BA_ "SignalLongName" SG_ 1026 PrkAsstRrLftSdZn3ChEvntSt "Park Assist Rear Left Side Zone 3 Chime Event State";
BA_ "SignalType" SG_ 1026 PrkAsstRrLftSdZn2ChEvntSt "ENM";
BA_ "SignalLongName" SG_ 1026 PrkAsstRrLftSdZn2ChEvntSt "Park Assist Rear Left Side Zone 2 Chime Event State";
BA_ "SignalType" SG_ 1026 PrkAsstRrLftSdZn1ChEvntSt "ENM";
BA_ "SignalLongName" SG_ 1026 PrkAsstRrLftSdZn1ChEvntSt "Park Assist Rear Left Side Zone 1 Chime Event State";
BA_ "SignalType" SG_ 1026 PrkAsstRrFrstRprtChEvntSt "ENM";
BA_ "SignalLongName" SG_ 1026 PrkAsstRrFrstRprtChEvntSt "Park Assist Rear First Report Chime Event State";
BA_ "SignalType" SG_ 1026 PrkAsstRrRghtSdZn1ChEvntSt "ENM";
BA_ "SignalLongName" SG_ 1026 PrkAsstRrRghtSdZn1ChEvntSt "Park Assist Rear Right Side Zone 1 Chime Event State";
BA_ "SignalType" SG_ 1026 PrkAsstRrLftSdZn6ChEvntSt "ENM";
BA_ "SignalLongName" SG_ 1026 PrkAsstRrLftSdZn6ChEvntSt "Park Assist Rear Left Side Zone 6 Chime Event State";
BA_ "SignalType" SG_ 1026 PrkAsstRrLftSdZn5ChEvntSt "ENM";
BA_ "SignalLongName" SG_ 1026 PrkAsstRrLftSdZn5ChEvntSt "Park Assist Rear Left Side Zone 5 Chime Event State";
BA_ "SignalType" SG_ 1026 PrkAsstRrLftSdZn4ChEvntSt "ENM";
BA_ "SignalLongName" SG_ 1026 PrkAsstRrLftSdZn4ChEvntSt "Park Assist Rear Left Side Zone 4 Chime Event State";
BA_ "SignalType" SG_ 1026 PrkAsstRrRghtSdZn5ChEvntSt "ENM";
BA_ "SignalLongName" SG_ 1026 PrkAsstRrRghtSdZn5ChEvntSt "Park Assist Rear Right Side Zone 5 Chime Event State";
BA_ "SignalType" SG_ 1026 PrkAsstRrRghtSdZn4ChEvntSt "ENM";
BA_ "SignalLongName" SG_ 1026 PrkAsstRrRghtSdZn4ChEvntSt "Park Assist Rear Right Side Zone 4 Chime Event State";
BA_ "SignalType" SG_ 1026 PrkAsstRrRghtSdZn3ChEvntSt "ENM";
BA_ "SignalLongName" SG_ 1026 PrkAsstRrRghtSdZn3ChEvntSt "Park Assist Rear Right Side Zone 3 Chime Event State";
BA_ "SignalType" SG_ 1026 PrkAsstRrRghtSdZn2ChEvntSt "ENM";
BA_ "SignalLongName" SG_ 1026 PrkAsstRrRghtSdZn2ChEvntSt "Park Assist Rear Right Side Zone 2 Chime Event State";
BA_ "SignalLongName" SG_ 1026 SuprRmtPrkMnvrPrgs "Supervised Remote Parking Warning Indications : Supervised Remote Parking Maneuver Progress";
BA_ "SignalType" SG_ 1026 PrkAsstRrRgrChEvntSt "ENM";
BA_ "SignalLongName" SG_ 1026 PrkAsstRrRgrChEvntSt "Park Assist Rear Roger Chime Event State";
BA_ "SignalType" SG_ 1026 PrkAsstRrRghtSdZn6ChEvntSt "ENM";
BA_ "SignalLongName" SG_ 1026 PrkAsstRrRghtSdZn6ChEvntSt "Park Assist Rear Right Side Zone 6 Chime Event State";
BA_ "SignalType" SG_ 1026 SuprRmtPrkWrnIndReq "ENM";
BA_ "SignalLongName" SG_ 1026 SuprRmtPrkWrnIndReq "Supervised Remote Parking Warning Indications : Supervised Remote Parking Warning Indication Request";
BA_ "SignalType" SG_ 1026 SuprRmtPrkDctvSftBtnReq "ENM";
BA_ "SignalLongName" SG_ 1026 SuprRmtPrkDctvSftBtnReq "Supervised Remote Parking Deactivation Soft Button Request";
BA_ "SignalType" SG_ 1026 SuprRmtPrkFcsReq "ENM";
BA_ "SignalLongName" SG_ 1026 SuprRmtPrkFcsReq "Supervised Remote Parking Warning Indications : Supervised Remote Parking Focus Request";
BA_ "SignalType" SG_ 1026 SuprRmtPrkAutoStrgIconReq "ENM";
BA_ "SignalLongName" SG_ 1026 SuprRmtPrkAutoStrgIconReq "Supervised Remote Parking Warning Indications : Supervised Remote Parking Auto Steering Icon Request";
BA_ "SignalType" SG_ 1355 RE44RS_LtCntr "ENM";
BA_ "SignalLongName" SG_ 1355 RE44RS_LtCntr "Rear Park Assist Region Status : Left Center Region";
BA_ "SignalType" SG_ 1355 RE44RS_Lt "ENM";
BA_ "SignalLongName" SG_ 1355 RE44RS_Lt "Rear Park Assist Region Status : Left Region";
BA_ "SignalType" SG_ 1355 RE44RS_RtCntr "ENM";
BA_ "SignalLongName" SG_ 1355 RE44RS_RtCntr "Rear Park Assist Region Status : Right Center Region";
BA_ "SignalType" SG_ 1355 RE44RS_Rt "ENM";
BA_ "SignalLongName" SG_ 1355 RE44RS_Rt "Rear Park Assist Region Status : Right Region";
BA_ "SignalLongName" SG_ 1147 HVBCC_HrOfDy "High Voltage Battery Charge Complete : Hour of Day";
BA_ "SignalType" SG_ 1147 HVBCC_DyOfWk "ENM";
BA_ "SignalLongName" SG_ 1147 HVBCC_DyOfWk "High Voltage Battery Charge Complete : Day of Week";
BA_ "SignalLongName" SG_ 1147 HVBCC_MinRmn "High Voltage Battery Charge Complete : Minutes Remaining";
BA_ "SignalLongName" SG_ 1147 HVBCC_MinOfHr "High Voltage Battery Charge Complete : Minute of Hour";
BA_ "SignalType" SG_ 1147 HVBCC_TmDispFormat "ENM";
BA_ "SignalLongName" SG_ 1147 HVBCC_TmDispFormat "High Voltage Battery Charge Complete : Time Display Format";
BA_ "SignalType" SG_ 1147 HVBCC_MinRmn_DuD "ENM";
BA_ "SignalLongName" SG_ 1147 HVBCC_MinRmn_DuD "High Voltage Battery Charge Complete : Minutes Remaining Don't Use Data";
BA_ "SignalType" SG_ 1147 HVBCC_TmDispPwrLvl "ENM";
BA_ "SignalLongName" SG_ 1147 HVBCC_TmDispPwrLvl "High Voltage Battery Charge Complete : Time Display Power Level";
BA_ "SignalType" SG_ 669 Sig0101 "ENM";
BA_ "SignalLongName" SG_ 669 Sig0101 "Signal0406";
BA_ "SignalType" SG_ 1321 DMSDrwDrvrCstSetAval "ENM";
BA_ "SignalLongName" SG_ 1321 DMSDrwDrvrCstSetAval "Driver Monitoring System Drowsy Driver Customization Setting Available";
BA_ "SignalType" SG_ 1321 DMSDrwDrvrCstAvlFlg7 "ENM";
BA_ "SignalLongName" SG_ 1321 DMSDrwDrvrCstAvlFlg7 "Driver Monitoring System Drowsy Driver Customization Availability Flag7";
BA_ "SignalType" SG_ 1321 DMSDrwDrvrCstAvlFlg6 "ENM";
BA_ "SignalLongName" SG_ 1321 DMSDrwDrvrCstAvlFlg6 "Driver Monitoring System Drowsy Driver Customization Availability Flag6";
BA_ "SignalType" SG_ 1321 DMSDrwDrvrCstAvlFlg5 "ENM";
BA_ "SignalLongName" SG_ 1321 DMSDrwDrvrCstAvlFlg5 "Driver Monitoring System Drowsy Driver Customization Availability Flag5";
BA_ "SignalType" SG_ 1321 DMSDrwDrvrCstAvlFlg4 "ENM";
BA_ "SignalLongName" SG_ 1321 DMSDrwDrvrCstAvlFlg4 "Driver Monitoring System Drowsy Driver Customization Availability Flag4";
BA_ "SignalType" SG_ 1321 DMSDrwDrvrCstAvlFlg3 "ENM";
BA_ "SignalLongName" SG_ 1321 DMSDrwDrvrCstAvlFlg3 "Driver Monitoring System Drowsy Driver Customization Availability Flag3";
BA_ "SignalType" SG_ 1321 DMSDrwDrvrCstAvlFlg2 "ENM";
BA_ "SignalLongName" SG_ 1321 DMSDrwDrvrCstAvlFlg2 "Driver Monitoring System Drowsy Driver Customization Availability Flag2";
BA_ "SignalType" SG_ 1321 DMSDrwDrvrCstAvlFlg1 "ENM";
BA_ "SignalLongName" SG_ 1321 DMSDrwDrvrCstAvlFlg1 "Driver Monitoring System Drowsy Driver Customization Availability Flag1";
BA_ "SignalType" SG_ 1321 DMSIntnDrvrCstSetAval "ENM";
BA_ "SignalLongName" SG_ 1321 DMSIntnDrvrCstSetAval "Driver Monitoring System Inattentive Driver Customization Setting Available";
BA_ "SignalType" SG_ 1321 DMSIntnDrvrCstAvlFlg7 "ENM";
BA_ "SignalLongName" SG_ 1321 DMSIntnDrvrCstAvlFlg7 "Driver Monitoring System Inattentive Driver Customization Availability Flag7";
BA_ "SignalType" SG_ 1321 DMSIntnDrvrCstAvlFlg6 "ENM";
BA_ "SignalLongName" SG_ 1321 DMSIntnDrvrCstAvlFlg6 "Driver Monitoring System Inattentive Driver Customization Availability Flag6";
BA_ "SignalType" SG_ 1321 DMSIntnDrvrCstAvlFlg5 "ENM";
BA_ "SignalLongName" SG_ 1321 DMSIntnDrvrCstAvlFlg5 "Driver Monitoring System Inattentive Driver Customization Availability Flag5";
BA_ "SignalType" SG_ 1321 DMSIntnDrvrCstAvlFlg4 "ENM";
BA_ "SignalLongName" SG_ 1321 DMSIntnDrvrCstAvlFlg4 "Driver Monitoring System Inattentive Driver Customization Availability Flag4";
BA_ "SignalType" SG_ 1321 DMSIntnDrvrCstAvlFlg3 "ENM";
BA_ "SignalLongName" SG_ 1321 DMSIntnDrvrCstAvlFlg3 "Driver Monitoring System Inattentive Driver Customization Availability Flag3";
BA_ "SignalType" SG_ 1321 DMSIntnDrvrCstAvlFlg2 "ENM";
BA_ "SignalLongName" SG_ 1321 DMSIntnDrvrCstAvlFlg2 "Driver Monitoring System Inattentive Driver Customization Availability Flag2";
BA_ "SignalType" SG_ 1321 DMSIntnDrvrCstAvlFlg1 "ENM";
BA_ "SignalLongName" SG_ 1321 DMSIntnDrvrCstAvlFlg1 "Driver Monitoring System Inattentive Driver Customization Availability Flag1";
BA_ "SignalType" SG_ 1318 DMSDrwIntnDrvrDtnAlrtMutReqd "ENM";
BA_ "SignalLongName" SG_ 1318 DMSDrwIntnDrvrDtnAlrtMutReqd "Driver Monitoring System Drowsy And Inattentive Driver Detection Alert Mute Requested";
BA_ "SignalType" SG_ 1318 DMSDrwIntnDrvrLvl1ChmEvntStat "ENM";
BA_ "SignalLongName" SG_ 1318 DMSDrwIntnDrvrLvl1ChmEvntStat "Driver Monitoring System Drowsy And Inattentive Driver Level 1 Chime Event State";
BA_ "SignalType" SG_ 1318 DMSDrwIntnDrvrLvl2ChmEvntStat "ENM";
BA_ "SignalLongName" SG_ 1318 DMSDrwIntnDrvrLvl2ChmEvntStat "Driver Monitoring System Drowsy And Inattentive Driver Level 2 Chime Event State";
BA_ "SignalLongName" SG_ 1304 DMSDrwDrvrDispTmSnLstBrk "Driver Monitoring System Drowsy Driver Display Time Since Last Break";
BA_ "SignalLongName" SG_ 1304 DMSDrwIntnDrvrHptcStReqPuls "Driver Monitoring System Drowsy and Inattentive Driver Haptic Seat Request : Driver Monitoring System Drowsy and Inattentive Driver Haptic Seat Request Pulses";
BA_ "SignalType" SG_ 1304 DMSDrwDrvrCstCurrSetVal "ENM";
BA_ "SignalLongName" SG_ 1304 DMSDrwDrvrCstCurrSetVal "Driver Monitoring System Drowsy Driver Customization Current Setting Value";
BA_ "SignalType" SG_ 1304 DMSDrwIntnDrvrWrnIndReq "ENM";
BA_ "SignalLongName" SG_ 1304 DMSDrwIntnDrvrWrnIndReq "Driver Monitoring System Drowsy And Inattentive Driver Warning Indication Request";
BA_ "SignalLongName" SG_ 1304 DMSDrwIntnDrvrHptcStReqSeqNum "Driver Monitoring System Drowsy and Inattentive Driver Haptic Seat Request : Driver Monitoring System Drowsy and Inattentive Driver Haptic Seat Request Sequence Number";
BA_ "SignalType" SG_ 1304 DMSDrwDrvrIndReq "ENM";
BA_ "SignalLongName" SG_ 1304 DMSDrwDrvrIndReq "Driver Monitoring System Drowsy Driver Indication Request";
BA_ "SignalType" SG_ 1304 DMSDrwDrvrDispLvl "ENM";
BA_ "SignalLongName" SG_ 1304 DMSDrwDrvrDispLvl "Driver Monitoring System Drowsy Driver Display Level";
BA_ "SignalType" SG_ 1304 DMSIntnDrvrIndReq "ENM";
BA_ "SignalLongName" SG_ 1304 DMSIntnDrvrIndReq "Driver Monitoring System Inattentive Driver Indication Request";
BA_ "SignalType" SG_ 1304 DMSIntnDrvrDispLvl "ENM";
BA_ "SignalLongName" SG_ 1304 DMSIntnDrvrDispLvl "Driver Monitoring System Inattentive Driver Display Level";
BA_ "SignalType" SG_ 1304 DMSIntnDrvrCstCurrSetVal "ENM";
BA_ "SignalLongName" SG_ 1304 DMSIntnDrvrCstCurrSetVal "Driver Monitoring System Inattentive Driver Customization Current Setting Value";
BA_ "SignalType" SG_ 1304 DMSTnDrvrDrwIntnOffUnvIndOn "ENM";
BA_ "SignalLongName" SG_ 1304 DMSTnDrvrDrwIntnOffUnvIndOn "Driver Monitoring System Teen Driver Drowsy And Inattentive Off Unavailable Indication On";
BA_ "SignalType" SG_ 1304 DMSIntnDrvrDispFcsInd "ENM";
BA_ "SignalLongName" SG_ 1304 DMSIntnDrvrDispFcsInd "Driver Monitoring System Inattentive Driver Display Focus Indication";
BA_ "SignalType" SG_ 1304 DMSDrwIntnDrvrDtnMtzdStBltPulRq "ENM";
BA_ "SignalLongName" SG_ 1304 DMSDrwIntnDrvrDtnMtzdStBltPulRq "Driver Monitoring System Drowsy and Inattentive Driver Detection Motorized Seat Belt Pulse Request";
BA_ "SignalLongName" SG_ 544 DMSEyeLocInfoXCrdnt "Driver Monitoring System Eye Gaze Information : Driver Monitoring System Eye Location Information X Coordinate";
BA_ "SignalLongName" SG_ 544 DMSEyeLocInfoYCrdnt "Driver Monitoring System Eye Gaze Information : Driver Monitoring System Eye Location Information Y Coordinate";
BA_ "SignalLongName" SG_ 544 DMSEyeLocInfoZCrdnt "Driver Monitoring System Eye Gaze Information : Driver Monitoring System Eye Location Information Z Coordinate";
BA_ "SignalLongName" SG_ 544 DMSEyeGzInfoPrd "Driver Monitoring System Eye Gaze Information : Driver Monitoring System Eye Gaze Information Period";
BA_ "SignalLongName" SG_ 544 DMSEyeGzVctrPtch "Driver Monitoring System Eye Gaze Information : Driver Monitoring System Eye Gaze Vector Pitch";
BA_ "SignalLongName" SG_ 544 DMSEyeGzVctrRoll "Driver Monitoring System Eye Gaze Information : Driver Monitoring System Eye Gaze Vector Roll";
BA_ "SignalLongName" SG_ 544 DMSEyeGzVctrYaw "Driver Monitoring System Eye Gaze Information : Driver Monitoring System Eye Gaze Vector Yaw";
BA_ "SignalLongName" SG_ 1341 SD227_ARC "Serial Data 227 : Alive Rolling Count";
BA_ "SignalType" SG_ 1341 VehDynsTkDtctSts "ENM";
BA_ "SignalLongName" SG_ 1341 VehDynsTkDtctSts "Serial Data 227 : Vehicle Dynamics Track Detect Status";
BA_ "SignalType" SG_ 1239 PrkAsstTrHtchPsntCstAvlFlg1 "ENM";
BA_ "SignalLongName" SG_ 1239 PrkAsstTrHtchPsntCstAvlFlg1 "Park Assist Trailer Hitch Present Customization Availability Flag 1";
BA_ "SignalType" SG_ 1239 PrkAsstONOFFCstAvlFlg7 "ENM";
BA_ "SignalLongName" SG_ 1239 PrkAsstONOFFCstAvlFlg7 "Park Assist On Off Customization Availability Flag 7";
BA_ "SignalType" SG_ 1239 PrkAsstONOFFCstAvlFlg6 "ENM";
BA_ "SignalLongName" SG_ 1239 PrkAsstONOFFCstAvlFlg6 "Park Assist On Off Customization Availability Flag 6";
BA_ "SignalType" SG_ 1239 PrkAsstONOFFCstAvlFlg5 "ENM";
BA_ "SignalLongName" SG_ 1239 PrkAsstONOFFCstAvlFlg5 "Park Assist On Off Customization Availability Flag 5";
BA_ "SignalType" SG_ 1239 PrkAsstONOFFCstAvlFlg4 "ENM";
BA_ "SignalLongName" SG_ 1239 PrkAsstONOFFCstAvlFlg4 "Park Assist On Off Customization Availability Flag 4";
BA_ "SignalType" SG_ 1239 PrkAsstONOFFCstAvlFlg3 "ENM";
BA_ "SignalLongName" SG_ 1239 PrkAsstONOFFCstAvlFlg3 "Park Assist On Off Customization Availability Flag 3";
BA_ "SignalType" SG_ 1239 PrkAsstONOFFCstAvlFlg2 "ENM";
BA_ "SignalLongName" SG_ 1239 PrkAsstONOFFCstAvlFlg2 "Park Assist On Off Customization Availability Flag2";
BA_ "SignalType" SG_ 1239 PrkAsstONOFFCstAvlFlg1 "ENM";
BA_ "SignalLongName" SG_ 1239 PrkAsstONOFFCstAvlFlg1 "Park Assist On Off Customization Availability Flag 1";
BA_ "SignalType" SG_ 1239 PrkAsstTrHtchPsntCstAvlFlg7 "ENM";
BA_ "SignalLongName" SG_ 1239 PrkAsstTrHtchPsntCstAvlFlg7 "Park Assist Trailer Hitch Present Customization Availability Flag 7";
BA_ "SignalType" SG_ 1239 PrkAsstTrHtchPsntCstAvlFlg6 "ENM";
BA_ "SignalLongName" SG_ 1239 PrkAsstTrHtchPsntCstAvlFlg6 "Park Assist Trailer Hitch Present Customization Availability Flag 6";
BA_ "SignalType" SG_ 1239 PrkAsstTrHtchPsntCstAvlFlg5 "ENM";
BA_ "SignalLongName" SG_ 1239 PrkAsstTrHtchPsntCstAvlFlg5 "Park Assist Trailer Hitch Present Customization Availability Flag 5";
BA_ "SignalType" SG_ 1239 PrkAsstTrHtchPsntCstAvlFlg4 "ENM";
BA_ "SignalLongName" SG_ 1239 PrkAsstTrHtchPsntCstAvlFlg4 "Park Assist Trailer Hitch Present Customization Availability Flag 4";
BA_ "SignalType" SG_ 1239 PrkAsstTrHtchPsntCstAvlFlg3 "ENM";
BA_ "SignalLongName" SG_ 1239 PrkAsstTrHtchPsntCstAvlFlg3 "Park Assist Trailer Hitch Present Customization Availability Flag 3";
BA_ "SignalType" SG_ 1239 PrkAsstTrHtchPsntCstAvlFlg2 "ENM";
BA_ "SignalLongName" SG_ 1239 PrkAsstTrHtchPsntCstAvlFlg2 "Park Assist Trailer Hitch Present Customization Availability Flag 2";
BA_ "SignalLongName" SG_ 942 ALCGI_PV "Automatic Leveling Control General Information : Protection Value";
BA_ "SignalLongName" SG_ 942 ALCGI_ARC "Automatic Leveling Control General Information : Alive Rolling Count";
BA_ "SignalType" SG_ 942 ALCGI_VehTopSpdLimReqTyp "ENM";
BA_ "SignalLongName" SG_ 942 ALCGI_VehTopSpdLimReqTyp "Automatic Leveling Control General Information : Vehicle Top Speed Limit Request Type";
BA_ "SignalType" SG_ 942 ALCGI_RideHghtESCEnblReqd "ENM";
BA_ "SignalLongName" SG_ 942 ALCGI_RideHghtESCEnblReqd "Automatic Leveling Control General Information : Ride Height Electronic Stability Control Enable Requested";
BA_ "SignalLongName" SG_ 942 ALCGI_VehTopSpdLimReqVal "Automatic Leveling Control General Information : Vehicle Top Speed Limit Request Value";
BA_ "SignalLongName" SG_ 943 VLCGI_4CrnrLvlTopSpdLimReqVal "Vehicle Leveling Control General Information : Four Corner Leveling Top Speed Limit Request Value";
BA_ "SignalType" SG_ 943 VLCGI_4CrnrLvlTopSpdLimReqTyp "ENM";
BA_ "SignalLongName" SG_ 943 VLCGI_4CrnrLvlTopSpdLimReqTyp "Vehicle Leveling Control General Information : Four Corner Leveling Top Speed Limit Request Type";
BA_ "SignalType" SG_ 943 VLCGI_4CrnrLvlESCEnblReqd "ENM";
BA_ "SignalLongName" SG_ 943 VLCGI_4CrnrLvlESCEnblReqd "Vehicle Leveling Control General Information : Four Corner Leveling Electronic Stability Control Enable Requested";
BA_ "SignalLongName" SG_ 943 VLCGI_PV "Vehicle Leveling Control General Information : Protection Value";
BA_ "SignalLongName" SG_ 943 VLCGI_ARC "Vehicle Leveling Control General Information : Alive Rolling Count";
BA_ "SignalType" SG_ 1346 RrwdImpMtgnAval "ENM";
BA_ "SignalLongName" SG_ 1346 RrwdImpMtgnAval "Rearward Impact Mitigation Available";
BA_ "SignalLongName" SG_ 1251 SBMERDTC_CdNum "Secondary Braking Module Emissions Related DTC : Code Number";
BA_ "SignalType" SG_ 1251 SBMERDTC_SysDes "ENM";
BA_ "SignalLongName" SG_ 1251 SBMERDTC_SysDes "Secondary Braking Module Emissions Related DTC : System Designator";
BA_ "SignalLongName" SG_ 1251 PIMRI_SBM_RcntlyProgInd "Programming Inspection and Maintenance Readiness Indication - SBM : Recently Programmed Indicator";
BA_ "SignalType" SG_ 1251 PIMRI_SBM_PrmntDTCInd "ENM";
BA_ "SignalLongName" SG_ 1251 PIMRI_SBM_PrmntDTCInd "Programming Inspection and Maintenance Readiness Indication - SBM : Permanent DTC Indicator";
BA_ "SignalType" SG_ 1251 PIMRI_SBM_FltsPrsntInd "ENM";
BA_ "SignalLongName" SG_ 1251 PIMRI_SBM_FltsPrsntInd "Programming Inspection and Maintenance Readiness Indication - SBM : Faults Present Indicator";
BA_ "SignalType" SG_ 1251 SBMEmsRltMlfAtv "ENM";
BA_ "SignalLongName" SG_ 1251 SBMEmsRltMlfAtv "Secondary Braking Module Emissions Related Malfunction Active";
BA_ "SignalType" SG_ 1429 RrClsrAjrStat "ENM";
BA_ "SignalLongName" SG_ 1429 RrClsrAjrStat "Rear Closure Ajar Status";
BA_ "SignalType" SG_ 1429 RrClsrAjrStat_Inv "ENM";
BA_ "SignalLongName" SG_ 1429 RrClsrAjrStat_Inv "Rear Closure Ajar Status Invalid";
BA_ "SignalLongName" SG_ 1810 CldrYr "Calendar Date And Time : Year";
BA_ "SignalLongName" SG_ 1810 SecOfMin "Calendar Date And Time : Seconds";
BA_ "SignalLongName" SG_ 1810 MinOfHr "Calendar Date And Time : Minutes";
BA_ "SignalLongName" SG_ 1810 CldrDay "Calendar Date And Time : Day";
BA_ "SignalType" SG_ 1810 CldrMth "ENM";
BA_ "SignalLongName" SG_ 1810 CldrMth "Calendar Date And Time : Month";
BA_ "SignalLongName" SG_ 1810 HrOfDay "Calendar Date And Time : Hours";
BA_ "SignalLongName" SG_ 1443 TODCSR_ChrgSchedHrOfDyReq "Time of Day Charging Setting Request : Charge Schedule Hour of Day Request";
BA_ "SignalType" SG_ 1443 TODCSR_ChrgSchedDyOfWkReq "ENM";
BA_ "SignalLongName" SG_ 1443 TODCSR_ChrgSchedDyOfWkReq "Time of Day Charging Setting Request : Charge Schedule Day of Week Request";
BA_ "SignalType" SG_ 1443 TODCSR_ChrgSchedCstSetReq "ENM";
BA_ "SignalLongName" SG_ 1443 TODCSR_ChrgSchedCstSetReq "Time of Day Charging Setting Request : Charge Schedule Customization Setting Request";
BA_ "SignalLongName" SG_ 1443 TODCSR_ChrgSchedMinOfHrReq "Time of Day Charging Setting Request : Charge Schedule Minute of Hour Request";
BA_ "SignalLongName" SG_ 1443 TODCSR_ERSPrdHrOfDyReq "Time of Day Charging Setting Request : Electric Rate Schedule Period Hour of Day Request";
BA_ "SignalType" SG_ 1443 TODCSR_ERSPrdDyReq "ENM";
BA_ "SignalLongName" SG_ 1443 TODCSR_ERSPrdDyReq "Time of Day Charging Setting Request : Electric Rate Schedule Period Day Request";
BA_ "SignalType" SG_ 1443 TODCSR_ERSCstSetReq "ENM";
BA_ "SignalLongName" SG_ 1443 TODCSR_ERSCstSetReq "Time of Day Charging Setting Request : Electric Rate Schedule Customization Setting Request";
BA_ "SignalLongName" SG_ 1443 TODCSR_ERSPrdMinOfHrReq "Time of Day Charging Setting Request : Electric Rate Schedule Period Minute of Hour Request";
BA_ "SignalType" SG_ 1443 TODCSR_ERSPrdLvlReq "ENM";
BA_ "SignalLongName" SG_ 1443 TODCSR_ERSPrdLvlReq "Time of Day Charging Setting Request : Electric Rate Schedule Period Level Request";
BA_ "SignalType" SG_ 1443 PrtblChrgCordLimCstSetReq "ENM";
BA_ "SignalLongName" SG_ 1443 PrtblChrgCordLimCstSetReq "Time of Day Charging Setting Request : Portable Charge Cord Limit Customization Setting Request";
BA_ "SignalType" SG_ 1443 TODCSR_ERSPrfReq "ENM";
BA_ "SignalLongName" SG_ 1443 TODCSR_ERSPrfReq "Time of Day Charging Setting Request : Electric Rate Schedule Preference Request";
BA_ "SignalType" SG_ 1443 TODCCbnPrcndtngSetReq "ENM";
BA_ "SignalLongName" SG_ 1443 TODCCbnPrcndtngSetReq "Time of Day Charging Setting Request : Time of Day Charging Cabin Preconditioning Setting Request";
BA_ "SignalType" SG_ 1443 TODCSR_LocNumReq "ENM";
BA_ "SignalLongName" SG_ 1443 TODCSR_LocNumReq "Time of Day Charging Setting Request : Location Number Request";
BA_ "SignalType" SG_ 1443 TODCSR_LocChrgPwrLvlReq "ENM";
BA_ "SignalLongName" SG_ 1443 TODCSR_LocChrgPwrLvlReq "Time of Day Charging Setting Request : Location Charging Power Level Request";
BA_ "SignalLongName" SG_ 1443 TODCSR_TgtChrgLvlReq "Time of Day Charging Setting Request : Target Charge Level Request";
BA_ "SignalLongName" SG_ 1425 Sig0086 "Signal0018";
BA_ "SignalType" SG_ 1425 Sig0087 "ENM";
BA_ "SignalLongName" SG_ 1425 Sig0087 "Signal0019";
BA_ "SignalLongName" SG_ 1425 Sig0088 "Signal0020";
BA_ "SignalType" SG_ 1425 Sig0084 "ENM";
BA_ "SignalLongName" SG_ 1425 Sig0084 "Signal0015";
BA_ "SignalType" SG_ 1425 Sig0079 "ENM";
BA_ "SignalLongName" SG_ 1425 Sig0079 "Signal0006";
BA_ "SignalType" SG_ 1425 Sig0078 "ENM";
BA_ "SignalLongName" SG_ 1425 Sig0078 "Signal0013";
BA_ "SignalType" SG_ 1425 Sig0083 "ENM";
BA_ "SignalLongName" SG_ 1425 Sig0083 "Signal0014";
BA_ "SignalType" SG_ 1425 ADASIS_NAVILINK_FncRdClss "ENM";
BA_ "SignalLongName" SG_ 1425 ADASIS_NAVILINK_FncRdClss "ADASIS NAVILINK Functional Road Class";
BA_ "SignalType" SG_ 1425 Sig0081 "ENM";
BA_ "SignalLongName" SG_ 1425 Sig0081 "Signal0010";
BA_ "SignalType" SG_ 1425 Sig0090 "ENM";
BA_ "SignalLongName" SG_ 1425 Sig0090 "Signal0017";
BA_ "SignalType" SG_ 1425 Sig0089 "ENM";
BA_ "SignalLongName" SG_ 1425 Sig0089 "Signal0021";
BA_ "SignalType" SG_ 1425 ADASIS_NAVILINK_MpDtAv "ENM";
BA_ "SignalLongName" SG_ 1425 ADASIS_NAVILINK_MpDtAv "ADASIS NAVILINK Map data availability";
BA_ "SignalType" SG_ 1425 Sig0082 "ENM";
BA_ "SignalLongName" SG_ 1425 Sig0082 "Signal0012";
BA_ "SignalType" SG_ 1425 Sig0080 "ENM";
BA_ "SignalLongName" SG_ 1425 Sig0080 "Signal0008";
BA_ "SignalType" SG_ 1425 Sig0085 "ENM";
BA_ "SignalLongName" SG_ 1425 Sig0085 "Signal0016";
BA_ "SignalType" SG_ 718 HVWrlsChrgStopReqd "ENM";
BA_ "SignalLongName" SG_ 718 HVWrlsChrgStopReqd "High Voltage Wireless Charging Stop Requested";
BA_ "SignalType" SG_ 718 HVWrlsChrgWiFiConctSts "ENM";
BA_ "SignalLongName" SG_ 718 HVWrlsChrgWiFiConctSts "High Voltage Wireless Charging Wi-Fi Connection Status";
BA_ "SignalType" SG_ 718 HVWrlsChrgSysFltSts "ENM";
BA_ "SignalLongName" SG_ 718 HVWrlsChrgSysFltSts "High Voltage Wireless Charging System Fault Status";
BA_ "SignalType" SG_ 730 HVWrlsChrgLivngObjDtd "ENM";
BA_ "SignalLongName" SG_ 730 HVWrlsChrgLivngObjDtd "High Voltage Wireless Charging Living Object Detected";
BA_ "SignalType" SG_ 730 HVWrlsChrgFrgnObjDtd "ENM";
BA_ "SignalLongName" SG_ 730 HVWrlsChrgFrgnObjDtd "High Voltage Wireless Charging Foreign Object Detected";
BA_ "SignalLongName" SG_ 716 HVWrlsChrgRctfrTemp "High Voltage Wireless Charging Rectifier Temperature";
BA_ "SignalType" SG_ 716 HVWrlsChrgRctfrTemp_Inv "ENM";
BA_ "SignalLongName" SG_ 716 HVWrlsChrgRctfrTemp_Inv "High Voltage Wireless Charging Rectifier Temperature Invalid";
BA_ "SignalLongName" SG_ 716 HVWrlsChrgVehCoilTempA "High Voltage Wireless Charging Vehicle Coil Temperature A";
BA_ "SignalType" SG_ 716 HVWrlsChrgVehCoilTempA_Inv "ENM";
BA_ "SignalLongName" SG_ 716 HVWrlsChrgVehCoilTempA_Inv "High Voltage Wireless Charging Vehicle Coil Temperature A Invalid";
BA_ "SignalLongName" SG_ 716 HVWrlsChrgVehCoilTempB "High Voltage Wireless Charging Vehicle Coil Temperature B";
BA_ "SignalType" SG_ 716 HVWrlsChrgVehCoilTempB_Inv "ENM";
BA_ "SignalLongName" SG_ 716 HVWrlsChrgVehCoilTempB_Inv "High Voltage Wireless Charging Vehicle Coil Temperature B Invalid";
BA_ "SignalType" SG_ 717 HVWrlsChrgIntopbltCkSts "ENM";
BA_ "SignalLongName" SG_ 717 HVWrlsChrgIntopbltCkSts "High Voltage Wireless Charging Interoperability Checking Status";
BA_ "SignalType" SG_ 717 HVWrlsChrgIntopbltCkFldRsn "ENM";
BA_ "SignalLongName" SG_ 717 HVWrlsChrgIntopbltCkFldRsn "High Voltage Wireless Charging Interoperability Checking Failed Reason";
BA_ "SignalLongName" SG_ 177 HVWrlsChrgACGridPwr "High Voltage Wireless Charging AC Grid Power";
BA_ "SignalType" SG_ 177 HVWrlsChrgACGridPwr_Inv "ENM";
BA_ "SignalLongName" SG_ 177 HVWrlsChrgACGridPwr_Inv "High Voltage Wireless Charging AC Grid Power Invalid";
BA_ "SignalLongName" SG_ 177 HVWrlsChrgDCOutCurr "High Voltage Wireless Charging DC Output Current";
BA_ "SignalType" SG_ 177 HVWrlsChrgDCOutCurr_Inv "ENM";
BA_ "SignalLongName" SG_ 177 HVWrlsChrgDCOutCurr_Inv "High Voltage Wireless Charging DC Output Current Invalid";
BA_ "SignalLongName" SG_ 177 HVWrlsChrgSysCurrLim "High Voltage Wireless Charging System Current Limit";
BA_ "SignalType" SG_ 177 HVWrlsChrgSysCurrLim_Inv "ENM";
BA_ "SignalLongName" SG_ 177 HVWrlsChrgSysCurrLim_Inv "High Voltage Wireless Charging System Current Limit Invalid";
BA_ "SignalLongName" SG_ 177 HVWrlsChrgDCOutVltg "High Voltage Wireless Charging DC Output Voltage";
BA_ "SignalType" SG_ 177 HVWrlsChrgDCOutVltg_Inv "ENM";
BA_ "SignalLongName" SG_ 177 HVWrlsChrgDCOutVltg_Inv "High Voltage Wireless Charging DC Output Voltage Invalid";
BA_ "SignalType" SG_ 177 HVWrlsChrgAlgnCkRespVal_Inv "ENM";
BA_ "SignalLongName" SG_ 177 HVWrlsChrgAlgnCkRespVal_Inv "High Voltage Wireless Charging Alignment Check Response Value Invalid";
BA_ "SignalLongName" SG_ 177 HVWrlsChrgAlgnCkRespVal "High Voltage Wireless Charging Alignment Check Response Value";
BA_ "SignalType" SG_ 535 HVWrlsChrgSysStat "ENM";
BA_ "SignalLongName" SG_ 535 HVWrlsChrgSysStat "High Voltage Wireless Charging System State";
BA_ "SignalType" SG_ 1479 Sig3479 "ENM";
BA_ "SignalLongName" SG_ 1479 Sig3479 "Signal3246";
BA_ "SignalType" SG_ 1479 Sig3477 "ENM";
BA_ "SignalLongName" SG_ 1479 Sig3477 "Signal3244";
BA_ "SignalType" SG_ 1479 Sig3476 "ENM";
BA_ "SignalLongName" SG_ 1479 Sig3476 "Signal3243";
BA_ "SignalType" SG_ 1479 Sig3508 "ENM";
BA_ "SignalLongName" SG_ 1479 Sig3508 "Signal3897";
BA_ "SignalType" SG_ 1479 Sig3478 "ENM";
BA_ "SignalLongName" SG_ 1479 Sig3478 "Signal3245";
BA_ "SignalType" SG_ 1824 Sig7678 "ENM";
BA_ "SignalLongName" SG_ 1824 Sig7678 "Signal7624";
BA_ "SignalType" SG_ 1824 Sig7675 "ENM";
BA_ "SignalLongName" SG_ 1824 Sig7675 "Signal7621";
BA_ "SignalType" SG_ 1824 Sig7674 "ENM";
BA_ "SignalLongName" SG_ 1824 Sig7674 "Signal7620";
BA_ "SignalType" SG_ 1824 Sig7673 "ENM";
BA_ "SignalLongName" SG_ 1824 Sig7673 "Signal7619";
BA_ "SignalType" SG_ 1824 Sig7672 "ENM";
BA_ "SignalLongName" SG_ 1824 Sig7672 "Signal7618";
BA_ "SignalType" SG_ 1824 Sig7671 "ENM";
BA_ "SignalLongName" SG_ 1824 Sig7671 "Signal7617";
BA_ "SignalType" SG_ 1824 Sig7670 "ENM";
BA_ "SignalLongName" SG_ 1824 Sig7670 "Signal7616";
BA_ "SignalType" SG_ 1824 Sig7669 "ENM";
BA_ "SignalLongName" SG_ 1824 Sig7669 "Signal7615";
BA_ "SignalType" SG_ 1824 Sig7686 "ENM";
BA_ "SignalLongName" SG_ 1824 Sig7686 "Signal7638";
BA_ "SignalType" SG_ 1824 Sig7685 "ENM";
BA_ "SignalLongName" SG_ 1824 Sig7685 "Signal7637";
BA_ "SignalType" SG_ 1824 Sig7684 "ENM";
BA_ "SignalLongName" SG_ 1824 Sig7684 "Signal7636";
BA_ "SignalType" SG_ 1824 Sig7683 "ENM";
BA_ "SignalLongName" SG_ 1824 Sig7683 "Signal7635";
BA_ "SignalType" SG_ 1824 Sig7682 "ENM";
BA_ "SignalLongName" SG_ 1824 Sig7682 "Signal7634";
BA_ "SignalType" SG_ 1824 Sig7681 "ENM";
BA_ "SignalLongName" SG_ 1824 Sig7681 "Signal7633";
BA_ "SignalType" SG_ 1824 Sig7680 "ENM";
BA_ "SignalLongName" SG_ 1824 Sig7680 "Signal7632";
BA_ "SignalType" SG_ 1824 TrfcSgnMemOfstEnbld "ENM";
BA_ "SignalLongName" SG_ 1824 TrfcSgnMemOfstEnbld "Traffic Sign Memory Offset Enabled";
BA_ "SignalType" SG_ 1824 Sig7698 "ENM";
BA_ "SignalLongName" SG_ 1824 Sig7698 "Signal7655";
BA_ "SignalType" SG_ 1824 Sig7697 "ENM";
BA_ "SignalLongName" SG_ 1824 Sig7697 "Signal7654";
BA_ "SignalType" SG_ 1824 Sig7696 "ENM";
BA_ "SignalLongName" SG_ 1824 Sig7696 "Signal7653";
BA_ "SignalType" SG_ 1824 Sig7695 "ENM";
BA_ "SignalLongName" SG_ 1824 Sig7695 "Signal7652";
BA_ "SignalType" SG_ 1824 Sig7694 "ENM";
BA_ "SignalLongName" SG_ 1824 Sig7694 "Signal7651";
BA_ "SignalType" SG_ 1824 Sig7693 "ENM";
BA_ "SignalLongName" SG_ 1824 Sig7693 "Signal7650";
BA_ "SignalType" SG_ 1824 Sig7692 "ENM";
BA_ "SignalLongName" SG_ 1824 Sig7692 "Signal7649";
BA_ "SignalType" SG_ 1824 Sig7688 "ENM";
BA_ "SignalLongName" SG_ 1824 Sig7688 "Signal7641";
BA_ "SignalType" SG_ 1824 Sig7699 "ENM";
BA_ "SignalLongName" SG_ 1824 Sig7699 "Signal7658";
BA_ "SignalType" SG_ 1339 Sig7687 "ENM";
BA_ "SignalLongName" SG_ 1339 Sig7687 "Signal7639";
BA_ "SignalType" SG_ 1339 Sig7676 "ENM";
BA_ "SignalLongName" SG_ 1339 Sig7676 "Signal7622";
BA_ "SignalType" SG_ 1339 Sig7667 "ENM";
BA_ "SignalLongName" SG_ 1339 Sig7667 "Signal7656";
BA_ "SignalType" SG_ 1242 Sig7691 "ENM";
BA_ "SignalLongName" SG_ 1242 Sig7691 "Signal7646";
BA_ "SignalType" SG_ 1242 Sig7689 "ENM";
BA_ "SignalLongName" SG_ 1242 Sig7689 "Signal7642";
BA_ "SignalType" SG_ 1952 Sig7677 "ENM";
BA_ "SignalLongName" SG_ 1952 Sig7677 "Signal7623";
BA_ "SignalType" SG_ 1952 Sig7668 "ENM";
BA_ "SignalLongName" SG_ 1952 Sig7668 "Signal7657";
BA_ "SignalType" SG_ 1952 Sig7666 "ENM";
BA_ "SignalLongName" SG_ 1952 Sig7666 "Signal7640";
BA_ "SignalType" SG_ 1952 Sig7690 "ENM";
BA_ "SignalLongName" SG_ 1952 Sig7690 "Signal7643";
BA_ "SignalType" SG_ 1952 Sig7679 "ENM";
BA_ "SignalLongName" SG_ 1952 Sig7679 "Signal7625";
BA_ "SignalLongName" SG_ 728 EE46ecGridVltgTgt "Electrical Power Management Secondary Grid Voltage Target";
BA_ "SignalLongName" SG_ 728 OutsdAmbtLgtLvl "Outside Ambient Light Level";
BA_ "SignalLongName" SG_ 728 ACCompNormLd "Air Conditioning Compressor Normalized Load";
BA_ "SignalType" SG_ 728 ACCompNormLd_Inv "ENM";
BA_ "SignalLongName" SG_ 728 ACCompNormLd_Inv "Air Conditioning Compressor Normalized Load Invalid";
BA_ "SignalType" SG_ 728 OutsdAmbtLgtLvl_Inv "ENM";
BA_ "SignalLongName" SG_ 728 OutsdAmbtLgtLvl_Inv "Outside Ambient Light Level Invalid";
BA_ "SignalType" SG_ 728 OutsdAmbtLgtLvl_DuD "ENM";
BA_ "SignalLongName" SG_ 728 OutsdAmbtLgtLvl_DuD "Outside Ambient Light Level Don't Use Data";
BA_ "SignalType" SG_ 728 PFMinIdlBsRq "ENM";
BA_ "SignalLongName" SG_ 728 PFMinIdlBsRq "Platform Minimum Idle Boost Level Request";
BA_ "SignalType" SG_ 728 StBltShfIntlkReqSts "ENM";
BA_ "SignalLongName" SG_ 728 StBltShfIntlkReqSts "Seatbelt Shift Interlock Request Status";
BA_ "SignalType" SG_ 728 LDWCtrlSwSts "ENM";
BA_ "SignalLongName" SG_ 728 LDWCtrlSwSts "Lane Detection Warning and Control Switch Status";
BA_ "SignalType" SG_ 728 EE46ecGridVltgOvrrdPrty "ENM";
BA_ "SignalLongName" SG_ 728 EE46ecGridVltgOvrrdPrty "Electrical Power Management Secondary Grid Voltage Override Priority";
BA_ "SignalType" SG_ 728 ACCompModReq "ENM";
BA_ "SignalLongName" SG_ 728 ACCompModReq "Air Conditioning Compressor Mode Request";
BA_ "SignalType" SG_ 728 FOPPriGridOvrrdActv "ENM";
BA_ "SignalLongName" SG_ 728 FOPPriGridOvrrdActv "Fail Operational Power Primary Grid Override Active";
BA_ "SignalType" SG_ 728 EPMGridIsltnReqd "ENM";
BA_ "SignalLongName" SG_ 728 EPMGridIsltnReqd "Electrical Power Management Grid Isolation Requested";
BA_ "SignalType" SG_ 728 ClntCircPmpRq "ENM";
BA_ "SignalLongName" SG_ 728 ClntCircPmpRq "Coolant Circulation Pump Request";
BA_ "SignalType" SG_ 728 ClmtCtrlHtrEngRunRq "ENM";
BA_ "SignalLongName" SG_ 728 ClmtCtrlHtrEngRunRq "Climate Control Heater Engine Run Request";
BA_ "SignalType" SG_ 728 BdyCtrlEmsRltMlfAtv "ENM";
BA_ "SignalLongName" SG_ 728 BdyCtrlEmsRltMlfAtv "Body Control Emissions Related Malfunction Active";
BA_ "SignalType" SG_ 728 ACCmpsrFldOn "ENM";
BA_ "SignalLongName" SG_ 728 ACCmpsrFldOn "Air Conditioning Compressor Failed On";
BA_ "SignalType" SG_ 728 ACCmEngRunReq "ENM";
BA_ "SignalLongName" SG_ 728 ACCmEngRunReq "Air Conditioning Compressor Engine Run Request";
BA_ "SignalType" SG_ 728 PlatEngSpdCmdSysTyp "ENM";
BA_ "SignalLongName" SG_ 728 PlatEngSpdCmdSysTyp "Platform Engine Speed Command System Type";
BA_ "SignalType" SG_ 728 LdMeToCarActv "ENM";
BA_ "SignalLongName" SG_ 728 LdMeToCarActv "Lead Me To The Car Active";
BA_ "SignalLongName" SG_ 1442 IBS12VBatCurrExtndRng "Intelligent Battery Sensor 12V Battery Information : IBS 12V Battery Current Extended Range";
BA_ "SignalLongName" SG_ 1442 IBS12VEnhdBatSOC "Intelligent Battery Sensor 12V Battery Information : IBS 12V Enhanced Battery State of Charge";
BA_ "SignalType" SG_ 1442 IBS12VBatCurrExtndRng_Inv "ENM";
BA_ "SignalLongName" SG_ 1442 IBS12VBatCurrExtndRng_Inv "Intelligent Battery Sensor 12V Battery Information : IBS 12V Battery Current Extended Range Invalid";
BA_ "SignalLongName" SG_ 1442 IBS12VEnhdBatSOCErr "Intelligent Battery Sensor 12V Battery Information : IBS 12V Enhanced Battery State Of Charge Error";
BA_ "SignalLongName" SG_ 1442 IBS12VEnhdBatSOCMin "Intelligent Battery Sensor 12V Battery Information : IBS 12V Enhanced Battery State Of Charge Minmum";
BA_ "SignalLongName" SG_ 1442 IBS12VEstdBatTemp "Intelligent Battery Sensor 12V Battery Information : IBS 12V Estimated Battery Temperature";
BA_ "SignalType" SG_ 1442 IBS12VEstdBatTemp_Inv "ENM";
BA_ "SignalLongName" SG_ 1442 IBS12VEstdBatTemp_Inv "Intelligent Battery Sensor 12V Battery Information : IBS 12V Estimated Battery Temperature Invalid";
BA_ "SignalLongName" SG_ 1442 IBSBatSOH "Intelligent Battery Sensor 12V Battery Information : IBS Battery State of Health";
BA_ "SignalLongName" SG_ 1442 IBSEnhdBatSOF "Intelligent Battery Sensor 12V Battery Information : IBS Enhanced Battery State of Function";
BA_ "SignalLongName" SG_ 1442 IBSMinCrnkgVltg "Intelligent Battery Sensor 12V Battery Information : IBS Minimum Cranking Voltage";
BA_ "SignalType" SG_ 1442 IBSIntrnlFltPr_Inv "ENM";
BA_ "SignalLongName" SG_ 1442 IBSIntrnlFltPr_Inv "Intelligent Battery Sensor 12V Battery Information : Intelligent Battery Sensor Internal Fault Present Invalid";
BA_ "SignalType" SG_ 1442 IBSIntrnlFltPr "ENM";
BA_ "SignalLongName" SG_ 1442 IBSIntrnlFltPr "Intelligent Battery Sensor 12V Battery Information : Intelligent Battery Sensor Internal Fault Present";
BA_ "SignalLongName" SG_ 1442 IBSRwBatSOC "Intelligent Battery Sensor 12V Battery Information : IBS 12V Battery State of Charge";
BA_ "SignalLongName" SG_ 1442 IBSRwBatSOCErr "Intelligent Battery Sensor 12V Battery Information : IBS Raw Battery SOC Error";
BA_ "SignalLongName" SG_ 1442 ElpsdTimeCnt "Elapsed Time Count";
BA_ "SignalLongName" SG_ 1442 EnhdElpsdTmCnt "Enhanced Elapsed Time Count";
BA_ "SignalLongName" SG_ 1442 BCERDTC_CdNum "Body Control Emissions Related DTC : Code Number";
BA_ "SignalType" SG_ 1442 BCERDTC_SysDes "ENM";
BA_ "SignalLongName" SG_ 1442 BCERDTC_SysDes "Body Control Emissions Related DTC : System Designator";
BA_ "SignalLongName" SG_ 1442 EngOffTmExtndRng "Engine OFF Time Signal Group : Engine OFF Time Extended Range";
BA_ "SignalType" SG_ 1442 EngOffTmExtndRng_Inv "ENM";
BA_ "SignalLongName" SG_ 1442 EngOffTmExtndRng_Inv "Engine OFF Time Signal Group : Engine OFF Time Invalid";
BA_ "SignalLongName" SG_ 1442 EngPrfID "Engine Performance Identifier";
BA_ "SignalType" SG_ 1442 EnhdElpsdTmCntDgrd "ENM";
BA_ "SignalLongName" SG_ 1442 EnhdElpsdTmCntDgrd "Enhanced Elapsed Time Count Degraded";
BA_ "SignalType" SG_ 1442 ElpsdTimeCntRstOcc "ENM";
BA_ "SignalLongName" SG_ 1442 ElpsdTimeCntRstOcc "Elapsed Time Count Reset Occurred";
BA_ "SignalLongName" SG_ 1442 IBS12VBatVlt "Intelligent Battery Sensor 12V Battery Information : IBS 12V Battery Voltage";
BA_ "SignalType" SG_ 1442 TrnstStrgLogisticsMdActivation "ENM";
BA_ "SignalLongName" SG_ 1442 TrnstStrgLogisticsMdActivation "Transport/Storage Logistics Mode Activation";
BA_ "SignalType" SG_ 1442 RstrctdPwrtrnOpModeReqd "ENM";
BA_ "SignalLongName" SG_ 1442 RstrctdPwrtrnOpModeReqd "Restricted Powertrain Operation Mode Requested";
BA_ "SignalType" SG_ 1442 PrtctdIdlShftrLckReq "ENM";
BA_ "SignalLongName" SG_ 1442 PrtctdIdlShftrLckReq "Protected Idle Shifter Lock Request";
BA_ "SignalType" SG_ 1442 FgLmpFrtFncActv "ENM";
BA_ "SignalLongName" SG_ 1442 FgLmpFrtFncActv "Fog Lamp Front Function Active";
BA_ "SignalType" SG_ 1442 ExtLgtChrgphyFrtActvn "ENM";
BA_ "SignalLongName" SG_ 1442 ExtLgtChrgphyFrtActvn "Exterior Lighting Choreography Activation Information : Exterior Lighting Choreography Front Activation";
BA_ "SignalType" SG_ 1442 IBS12VBatVlt_Inv "ENM";
BA_ "SignalLongName" SG_ 1442 IBS12VBatVlt_Inv "Intelligent Battery Sensor 12V Battery Information : IBS 12V Battery Voltage Invalid";
BA_ "SignalType" SG_ 702 BGI5_TrnLmpLtOtgDtd "ENM";
BA_ "SignalLongName" SG_ 702 BGI5_TrnLmpLtOtgDtd "Body General Information 5 : Turn Lamp Left Outage Detected";
BA_ "SignalType" SG_ 702 BGI5_TrnLmpLtFncActv "ENM";
BA_ "SignalLongName" SG_ 702 BGI5_TrnLmpLtFncActv "Body General Information 5 : Turn Lamp Left Function Active";
BA_ "SignalLongName" SG_ 702 BGI5_PV "Body General Information 5 : Protected Value";
BA_ "SignalLongName" SG_ 702 BGI5_ARC "Body General Information 5 : Alive Rolling Count";
BA_ "SignalType" SG_ 702 BGI5_TrnLmpRtOtgDtd "ENM";
BA_ "SignalLongName" SG_ 702 BGI5_TrnLmpRtOtgDtd "Body General Information 5 : Turn Lamp Right Outage Detected";
BA_ "SignalType" SG_ 702 BGI5_TrnLmpRtFncActv "ENM";
BA_ "SignalLongName" SG_ 702 BGI5_TrnLmpRtFncActv "Body General Information 5 : Turn Lamp Right Function Active";
BA_ "SignalLongName" SG_ 1464 VehIdNmDig1 "Vehicle Identification Number Digit 1";
BA_ "SignalType" SG_ 1408 PerfTracMgmtModeSwSts "ENM";
BA_ "SignalLongName" SG_ 1408 PerfTracMgmtModeSwSts "Performance Traction Management Mode Switch Status";
BA_ "SignalType" SG_ 1408 AirDflctrSysStat "ENM";
BA_ "SignalLongName" SG_ 1408 AirDflctrSysStat "Air Deflector System State";
BA_ "SignalLongName" SG_ 1408 PIMRI_BCM_RcntlyProgInd "Programming Inspection and Maintenance Readiness Indication - BCM : Recently Programmed Indicator";
BA_ "SignalType" SG_ 1408 PIMRI_BCM_PrmntDTCInd "ENM";
BA_ "SignalLongName" SG_ 1408 PIMRI_BCM_PrmntDTCInd "Programming Inspection and Maintenance Readiness Indication - BCM : Permanent DTC Indicator";
BA_ "SignalType" SG_ 1408 PIMRI_BCM_FltsPrsntInd "ENM";
BA_ "SignalLongName" SG_ 1408 PIMRI_BCM_FltsPrsntInd "Programming Inspection and Maintenance Readiness Indication - BCM : Faults Present Indicator";
BA_ "SignalType" SG_ 1408 LDWCtrlSelctdStatRaw "ENM";
BA_ "SignalLongName" SG_ 1408 LDWCtrlSelctdStatRaw "Lane Detection Warning And Control Selected State Raw";
BA_ "SignalType" SG_ 1408 DrvDrAjrStat "ENM";
BA_ "SignalLongName" SG_ 1408 DrvDrAjrStat "Driver Door Ajar Status";
BA_ "SignalType" SG_ 1408 DrvDrAjrStat_Inv "ENM";
BA_ "SignalLongName" SG_ 1408 DrvDrAjrStat_Inv "Driver Door Ajar Status Invalid";
BA_ "SignalType" SG_ 1408 AE44SeltdStatRw "ENM";
BA_ "SignalLongName" SG_ 1408 AE44SeltdStatRw "Advanced Park Assist Selected State Raw";
BA_ "SignalType" SG_ 1408 WshldWshFtrActv "ENM";
BA_ "SignalLongName" SG_ 1408 WshldWshFtrActv "Windshield Wash Feature Active";
BA_ "SignalType" SG_ 1408 WprFrActUnfltdStat "ENM";
BA_ "SignalLongName" SG_ 1408 WprFrActUnfltdStat "Wiper Front Active Unfiltered Status";
BA_ "SignalType" SG_ 1408 WprFrActFltdStat "ENM";
BA_ "SignalLongName" SG_ 1408 WprFrActFltdStat "Wiper Front Active Filtered Status";
BA_ "SignalType" SG_ 1408 EnhdDrvrSeltdMdSwChsUseActv "ENM";
BA_ "SignalLongName" SG_ 1408 EnhdDrvrSeltdMdSwChsUseActv "Enhanced Driver Selected Mode Switch Chassis Use Active";
BA_ "SignalType" SG_ 1408 VehDynMdSwAct "ENM";
BA_ "SignalLongName" SG_ 1408 VehDynMdSwAct "Vehicle Dynamics Mode Switch Active";
BA_ "SignalType" SG_ 1408 VehDynMdSwAct_Inv "ENM";
BA_ "SignalLongName" SG_ 1408 VehDynMdSwAct_Inv "Vehicle Dynamics Mode Switch Active Invalid";
BA_ "SignalType" SG_ 1408 PerfTracMgmtActvnConfSts "ENM";
BA_ "SignalLongName" SG_ 1408 PerfTracMgmtActvnConfSts "Performance Traction Management Activation Confirmation Status";
BA_ "SignalType" SG_ 1409 TrnSigSwRtActv "ENM";
BA_ "SignalLongName" SG_ 1409 TrnSigSwRtActv "Turn Signal Switch Right Active";
BA_ "SignalType" SG_ 1409 TrnSigSwLtActv "ENM";
BA_ "SignalLongName" SG_ 1409 TrnSigSwLtActv "Turn Signal Switch Left Active";
BA_ "SignalType" SG_ 1409 PrkBrkSwAtv "ENM";
BA_ "SignalLongName" SG_ 1409 PrkBrkSwAtv "Park Brake Switch Active";
BA_ "SignalType" SG_ 1409 BrkLtsAtv "ENM";
BA_ "SignalLongName" SG_ 1409 BrkLtsAtv "Brake Lights Active";
BA_ "SignalLongName" SG_ 932 RatlzdEVDCCompVlvLSDCurrFbk "Serial Data 118 : Rationalized EVDC Compressor Valve LSD Current Feedback";
BA_ "SignalType" SG_ 932 RatlzdEVDCCompVlvLSDCurrFbk_Inv "ENM";
BA_ "SignalLongName" SG_ 932 RatlzdEVDCCompVlvLSDCurrFbk_Inv "Serial Data 118 : Rationalized EVDC Compressor Valve LSD Current Feedback Invalid";
BA_ "SignalType" SG_ 932 CustmModePwrtrnStrdPerfMode "ENM";
BA_ "SignalLongName" SG_ 932 CustmModePwrtrnStrdPerfMode "Custom Mode Powertrain Stored Performance Mode";
BA_ "SignalType" SG_ 932 PltfTrnsTUDSwSt "ENM";
BA_ "SignalLongName" SG_ 932 PltfTrnsTUDSwSt "Platform Transmission Tap Up/Down Information : Platform Transmission Tap Up/Down Switch State";
BA_ "SignalType" SG_ 932 PltfTrnsTUDSecSwSt "ENM";
BA_ "SignalLongName" SG_ 932 PltfTrnsTUDSecSwSt "Platform Transmission Tap Up/Down Information : Platform Transmission Tap Up/Down Secondary Switch State";
BA_ "SignalType" SG_ 932 LIBCfg "ENM";
BA_ "SignalLongName" SG_ 932 LIBCfg "Lithium Ion Battery Configuration";
BA_ "SignalLongName" SG_ 932 SD118_ARC "Serial Data 118 : Alive Rolling Count";
BA_ "SignalType" SG_ 932 ShftFrmPrkAlwd "ENM";
BA_ "SignalLongName" SG_ 932 ShftFrmPrkAlwd "Shift From Park Allowed";
BA_ "SignalType" SG_ 932 DrvrElecVehModeCmnd "ENM";
BA_ "SignalLongName" SG_ 932 DrvrElecVehModeCmnd "Driver Electric Vehicle Mode Commanded";
BA_ "SignalLongName" SG_ 932 PltfTrnsTUDSwStARC "Platform Transmission Tap Up/Down Information : Platform Transmission Tap Up/Down Switch State Alive Rolling Count";
BA_ "SignalType" SG_ 1426 DM1Unavailable "ENM";
BA_ "SignalLongName" SG_ 1426 DM1Unavailable "Drive Mode Information : Drive Mode 1 Unavailable";
BA_ "SignalType" SG_ 1426 DM1Status "ENM";
BA_ "SignalLongName" SG_ 1426 DM1Status "Drive Mode Information : Drive Mode 1 Status";
BA_ "SignalType" SG_ 1426 DM1Pending "ENM";
BA_ "SignalLongName" SG_ 1426 DM1Pending "Drive Mode Information : Drive Mode 1 Pending";
BA_ "SignalType" SG_ 1426 DM1Name "ENM";
BA_ "SignalLongName" SG_ 1426 DM1Name "Drive Mode Information : Drive Mode 1 Name";
BA_ "SignalType" SG_ 1426 DM2Unavailable "ENM";
BA_ "SignalLongName" SG_ 1426 DM2Unavailable "Drive Mode Information : Drive Mode 2 Unavailable";
BA_ "SignalType" SG_ 1426 DM2Status "ENM";
BA_ "SignalLongName" SG_ 1426 DM2Status "Drive Mode Information : Drive Mode 2 Status";
BA_ "SignalType" SG_ 1426 DM2Pending "ENM";
BA_ "SignalLongName" SG_ 1426 DM2Pending "Drive Mode Information : Drive Mode 2 Pending";
BA_ "SignalType" SG_ 1426 DM2Name "ENM";
BA_ "SignalLongName" SG_ 1426 DM2Name "Drive Mode Information : Drive Mode 2 Name";
BA_ "SignalType" SG_ 1426 DM3Unavailable "ENM";
BA_ "SignalLongName" SG_ 1426 DM3Unavailable "Drive Mode Information : Drive Mode 3 Unavailable";
BA_ "SignalType" SG_ 1426 DM3Status "ENM";
BA_ "SignalLongName" SG_ 1426 DM3Status "Drive Mode Information : Drive Mode 3 Status";
BA_ "SignalType" SG_ 1426 DM3Pending "ENM";
BA_ "SignalLongName" SG_ 1426 DM3Pending "Drive Mode Information : Drive Mode 3 Pending";
BA_ "SignalType" SG_ 1426 DM3Name "ENM";
BA_ "SignalLongName" SG_ 1426 DM3Name "Drive Mode Information : Drive Mode 3 Name";
BA_ "SignalType" SG_ 1426 DM4Unavailable "ENM";
BA_ "SignalLongName" SG_ 1426 DM4Unavailable "Drive Mode Information : Drive Mode 4 Unavailable";
BA_ "SignalType" SG_ 1426 DM4Status "ENM";
BA_ "SignalLongName" SG_ 1426 DM4Status "Drive Mode Information : Drive Mode 4 Status";
BA_ "SignalType" SG_ 1426 DM4Pending "ENM";
BA_ "SignalLongName" SG_ 1426 DM4Pending "Drive Mode Information : Drive Mode 4 Pending";
BA_ "SignalType" SG_ 1426 DM4Name "ENM";
BA_ "SignalLongName" SG_ 1426 DM4Name "Drive Mode Information : Drive Mode 4 Name";
BA_ "SignalType" SG_ 1426 DM5Unavailable "ENM";
BA_ "SignalLongName" SG_ 1426 DM5Unavailable "Drive Mode Information : Drive Mode 5 Unavailable";
BA_ "SignalType" SG_ 1426 DM5Status "ENM";
BA_ "SignalLongName" SG_ 1426 DM5Status "Drive Mode Information : Drive Mode 5 Status";
BA_ "SignalType" SG_ 1426 DM5Pending "ENM";
BA_ "SignalLongName" SG_ 1426 DM5Pending "Drive Mode Information : Drive Mode 5 Pending";
BA_ "SignalType" SG_ 1426 DM5Name "ENM";
BA_ "SignalLongName" SG_ 1426 DM5Name "Drive Mode Information : Drive Mode 5 Name";
BA_ "SignalType" SG_ 1426 DM6Unavailable "ENM";
BA_ "SignalLongName" SG_ 1426 DM6Unavailable "Drive Mode Information : Drive Mode 6 Unavailable";
BA_ "SignalType" SG_ 1426 DM6Status "ENM";
BA_ "SignalLongName" SG_ 1426 DM6Status "Drive Mode Information : Drive Mode 6 Status";
BA_ "SignalType" SG_ 1426 DM6Pending "ENM";
BA_ "SignalLongName" SG_ 1426 DM6Pending "Drive Mode Information : Drive Mode 6 Pending";
BA_ "SignalType" SG_ 1426 DM6Name "ENM";
BA_ "SignalLongName" SG_ 1426 DM6Name "Drive Mode Information : Drive Mode 6 Name";
BA_ "SignalType" SG_ 1426 DM7Unavailable "ENM";
BA_ "SignalLongName" SG_ 1426 DM7Unavailable "Drive Mode Information : Drive Mode 7 Unavailable";
BA_ "SignalType" SG_ 1426 DM7Status "ENM";
BA_ "SignalLongName" SG_ 1426 DM7Status "Drive Mode Information : Drive Mode 7 Status";
BA_ "SignalType" SG_ 1426 DM7Pending "ENM";
BA_ "SignalLongName" SG_ 1426 DM7Pending "Drive Mode Information : Drive Mode 7 Pending";
BA_ "SignalType" SG_ 1426 DM7Name "ENM";
BA_ "SignalLongName" SG_ 1426 DM7Name "Drive Mode Information : Drive Mode 7 Name";
BA_ "SignalType" SG_ 1426 DM8Unavailable "ENM";
BA_ "SignalLongName" SG_ 1426 DM8Unavailable "Drive Mode Information : Drive Mode 8 Unavailable";
BA_ "SignalType" SG_ 1426 DM8Status "ENM";
BA_ "SignalLongName" SG_ 1426 DM8Status "Drive Mode Information : Drive Mode 8 Status";
BA_ "SignalType" SG_ 1426 DM8Pending "ENM";
BA_ "SignalLongName" SG_ 1426 DM8Pending "Drive Mode Information : Drive Mode 8 Pending";
BA_ "SignalType" SG_ 1426 DM8Name "ENM";
BA_ "SignalLongName" SG_ 1426 DM8Name "Drive Mode Information : Drive Mode 8 Name";
BA_ "SignalLongName" SG_ 1411 BatVlt "Battery Voltage";
BA_ "SignalLongName" SG_ 1411 BattCrntFltrd "Battery Current Filtered";
BA_ "SignalType" SG_ 1411 BatVlt_Inv "ENM";
BA_ "SignalLongName" SG_ 1411 BatVlt_Inv "RVC 12V Battery Voltage Invalid";
BA_ "SignalLongName" SG_ 1411 RVC12VBatSOC "RVC 12V Battery State of Charge";
BA_ "SignalType" SG_ 1411 BattCrntFltrd_Inv "ENM";
BA_ "SignalLongName" SG_ 1411 BattCrntFltrd_Inv "Battery Current Filtered Invalid";
BA_ "SignalType" SG_ 1411 BattCrntFltrd_DuD "ENM";
BA_ "SignalLongName" SG_ 1411 BattCrntFltrd_DuD "Battery Current Filtered Don't Use Data";
BA_ "SignalType" SG_ 2147745822 Sig4411 "ENM";
BA_ "SignalLongName" SG_ 2147745822 Sig4411 "Signal4603";
BA_ "SignalType" SG_ 963 NodeStsADIMb_CAN_9_LcFA "ENM";
BA_ "SignalLongName" SG_ 963 NodeStsADIMb_CAN_9_LcFA "Node Status ADIMb_CAN_9 Loss of Communication Fault Active";
BA_ "SignalType" SG_ 963 NodeStsADIMb_CAN_3_LcFA "ENM";
BA_ "SignalLongName" SG_ 963 NodeStsADIMb_CAN_3_LcFA "Node Status ADIMb_CAN_3 Loss of Communication Fault Active";
BA_ "SignalType" SG_ 963 NodeStsADIMb_CAN_2_LcFA "ENM";
BA_ "SignalLongName" SG_ 963 NodeStsADIMb_CAN_2_LcFA "Node Status ADIMb_CAN_2 Loss of Communication Fault Active";
BA_ "SignalType" SG_ 963 NodeStsADIMb_CAN_10_LcFA "ENM";
BA_ "SignalLongName" SG_ 963 NodeStsADIMb_CAN_10_LcFA "Node Status ADIMb_CAN_10 Loss of Communication Fault Active";
BA_ "SignalType" SG_ 963 NodeStsADIMa_CAN_9_LcFA "ENM";
BA_ "SignalLongName" SG_ 963 NodeStsADIMa_CAN_9_LcFA "Node Status ADIMa_CAN_9 Loss of Communication Fault Active";
BA_ "SignalType" SG_ 963 NodeStsADIMa_CAN_3_LcFA "ENM";
BA_ "SignalLongName" SG_ 963 NodeStsADIMa_CAN_3_LcFA "Node Status ADIMa CAN 3 Loss of Communication Fault Active";
BA_ "SignalType" SG_ 963 NodeStsADIMa_CAN_2_LcFA "ENM";
BA_ "SignalLongName" SG_ 963 NodeStsADIMa_CAN_2_LcFA "Node Status ADIMa_CAN_2 Loss of Communication Fault Active";
BA_ "SignalType" SG_ 963 NodeStsADIMa_CAN_10_LcFA "ENM";
BA_ "SignalLongName" SG_ 963 NodeStsADIMa_CAN_10_LcFA "Node Status ADIMa_CAN_10 Loss of Communication Fault Active";
BA_ "SignalType" SG_ 963 NodeStsAE44_CAN_1_LcFA "ENM";
BA_ "SignalLongName" SG_ 963 NodeStsAE44_CAN_1_LcFA "Node Status AE44_CAN_1 Loss of Communication Fault Active";
BA_ "SignalType" SG_ 963 NodeStsE5_LcFA "ENM";
BA_ "SignalLongName" SG_ 963 NodeStsE5_LcFA "Node Status E5 Loss of Communication Fault Active";
BA_ "SignalType" SG_ 963 NodeStsAMP_LcFA "ENM";
BA_ "SignalLongName" SG_ 963 NodeStsAMP_LcFA "Node Status AMP Loss of Communication Fault Active";
BA_ "SignalType" SG_ 963 NodeStsALC_LcFA "ENM";
BA_ "SignalLongName" SG_ 963 NodeStsALC_LcFA "Node Status ALC Loss of Communication Fault Active";
BA_ "SignalType" SG_ 963 NodeStsAHS_LcFA "ENM";
BA_ "SignalLongName" SG_ 963 NodeStsAHS_LcFA "Node Status AHS Loss of Communication Fault Active";
BA_ "SignalType" SG_ 963 NodeStsAHL_AFL_CAN_2_LcFA "ENM";
BA_ "SignalLongName" SG_ 963 NodeStsAHL_AFL_CAN_2_LcFA "Node Status AHL_AFL CAN 2 Loss of Communication Fault Active";
BA_ "SignalType" SG_ 963 NodeStsAGC_LcFA "ENM";
BA_ "SignalLongName" SG_ 963 NodeStsAGC_LcFA "Node Status AGC Loss of Communication Fault Active";
BA_ "SignalType" SG_ 963 NodeStsBSM_MH_LcFA "ENM";
BA_ "SignalLongName" SG_ 963 NodeStsBSM_MH_LcFA "Node Status BSM_MH Loss of Communication Fault Active";
BA_ "SignalType" SG_ 963 NodeStsBSM_CAN_3_LcFA "ENM";
BA_ "SignalLongName" SG_ 963 NodeStsBSM_CAN_3_LcFA "Node Status BSM_CAN_3 Loss of Communication Fault Active";
BA_ "SignalType" SG_ 963 NodeStsBSM_CAN_2_LcFA "ENM";
BA_ "SignalLongName" SG_ 963 NodeStsBSM_CAN_2_LcFA "Node Status BSM_CAN_2 Loss of Communication Fault Active";
BA_ "SignalType" SG_ 963 NodeStsBCM_LcFA "ENM";
BA_ "SignalLongName" SG_ 963 NodeStsBCM_LcFA "Node Status BCM Loss of Communication Fault Active";
BA_ "SignalType" SG_ 963 NodeStsARS_LcFA "ENM";
BA_ "SignalLongName" SG_ 963 NodeStsARS_LcFA "Node Status ARS Loss of Communication Fault Active";
BA_ "SignalType" SG_ 963 NodeStsE8_LcFA "ENM";
BA_ "SignalLongName" SG_ 963 NodeStsE8_LcFA "Node Status E8 Loss of Communication Fault Active";
BA_ "SignalType" SG_ 963 NodeStsAE44_CAN_2_LcFA "ENM";
BA_ "SignalLongName" SG_ 963 NodeStsAE44_CAN_2_LcFA "Node Status AE44_CAN_2 Loss of Communication Fault Active";
BA_ "SignalType" SG_ 963 NodeStsEBCM_AV_CAN_2_LcFA "ENM";
BA_ "SignalLongName" SG_ 963 NodeStsEBCM_AV_CAN_2_LcFA "Node Status EBCM AV CAN 2 Loss of Communication Fault Active";
BA_ "SignalType" SG_ 963 NodeStsDMS_LcFA "ENM";
BA_ "SignalLongName" SG_ 963 NodeStsDMS_LcFA "Node Status DMS Loss of Communication Fault Active";
BA_ "SignalType" SG_ 963 NodeStsE12_LcFA "ENM";
BA_ "SignalLongName" SG_ 963 NodeStsE12_LcFA "Node Status E12 Loss of Communication Fault Active";
BA_ "SignalType" SG_ 963 NodeStsDCM_LcFA "ENM";
BA_ "SignalLongName" SG_ 963 NodeStsDCM_LcFA "Node Status DCM Loss of Communication Fault Active";
BA_ "SignalType" SG_ 963 NodeStsCSM_CAN_5_LcFA "ENM";
BA_ "SignalLongName" SG_ 963 NodeStsCSM_CAN_5_LcFA "Node Status CSM_CAN_5 Loss of Communication Fault Active";
BA_ "SignalType" SG_ 963 NodeStsECP_E_CAN_9_LcFA "ENM";
BA_ "SignalLongName" SG_ 963 NodeStsECP_E_CAN_9_LcFA "Node Status ECP_E CAN 9 Loss of Communication Fault Active";
BA_ "SignalType" SG_ 963 NodeStsECP_E_CAN_2_LcFA "ENM";
BA_ "SignalLongName" SG_ 963 NodeStsECP_E_CAN_2_LcFA "Node Status ECP_E_CAN_2 Loss of Communication Fault Active";
BA_ "SignalType" SG_ 963 NodeStsECM_CAN_3_LcFA "ENM";
BA_ "SignalLongName" SG_ 963 NodeStsECM_CAN_3_LcFA "Node Status ECM_CAN_3 Loss of Communication Fault Active";
BA_ "SignalType" SG_ 963 NodeStsECM_CAN_2_LcFA "ENM";
BA_ "SignalLongName" SG_ 963 NodeStsECM_CAN_2_LcFA "Node Status ECM_CAN_2 Loss of Communication Fault Active";
BA_ "SignalType" SG_ 963 NodeStsEBCM_CAN_3_LcFA "ENM";
BA_ "SignalLongName" SG_ 963 NodeStsEBCM_CAN_3_LcFA "Node Status EBCM CAN 3 Loss of Communication Fault Active";
BA_ "SignalType" SG_ 963 NodeStsEBCM_CAN_2_LcFA "ENM";
BA_ "SignalLongName" SG_ 963 NodeStsEBCM_CAN_2_LcFA "Node Status EBCM_CAN_2 Loss of Communication Fault Active";
BA_ "SignalType" SG_ 963 NodeStsEBCM_AV_CAN_3_LcFA "ENM";
BA_ "SignalLongName" SG_ 963 NodeStsEBCM_AV_CAN_3_LcFA "Node Status EBCM_AV CAN 3 Loss of Communication Fault Active";
BA_ "SignalType" SG_ 963 NodeStsEOCM_CAN_3_LcFA "ENM";
BA_ "SignalLongName" SG_ 963 NodeStsEOCM_CAN_3_LcFA "Node Status EOCM CAN 3 Loss of Communication Fault Active";
BA_ "SignalType" SG_ 963 NodeStsEOCM_CAN_2_LcFA "ENM";
BA_ "SignalLongName" SG_ 963 NodeStsEOCM_CAN_2_LcFA "Node Status EOCM_CAN_2 Loss of Communication Fault Active";
BA_ "SignalType" SG_ 963 NodeStsELM_LcFA "ENM";
BA_ "SignalLongName" SG_ 963 NodeStsELM_LcFA "Node Status ELM Loss of Communication Fault Active";
BA_ "SignalType" SG_ 963 NodeStsECP_X1_CAN_3_LcFA "ENM";
BA_ "SignalLongName" SG_ 963 NodeStsECP_X1_CAN_3_LcFA "Node Status ECP_X1_CAN_3 Loss of Communication Fault Active";
BA_ "SignalType" SG_ 963 NodeStsECP_X1_CAN_2_LcFA "ENM";
BA_ "SignalLongName" SG_ 963 NodeStsECP_X1_CAN_2_LcFA "Node Status ECP_X1_CAN_2 Loss of Communication Fault Active";
BA_ "SignalType" SG_ 963 NodeStsECP_S_CAN_9_LcFA "ENM";
BA_ "SignalLongName" SG_ 963 NodeStsECP_S_CAN_9_LcFA "Node Status ECP_S_CAN_9 Loss of Communication Fault Active";
BA_ "SignalType" SG_ 963 NodeStsECP_S_CAN_2_LcFA "ENM";
BA_ "SignalLongName" SG_ 963 NodeStsECP_S_CAN_2_LcFA "Node Status ECP_S CAN 2 Loss of Communication Fault Active";
BA_ "SignalType" SG_ 963 NodeStsECP_MC_LcFA "ENM";
BA_ "SignalLongName" SG_ 963 NodeStsECP_MC_LcFA "Node Status ECP_MC Loss of Communication Fault Active";
BA_ "SignalType" SG_ 963 NodeStsEPSRAa_LcFA "ENM";
BA_ "SignalLongName" SG_ 963 NodeStsEPSRAa_LcFA "Node Status EPSRAa Loss of Communication Fault Active";
BA_ "SignalType" SG_ 963 NodeStsEPS_LcFA "ENM";
BA_ "SignalLongName" SG_ 963 NodeStsEPS_LcFA "Node Status EPS Loss of Communication Fault Active";
BA_ "SignalType" SG_ 963 NodeStsE19_LcFA "ENM";
BA_ "SignalLongName" SG_ 963 NodeStsE19_LcFA "Node Status E19 Loss of Communication Fault Active";
BA_ "SignalType" SG_ 963 NodeStsEOCM_HCP2_LcFA "ENM";
BA_ "SignalLongName" SG_ 963 NodeStsEOCM_HCP2_LcFA "Node Status EOCM_HCP2 Loss of Communication Fault Active";
BA_ "SignalType" SG_ 963 NodeStsEOCM_HCP1_CAN_8_LcFA "ENM";
BA_ "SignalLongName" SG_ 963 NodeStsEOCM_HCP1_CAN_8_LcFA "Node Status EOCM_HCP1_CAN_8 Loss of Communication Fault Active";
BA_ "SignalType" SG_ 963 NodeStsEOCM_HCP1_CAN_3_LcFA "ENM";
BA_ "SignalLongName" SG_ 963 NodeStsEOCM_HCP1_CAN_3_LcFA "Node Status EOCM_HCP1 CAN 3 Loss of Communication Fault Active";
BA_ "SignalType" SG_ 963 NodeStsEOCM_HCP1_CAN_2_LcFA "ENM";
BA_ "SignalLongName" SG_ 963 NodeStsEOCM_HCP1_CAN_2_LcFA "Node Status EOCM_HCP1_CAN_2 Loss of Communication Fault Active";
BA_ "SignalType" SG_ 963 NodeStsEOCM_CAN_8_LcFA "ENM";
BA_ "SignalLongName" SG_ 963 NodeStsEOCM_CAN_8_LcFA "Node Status EOCM_CAN_8 Loss of Communication Fault Active";
BA_ "SignalType" SG_ 963 NodeStsHVAC_FP_F_LcFA "ENM";
BA_ "SignalLongName" SG_ 963 NodeStsHVAC_FP_F_LcFA "Node Status HVAC_FP_F Loss of Communication Fault Active";
BA_ "SignalType" SG_ 963 NodeStsHUD_CAN_LcFA "ENM";
BA_ "SignalLongName" SG_ 963 NodeStsHUD_CAN_LcFA "Node Status HUD_CAN Loss of Communication Fault Active";
BA_ "SignalType" SG_ 963 NodeStsE22_LcFA "ENM";
BA_ "SignalLongName" SG_ 963 NodeStsE22_LcFA "Node Status E22 Loss of Communication Fault Active";
BA_ "SignalType" SG_ 963 NodeStsFOPM_CAN_3_LcFA "ENM";
BA_ "SignalLongName" SG_ 963 NodeStsFOPM_CAN_3_LcFA "Node Status FOPM CAN 3 Loss of Communication Fault Active";
BA_ "SignalType" SG_ 963 NodeStsFOPM_CAN_2_LcFA "ENM";
BA_ "SignalLongName" SG_ 963 NodeStsFOPM_CAN_2_LcFA "Node Status FOPM_CAN_2 Loss of Communication Fault Active";
BA_ "SignalType" SG_ 963 NodeStsFCM_LcFA "ENM";
BA_ "SignalLongName" SG_ 963 NodeStsFCM_LcFA "Node Status FCM Loss of Communication Fault Active";
BA_ "SignalType" SG_ 963 NodeStsFCM_LC_LcFA "ENM";
BA_ "SignalLongName" SG_ 963 NodeStsFCM_LC_LcFA "Node Status FCM LC Loss of Communication Fault Active";
BA_ "SignalType" SG_ 963 NodeStsE20_LcFA "ENM";
BA_ "SignalLongName" SG_ 963 NodeStsE20_LcFA "Node Status E20 Loss of Communication Fault Active";
BA_ "SignalType" SG_ 964 NodeStsMFC_LcFA "ENM";
BA_ "SignalLongName" SG_ 964 NodeStsMFC_LcFA "Node Status MFC Loss of Communication Fault Active";
BA_ "SignalType" SG_ 964 NodeStsLRR_LcFA "ENM";
BA_ "SignalLongName" SG_ 964 NodeStsLRR_LcFA "Node Status LRR Loss of Communication Fault Active";
BA_ "SignalType" SG_ 964 NodeStsLIB1_LcFA "ENM";
BA_ "SignalLongName" SG_ 964 NodeStsLIB1_LcFA "Node Status LIB1 Loss of Communication Fault Active";
BA_ "SignalType" SG_ 964 NodeStsIPC_CAN_5_LcFA "ENM";
BA_ "SignalLongName" SG_ 964 NodeStsIPC_CAN_5_LcFA "Node Status IPC CAN 5 Loss of Communication Fault Active";
BA_ "SignalType" SG_ 964 NodeStsICS_Info_LcFA "ENM";
BA_ "SignalLongName" SG_ 964 NodeStsICS_Info_LcFA "Node Status ICS_Info Loss of Communication Fault Active";
BA_ "SignalType" SG_ 964 NodeStsICCM_CAN_3_LcFA "ENM";
BA_ "SignalLongName" SG_ 964 NodeStsICCM_CAN_3_LcFA "Node Status ICCM CAN 3 Loss of Communication Fault Active";
BA_ "SignalType" SG_ 964 NodeStsHVAC_FP_R_LcFA "ENM";
BA_ "SignalLongName" SG_ 964 NodeStsHVAC_FP_R_LcFA "Node Status HVAC_FP_R Loss of Communication Fault Active";
BA_ "SignalType" SG_ 964 NodeStsE38_LcFA "ENM";
BA_ "SignalLongName" SG_ 964 NodeStsE38_LcFA "Node Status E38 Loss of Communication Fault Active";
BA_ "SignalType" SG_ 964 NodeStsE37_LcFA "ENM";
BA_ "SignalLongName" SG_ 964 NodeStsE37_LcFA "Node Status E37 Loss of Communication Fault Active";
BA_ "SignalType" SG_ 964 NodeStsE36_LcFA "ENM";
BA_ "SignalLongName" SG_ 964 NodeStsE36_LcFA "Node Status E36 Loss of Communication Fault Active";
BA_ "SignalType" SG_ 964 NodeStsE35_LcFA "ENM";
BA_ "SignalLongName" SG_ 964 NodeStsE35_LcFA "Node Status E35 Loss of Communication Fault Active";
BA_ "SignalType" SG_ 964 NodeStsE34_LcFA "ENM";
BA_ "SignalLongName" SG_ 964 NodeStsE34_LcFA "Node Status E34 Loss of Communication Fault Active";
BA_ "SignalType" SG_ 964 NodeStsE33_LcFA "ENM";
BA_ "SignalLongName" SG_ 964 NodeStsE33_LcFA "Node Status E33 Loss of Communication Fault Active";
BA_ "SignalType" SG_ 964 NodeStsE32_LcFA "ENM";
BA_ "SignalLongName" SG_ 964 NodeStsE32_LcFA "Node Status E32 Loss of Communication Fault Active";
BA_ "SignalType" SG_ 964 NodeStsE31_LcFA "ENM";
BA_ "SignalLongName" SG_ 964 NodeStsE31_LcFA "Node Status E31 Loss of Communication Fault Active";
BA_ "SignalType" SG_ 964 NodeStsRDCM_LcFA "ENM";
BA_ "SignalLongName" SG_ 964 NodeStsRDCM_LcFA "Node Status RDCM Loss of Communication Fault Active";
BA_ "SignalType" SG_ 964 NodeStsRadioLow_LcFA "ENM";
BA_ "SignalLongName" SG_ 964 NodeStsRadioLow_LcFA "Node Status RadioLow Loss of Communication Fault Active";
BA_ "SignalType" SG_ 964 NodeStsE48_LcFA "ENM";
BA_ "SignalLongName" SG_ 964 NodeStsE48_LcFA "Node Status E48 Loss of Communication Fault Active";
BA_ "SignalType" SG_ 964 NodeStsPDR_LcFA "ENM";
BA_ "SignalLongName" SG_ 964 NodeStsPDR_LcFA "Node Status PDR Loss of Communication Fault Active";
BA_ "SignalType" SG_ 964 NodeStsE44_LcFA "ENM";
BA_ "SignalLongName" SG_ 964 NodeStsE44_LcFA "Node Status E44 Loss of Communication Fault Active";
BA_ "SignalType" SG_ 964 NodeStsNVM_LcFA "ENM";
BA_ "SignalLongName" SG_ 964 NodeStsNVM_LcFA "Node Status NVM Loss of Communication Fault Active";
BA_ "SignalType" SG_ 964 NodeStsE40_LcFA "ENM";
BA_ "SignalLongName" SG_ 964 NodeStsE40_LcFA "Node Status E40 Loss of Communication Fault Active";
BA_ "SignalType" SG_ 964 NodeStsE39_LcFA "ENM";
BA_ "SignalLongName" SG_ 964 NodeStsE39_LcFA "Node Status E39 Loss of Communication Fault Active";
BA_ "SignalType" SG_ 964 Sig4413 "ENM";
BA_ "SignalLongName" SG_ 964 Sig4413 "Signal4616";
BA_ "SignalType" SG_ 964 NodeStsE53_LcFA "ENM";
BA_ "SignalLongName" SG_ 964 NodeStsE53_LcFA "Node Status SAM RR Loss of Communication Fault Active";
BA_ "SignalType" SG_ 964 NodeStsE52_LcFA "ENM";
BA_ "SignalLongName" SG_ 964 NodeStsE52_LcFA "Node Status SAM RF Loss of Communication Fault Active";
BA_ "SignalType" SG_ 964 NodeStsE51_LcFA "ENM";
BA_ "SignalLongName" SG_ 964 NodeStsE51_LcFA "Node Status SAM LR Loss of Communication Fault Active";
BA_ "SignalType" SG_ 964 NodeStsE50_LcFA "ENM";
BA_ "SignalLongName" SG_ 964 NodeStsE50_LcFA "Node Status SAM LF Loss of Communication Fault Active";
BA_ "SignalType" SG_ 964 NodeStsSADS_LcFA "ENM";
BA_ "SignalLongName" SG_ 964 NodeStsSADS_LcFA "Node Status SADS Loss of Communication Fault Active";
BA_ "SignalType" SG_ 964 NodeStsRSC_LcFA "ENM";
BA_ "SignalLongName" SG_ 964 NodeStsRSC_LcFA "Node Status RSC Loss of Communication Fault Active";
BA_ "SignalType" SG_ 964 NodeStsSRR_RF_LcFA "ENM";
BA_ "SignalLongName" SG_ 964 NodeStsSRR_RF_LcFA "Node Status SRR_RF Loss of Communication Fault Active";
BA_ "SignalType" SG_ 964 NodeStsSRR_LR_CR_LcFA "ENM";
BA_ "SignalLongName" SG_ 964 NodeStsSRR_LR_CR_LcFA "Node Status SRR_LR_CR Loss of Communication Fault Active";
BA_ "SignalType" SG_ 964 NodeStsSRR_LF_LcFA "ENM";
BA_ "SignalLongName" SG_ 964 NodeStsSRR_LF_LcFA "Node Status SRR_LF Loss of Communication Fault Active";
BA_ "SignalType" SG_ 964 NodeStsSIB_LcFA "ENM";
BA_ "SignalLongName" SG_ 964 NodeStsSIB_LcFA "Node Status SIB Loss of Communication Fault Active";
BA_ "SignalType" SG_ 964 NodeStsSDM_LcFA "ENM";
BA_ "SignalLongName" SG_ 964 NodeStsSDM_LcFA "Node Status SDM Loss of Communication Fault Active";
BA_ "SignalType" SG_ 964 NodeStsE56_LcFA "ENM";
BA_ "SignalLongName" SG_ 964 NodeStsE56_LcFA "Node Status E56 Loss of Communication Fault Active";
BA_ "SignalType" SG_ 964 NodeStsE55_LcFA "ENM";
BA_ "SignalLongName" SG_ 964 NodeStsE55_LcFA "Node Status E55 Loss of Communication Fault Active";
BA_ "SignalType" SG_ 964 NodeStsE54_LcFA "ENM";
BA_ "SignalLongName" SG_ 964 NodeStsE54_LcFA "Node Status E54 Loss of Communication Fault Active";
BA_ "SignalType" SG_ 964 NodeStsTCP_CAN_5_LcFA "ENM";
BA_ "SignalLongName" SG_ 964 NodeStsTCP_CAN_5_LcFA "Node Status TCP_CAN_5 Loss of Communication Fault Active";
BA_ "SignalType" SG_ 964 NodeStsTCM_CAN_2_LcFA "ENM";
BA_ "SignalLongName" SG_ 964 NodeStsTCM_CAN_2_LcFA "Node Status TCM_CAN_2 Loss of Communication Fault Active";
BA_ "SignalType" SG_ 964 NodeStsTCCM_LcFA "ENM";
BA_ "SignalLongName" SG_ 964 NodeStsTCCM_LcFA "Node Status TCCM Loss of Communication Fault Active";
BA_ "SignalType" SG_ 964 NodeStsE57_LcFA "ENM";
BA_ "SignalLongName" SG_ 964 NodeStsE57_LcFA "Node Status E57 Loss of Communication Fault Active";
BA_ "SignalType" SG_ 964 NodeStsSRR_SRR_LcFA "ENM";
BA_ "SignalLongName" SG_ 964 NodeStsSRR_SRR_LcFA "Node Status SRR_SRR Loss of Communication Fault Active";
BA_ "SignalType" SG_ 964 NodeStsSRR_SLR_LcFA "ENM";
BA_ "SignalLongName" SG_ 964 NodeStsSRR_SLR_LcFA "Node Status SRR_SLR Loss of Communication Fault Active";
BA_ "SignalType" SG_ 964 NodeStsSRR_RR_LcFA "ENM";
BA_ "SignalLongName" SG_ 964 NodeStsSRR_RR_LcFA "Node Status SRR_RR Loss of Communication Fault Active";
BA_ "SignalType" SG_ 964 NodeStsWCM_LcFA "ENM";
BA_ "SignalLongName" SG_ 964 NodeStsWCM_LcFA "Node Status WCM Loss of Communication Fault Active";
BA_ "SignalType" SG_ 964 NodeStsE63_LcFA "ENM";
BA_ "SignalLongName" SG_ 964 NodeStsE63_LcFA "Node Status E63 Loss of Communication Fault Active";
BA_ "SignalType" SG_ 964 NodeStsVLM_LcFA "ENM";
BA_ "SignalLongName" SG_ 964 NodeStsVLM_LcFA "Node Status VLM Loss of Communication Fault Active";
BA_ "SignalType" SG_ 964 NodeStsVKM_LcFA "ENM";
BA_ "SignalLongName" SG_ 964 NodeStsVKM_LcFA "Node StatusVKM Loss of Communication Fault Active";
BA_ "SignalType" SG_ 964 NodeStsVICM_CAN_9_LcFA "ENM";
BA_ "SignalLongName" SG_ 964 NodeStsVICM_CAN_9_LcFA "Node Status VICM_CAN_9 Loss of Communication Fault Active";
BA_ "SignalType" SG_ 964 NodeStsVICM_CAN_2_LcFA "ENM";
BA_ "SignalLongName" SG_ 964 NodeStsVICM_CAN_2_LcFA "Node Status VICM_CAN_2 Loss of Communication Fault Active";
BA_ "SignalType" SG_ 964 NodeStsVCU_CAN_5_LcFA "ENM";
BA_ "SignalLongName" SG_ 964 NodeStsVCU_CAN_5_LcFA "Node Status VCU_CAN_5 Loss of Communication Fault Active";
BA_ "SignalType" SG_ 964 NodeStsE60_LcFA "ENM";
BA_ "SignalLongName" SG_ 964 NodeStsE60_LcFA "Node Status E60 Loss of Communication Fault Active";
BA_ "SignalType" SG_ 964 NodeStsECP_S2_CAN_2_LcFA "ENM";
BA_ "SignalLongName" SG_ 964 NodeStsECP_S2_CAN_2_LcFA "Node Status ECP_S2_CAN_2 Loss of Communication Fault Active";
BA_ "SignalType" SG_ 964 NodeStsE45_LcFA "ENM";
BA_ "SignalLongName" SG_ 964 NodeStsE45_LcFA "Node Status E45 Loss of Communication Fault Active";
BA_ "SignalType" SG_ 964 NodeStsVDM_CAN_2_LcFA "ENM";
BA_ "SignalLongName" SG_ 964 NodeStsVDM_CAN_2_LcFA "Node Status VDM_CAN_2 Loss of Communication Fault Active";
BA_ "SignalType" SG_ 964 NodeStsWE48_LcFA "ENM";
BA_ "SignalLongName" SG_ 964 NodeStsWE48_LcFA "Node Status WE48 Loss of Communication Fault Active";
BA_ "SignalType" SG_ 964 NodeStsPCM_CAN_3_LcFA "ENM";
BA_ "SignalLongName" SG_ 964 NodeStsPCM_CAN_3_LcFA "Node Status PCM_CAN_3 Loss of Communication Fault Active";
BA_ "SignalType" SG_ 964 NodeStsPCM_CAN_2_LcFA "ENM";
BA_ "SignalLongName" SG_ 964 NodeStsPCM_CAN_2_LcFA "Node Status PCM_CAN_2 Loss of Communication Fault Active";
BA_ "SignalType" SG_ 964 NodeStsSDM_AV_LcFA "ENM";
BA_ "SignalLongName" SG_ 964 NodeStsSDM_AV_LcFA "Node Status SDM_AV Loss of Communication Fault Active";
BA_ "SignalType" SG_ 962 NodeStsACP2_MCU_CAN_8_LcFA "ENM";
BA_ "SignalLongName" SG_ 962 NodeStsACP2_MCU_CAN_8_LcFA "Node Status ACP2_MCU CAN_8 Loss of Communication Fault Active";
BA_ "SignalType" SG_ 962 NodeStsACP2_MCU_CAN_2_LcFA "ENM";
BA_ "SignalLongName" SG_ 962 NodeStsACP2_MCU_CAN_2_LcFA "Node Status ACP2_MCU CAN_2 Loss of Communication Fault Active";
BA_ "SignalType" SG_ 962 NodeStsVECM_CAN_2_LcFA "ENM";
BA_ "SignalLongName" SG_ 962 NodeStsVECM_CAN_2_LcFA "Node Status VECM_CAN_2 Loss of Communication Fault Active";
BA_ "SignalType" SG_ 962 NodeStsVDM_CAN_9_LcFA "ENM";
BA_ "SignalLongName" SG_ 962 NodeStsVDM_CAN_9_LcFA "Node Status VDM_CAN_9 Loss of Communication Fault Active";
BA_ "SignalType" SG_ 962 NodeStsE61_CAN_1_LcFA "ENM";
BA_ "SignalLongName" SG_ 962 NodeStsE61_CAN_1_LcFA "Node Status E61_CAN_1 Loss of Communication Fault Active";
BA_ "SignalType" SG_ 962 NodeStsUPM_LcFA "ENM";
BA_ "SignalLongName" SG_ 962 NodeStsUPM_LcFA "Node Status UPM Loss of Communication Fault Active";
BA_ "SignalType" SG_ 962 NodeStsEPSb_LcFA "ENM";
BA_ "SignalLongName" SG_ 962 NodeStsEPSb_LcFA "Node Status EPSb Loss of Communication Fault Active";
BA_ "SignalType" SG_ 962 NodeStsSBM_CAN_10_LcFA "ENM";
BA_ "SignalLongName" SG_ 962 NodeStsSBM_CAN_10_LcFA "Node Status SBM_CAN_10 Loss of Communication Fault Active";
BA_ "SignalType" SG_ 962 NodeStsVECM_CAN_9_LcFA "ENM";
BA_ "SignalLongName" SG_ 962 NodeStsVECM_CAN_9_LcFA "Node Status VECM_CAN_9 Loss of Communication Fault Active";
BA_ "SignalType" SG_ 962 NodeStsECP_S2_CAN_9_LcFA "ENM";
BA_ "SignalLongName" SG_ 962 NodeStsECP_S2_CAN_9_LcFA "Node Status ECP_S2_CAN_9 Loss of Communication Fault Active";
BA_ "SignalType" SG_ 962 NodeStsCSM_AV_CAN_5_LcFA "ENM";
BA_ "SignalLongName" SG_ 962 NodeStsCSM_AV_CAN_5_LcFA "Node Status CSM_AV_CAN_5 Loss of Communication Fault Active";
BA_ "SignalType" SG_ 962 NodeStsACP3_MCU_CAN_3_LcFA "ENM";
BA_ "SignalLongName" SG_ 962 NodeStsACP3_MCU_CAN_3_LcFA "Node Status ACP3_MCU CAN_3 Loss of Communication Fault Active";
BA_ "SignalType" SG_ 962 NodeStsACP3_MCU_CAN_8_LcFA "ENM";
BA_ "SignalLongName" SG_ 962 NodeStsACP3_MCU_CAN_8_LcFA "Node Status ACP3_MCU CAN_8 Loss of Communication Fault Active";
BA_ "SignalType" SG_ 962 NodeStsACP3_MCU_CAN_2_LcFA "ENM";
BA_ "SignalLongName" SG_ 962 NodeStsACP3_MCU_CAN_2_LcFA "Node Status ACP3_MCU CAN_2 Loss of Communication Fault Active";
BA_ "SignalLongName" SG_ 1382 OccptRstrntInfo_PCSM "Occupant Restraint Information Protected Counter Sync Message";
BA_ "SignalLongName" SG_ 1322 ORIP_MAC "Occupant Restraint Information Protected : MAC";
BA_ "SignalLongName" SG_ 1322 ORIP_FCnt "Occupant Restraint Information Protected : Freshness Counter";
BA_ "SignalType" SG_ 1322 FrtPsngrAirbagDsblVisIndCmd "ENM";
BA_ "SignalLongName" SG_ 1322 FrtPsngrAirbagDsblVisIndCmd "Occupant Restraint Information Protected : Front Passenger Airbag Disable Visual Indication Command";
BA_ "SignalLongName" SG_ 1322 ORIP_ARC "Occupant Restraint Information Protected : Alive Rolling Count";
BA_ "SignalType" SG_ 1322 ORIP_EnvModPrsntRsp1Auth "ENM";
BA_ "SignalLongName" SG_ 1322 ORIP_EnvModPrsntRsp1Auth "Occupant Restraint Information Protected : Environment Module Present - Responder #1 Authenticated";
BA_ "SignalType" SG_ 1322 ORIP_DrvrStBltStsAuth_Inv "ENM";
BA_ "SignalLongName" SG_ 1322 ORIP_DrvrStBltStsAuth_Inv "Occupant Restraint Information Protected : Driver Seat Belt Status Authenticated Invalid";
BA_ "SignalType" SG_ 1322 ORIP_DrvrStBltStsAuth "ENM";
BA_ "SignalLongName" SG_ 1322 ORIP_DrvrStBltStsAuth "Occupant Restraint Information Protected : Driver Seat Belt Status Authenticated";
BA_ "SignalLongName" SG_ 1322 ORIP_Filler "Occupant Restraint Information Protected : Filler";
BA_ "SignalType" SG_ 1322 RstrntSysFltPrsnt "ENM";
BA_ "SignalLongName" SG_ 1322 RstrntSysFltPrsnt "Occupant Restraint Information Protected : Restraint System Fault Present";
BA_ "SignalType" SG_ 1322 FrtPsngrAirbagEnblVisIndCmd "ENM";
BA_ "SignalLongName" SG_ 1322 FrtPsngrAirbagEnblVisIndCmd "Occupant Restraint Information Protected : Front Passenger Airbag Enable Visual Indication Command";
BA_ "SignalType" SG_ 2147745833 Sig4429 "ENM";
BA_ "SignalLongName" SG_ 2147745833 Sig4429 "Signal4619";
BA_ "SignalLongName" SG_ 713 PTImmblzerInfo "Challenge";
BA_ "SignalType" SG_ 1354 FE44RS_LtCntr "ENM";
BA_ "SignalLongName" SG_ 1354 FE44RS_LtCntr "Front Park Assist Region Status : Left Center Region";
BA_ "SignalType" SG_ 1354 FE44RS_Lt "ENM";
BA_ "SignalLongName" SG_ 1354 FE44RS_Lt "Front Park Assist Region Status : Left Region";
BA_ "SignalType" SG_ 1354 FE44RS_RtCntr "ENM";
BA_ "SignalLongName" SG_ 1354 FE44RS_RtCntr "Front Park Assist Region Status : Right Center Region";
BA_ "SignalType" SG_ 1354 FE44RS_Rt "ENM";
BA_ "SignalLongName" SG_ 1354 FE44RS_Rt "Front Park Assist Region Status : Right Region";
BA_ "SignalLongName" SG_ 1354 E44VehPathCrv "Park Assist HMI Information : Park Assist Vehicle Path Curvature";
BA_ "SignalType" SG_ 1354 E44IM_FaildIndOn "ENM";
BA_ "SignalLongName" SG_ 1354 E44IM_FaildIndOn "Park Assist Indication Messages : Failed Indication O";
BA_ "SignalType" SG_ 1354 E44IM_DsbldIndOn "ENM";
BA_ "SignalLongName" SG_ 1354 E44IM_DsbldIndOn "Park Assist Indication Messages : Disabled Indication On";
BA_ "SignalType" SG_ 1354 E44VisObjIndStatReq "ENM";
BA_ "SignalLongName" SG_ 1354 E44VisObjIndStatReq "Park Assist HMI Information : Park Assist Visual Object Indication State Request";
BA_ "SignalType" SG_ 1354 E44Rgn "ENM";
BA_ "SignalLongName" SG_ 1354 E44Rgn "Park Assist Region";
BA_ "SignalType" SG_ 1354 E44IM_TeenDrvrE44OffUnvIndOn "ENM";
BA_ "SignalLongName" SG_ 1354 E44IM_TeenDrvrE44OffUnvIndOn "Park Assist Indication Messages : Teen Driver Off Unavailable Indication On";
BA_ "SignalType" SG_ 1354 E44IM_SnsrDstbdIndOn "ENM";
BA_ "SignalLongName" SG_ 1354 E44IM_SnsrDstbdIndOn "Park Assist Indication Messages : Sensor Disturbed Indication On";
BA_ "SignalType" SG_ 1354 E44IM_SnsrClnIndOn "ENM";
BA_ "SignalLongName" SG_ 1354 E44IM_SnsrClnIndOn "Park Assist Indication Messages : Sensor Clean Indication On";
BA_ "SignalType" SG_ 1354 E44IM_SnsrBlckdIndOn "ENM";
BA_ "SignalLongName" SG_ 1354 E44IM_SnsrBlckdIndOn "Park Assist Indication Messages : Sensor Blocked Indication On";
BA_ "SignalType" SG_ 1354 E44IM_RrOffIndOn "ENM";
BA_ "SignalLongName" SG_ 1354 E44IM_RrOffIndOn "Park Assist Indication Messages : Rear Off Indication On";
BA_ "SignalType" SG_ 1354 E44IM_OffIndOn "ENM";
BA_ "SignalLongName" SG_ 1354 E44IM_OffIndOn "Park Assist Indication Messages : Off Indication On";
BA_ "SignalType" SG_ 1354 E44IM_FrtOffIndOn "ENM";
BA_ "SignalLongName" SG_ 1354 E44IM_FrtOffIndOn "Park Assist Indication Messages : Front Off Indication On";
BA_ "SignalType" SG_ 1354 PrkAsstActIndCmnd "ENM";
BA_ "SignalLongName" SG_ 1354 PrkAsstActIndCmnd "Park Assist Active Indication Command";
BA_ "SignalType" SG_ 1354 PrkAsstStat "ENM";
BA_ "SignalLongName" SG_ 1354 PrkAsstStat "Park Assist Status";
BA_ "SignalLongName" SG_ 913 PrplGenInfo3_PCSM "Propulsion General Information 3 Protected Counter Sync Message";
VAL_ 19 PrplSysWhlFlrCtlPriAxlRtActv 0 "FALSE" 1 "TRUE" ;
VAL_ 1026 PrkAsstFllFrZn2ChEvntSt 0 "NO_ACTION" 1 "ACTIVE" 2 "CANCEL_CHIME" ;
VAL_ 1026 PrkAsstFllFrZn1ChEvntSt 0 "NO_ACTION" 1 "ACTIVE" 2 "CANCEL_CHIME" ;
VAL_ 1026 PrkAsstFlChEvntSt 0 "NO_ACTION" 1 "ACTIVE" 2 "CANCEL_CHIME" ;
VAL_ 1026 E44MutSts 0 "No Action" 1 "Show Mute" 2 "Show Unmute" ;
VAL_ 1026 PrkAsstFllFrZn6ChEvntSt 0 "NO_ACTION" 1 "ACTIVE" 2 "CANCEL_CHIME" ;
VAL_ 1026 PrkAsstFllFrZn5ChEvntSt 0 "NO_ACTION" 1 "ACTIVE" 2 "CANCEL_CHIME" ;
VAL_ 1026 PrkAsstFllFrZn4ChEvntSt 0 "NO_ACTION" 1 "ACTIVE" 2 "CANCEL_CHIME" ;
VAL_ 1026 PrkAsstFllFrZn3ChEvntSt 0 "NO_ACTION" 1 "ACTIVE" 2 "CANCEL_CHIME" ;
VAL_ 1026 PrkAsstFllRrZn4ChEvntSt 0 "NO_ACTION" 1 "ACTIVE" 2 "CANCEL_CHIME" ;
VAL_ 1026 PrkAsstFllRrZn3ChEvntSt 0 "NO_ACTION" 1 "ACTIVE" 2 "CANCEL_CHIME" ;
VAL_ 1026 PrkAsstFllRrZn2ChEvntSt 0 "NO_ACTION" 1 "ACTIVE" 2 "CANCEL_CHIME" ;
VAL_ 1026 PrkAsstFllRrZn1ChEvntSt 0 "NO_ACTION" 1 "ACTIVE" 2 "CANCEL_CHIME" ;
VAL_ 1026 PrkAsstFrLftSdZn1ChEvntSt 0 "NO_ACTION" 1 "ACTIVE" 2 "CANCEL_CHIME" ;
VAL_ 1026 PrkAsstFrFrstRprtChEvntSt 0 "NO_ACTION" 1 "ACTIVE" 2 "CANCEL_CHIME" ;
VAL_ 1026 PrkAsstFllRrZn6ChEvntSt 0 "NO_ACTION" 1 "ACTIVE" 2 "CANCEL_CHIME" ;
VAL_ 1026 PrkAsstFllRrZn5ChEvntSt 0 "NO_ACTION" 1 "ACTIVE" 2 "CANCEL_CHIME" ;
VAL_ 1026 PrkAsstFrLftSdZn5ChEvntSt 0 "NO_ACTION" 1 "ACTIVE" 2 "CANCEL_CHIME" ;
VAL_ 1026 PrkAsstFrLftSdZn4ChEvntSt 0 "NO_ACTION" 1 "ACTIVE" 2 "CANCEL_CHIME" ;
VAL_ 1026 PrkAsstFrLftSdZn3ChEvntSt 0 "NO_ACTION" 1 "ACTIVE" 2 "CANCEL_CHIME" ;
VAL_ 1026 PrkAsstFrLftSdZn2ChEvntSt 0 "NO_ACTION" 1 "ACTIVE" 2 "CANCEL_CHIME" ;
VAL_ 1026 PrkAsstFrRghtSdZn3ChEvntSt 0 "NO_ACTION" 1 "ACTIVE" 2 "CANCEL_CHIME" ;
VAL_ 1026 PrkAsstFrRghtSdZn2ChEvntSt 0 "NO_ACTION" 1 "ACTIVE" 2 "CANCEL_CHIME" ;
VAL_ 1026 PrkAsstFrRghtSdZn1ChEvntSt 0 "NO_ACTION" 1 "ACTIVE" 2 "CANCEL_CHIME" ;
VAL_ 1026 PrkAsstFrLftSdZn6ChEvntSt 0 "NO_ACTION" 1 "ACTIVE" 2 "CANCEL_CHIME" ;
VAL_ 1026 PrkAsstFrRgrChEvntSt 0 "NO_ACTION" 1 "ACTIVE" 2 "CANCEL_CHIME" ;
VAL_ 1026 PrkAsstFrRghtSdZn6ChEvntSt 0 "NO_ACTION" 1 "ACTIVE" 2 "CANCEL_CHIME" ;
VAL_ 1026 PrkAsstFrRghtSdZn5ChEvntSt 0 "NO_ACTION" 1 "ACTIVE" 2 "CANCEL_CHIME" ;
VAL_ 1026 PrkAsstFrRghtSdZn4ChEvntSt 0 "NO_ACTION" 1 "ACTIVE" 2 "CANCEL_CHIME" ;
VAL_ 1026 PrkAsstRrLftSdZn3ChEvntSt 0 "NO_ACTION" 1 "ACTIVE" 2 "CANCEL_CHIME" ;
VAL_ 1026 PrkAsstRrLftSdZn2ChEvntSt 0 "NO_ACTION" 1 "ACTIVE" 2 "CANCEL_CHIME" ;
VAL_ 1026 PrkAsstRrLftSdZn1ChEvntSt 0 "NO_ACTION" 1 "ACTIVE" 2 "CANCEL_CHIME" ;
VAL_ 1026 PrkAsstRrFrstRprtChEvntSt 0 "NO_ACTION" 1 "ACTIVE" 2 "CANCEL_CHIME" ;
VAL_ 1026 PrkAsstRrRghtSdZn1ChEvntSt 0 "NO_ACTION" 1 "ACTIVE" 2 "CANCEL_CHIME" ;
VAL_ 1026 PrkAsstRrLftSdZn6ChEvntSt 0 "NO_ACTION" 1 "ACTIVE" 2 "CANCEL_CHIME" ;
VAL_ 1026 PrkAsstRrLftSdZn5ChEvntSt 0 "NO_ACTION" 1 "ACTIVE" 2 "CANCEL_CHIME" ;
VAL_ 1026 PrkAsstRrLftSdZn4ChEvntSt 0 "NO_ACTION" 1 "ACTIVE" 2 "CANCEL_CHIME" ;
VAL_ 1026 PrkAsstRrRghtSdZn5ChEvntSt 0 "NO_ACTION" 1 "ACTIVE" 2 "CANCEL_CHIME" ;
VAL_ 1026 PrkAsstRrRghtSdZn4ChEvntSt 0 "NO_ACTION" 1 "ACTIVE" 2 "CANCEL_CHIME" ;
VAL_ 1026 PrkAsstRrRghtSdZn3ChEvntSt 0 "NO_ACTION" 1 "ACTIVE" 2 "CANCEL_CHIME" ;
VAL_ 1026 PrkAsstRrRghtSdZn2ChEvntSt 0 "NO_ACTION" 1 "ACTIVE" 2 "CANCEL_CHIME" ;
VAL_ 1026 PrkAsstRrRgrChEvntSt 0 "NO_ACTION" 1 "ACTIVE" 2 "CANCEL_CHIME" ;
VAL_ 1026 PrkAsstRrRghtSdZn6ChEvntSt 0 "NO_ACTION" 1 "ACTIVE" 2 "CANCEL_CHIME" ;
VAL_ 1026 SuprRmtPrkWrnIndReq 0 "Off" 1 "Searching Parallel Right" 2 "Searching Parallel Left" 3 "Searching Cross Right" 4 "Searching Cross Left" 5 "Spot Found" 6 "Spot Found Parallel Left" 7 "Spot Found Cross Left" 8 "Spot Found Parallel Right" 9 "Spot Found Cross Right" 10 "Move Ahead" 11 "Move Ahead Parallel Left" 12 "Move Ahead Cross Left" 13 "Move Ahead Parallel Right" 14 "Move Ahead Cross Right" 15 "Stop And R Parallel Left" 16 "Stop And R Cross Back Left" 17 "Stop And R Cross Front Left" 18 "Stop And R Parallel Right" 19 "Stop And R Cross Back Right" 20 "Stop And R Cross Front Right" 21 "Search Speed Warning" 22 "Search Deactivated" 23 "Exit Park To Left" 24 "Exit Park To Right" 25 "Select Drive GEAR" 26 "Auto Steering Active" 27 "Auto Parking Active" 28 "Drive Backward" 29 "Backward Move" 30 "Drive Forward" 31 "Forward Move" 32 "Stop" 33 "Shifting" 34 "Position Reached" 35 "Take Control" 36 "ParkIng Complete" 37 "Exit Park Complete" 38 "Deactivated" 39 "Canceled General" 40 "Canceled Moves" 41 "Canceled Speed" 42 "Canceled Interference" 43 "Canceled Exit Park" 44 "Stopping" 45 "Auto Parking Complete" 46 "Release Brake" 47 "In Vehicle Or Remote" 48 "Remote Stay Alert" 49 "Remote Connecting" 50 "Remote Cannot Connect" 51 "Remote No Device" 52 "Remote Shift To Park" 53 "Remote Retry" 54 "Remote Canceled Range" 55 "Remote Canceled Supervision" 56 "Remote Canceled ConnectIon" 57 "Remote Paused Range" 58 "Remote Paused Supervision" 59 "Remote Paused ConnectIon" 60 "Search Drawer Exit" 61 "Search Drawer Park" 62 "Spot Selection Accept" 63 "Unable To Connect" 64 "Cancel Door" 65 "Pause Obstruction" 66 "Cancel Obstruction" 67 "No Exit Spot Found" 68 "Handshake Failure" 69 "Failed To Engage" 70 "Fasten Seatbelt" ;
VAL_ 1026 SuprRmtPrkDctvSftBtnReq 0 "Hidden" 1 "Disabled" 2 "Enabled" 3 "Highlighted" ;
VAL_ 1026 SuprRmtPrkFcsReq 0 "No Request" 1 "Focus Request IPC" 2 "Focus Request CSM" 3 "Focus Request VCU" ;
VAL_ 1026 SuprRmtPrkAutoStrgIconReq 0 "No Icon" 1 "Active" 2 "Deactivated" ;
VAL_ 1355 RE44RS_LtCntr 0 "OFF" 1 "FAILED" 2 "BLOCKED" 3 "ATTACHED_OBJECT" 4 "NO_OBJECT" 5 "ZONE_1" 6 "ZONE_2" 7 "ZONE_3" 8 "ZONE_4" 9 "ZONE_5" 10 "ZONE_6" 11 "OFF_NO_FAULT" 12 "RESERVED_1" 13 "RESERVED_2" 14 "RESERVED_3" ;
VAL_ 1355 RE44RS_Lt 0 "OFF" 1 "FAILED" 2 "BLOCKED" 3 "ATTACHED_OBJECT" 4 "NO_OBJECT" 5 "ZONE_1" 6 "ZONE_2" 7 "ZONE_3" 8 "ZONE_4" 9 "ZONE_5" 10 "ZONE_6" 11 "OFF_NO_FAULT" 12 "RESERVED_1" 13 "RESERVED_2" 14 "RESERVED_3" ;
VAL_ 1355 RE44RS_RtCntr 0 "OFF" 1 "FAILED" 2 "BLOCKED" 3 "ATTACHED_OBJECT" 4 "NO_OBJECT" 5 "ZONE_1" 6 "ZONE_2" 7 "ZONE_3" 8 "ZONE_4" 9 "ZONE_5" 10 "ZONE_6" 11 "OFF_NO_FAULT" 12 "RESERVED_1" 13 "RESERVED_2" 14 "RESERVED_3" ;
VAL_ 1355 RE44RS_Rt 0 "OFF" 1 "FAILED" 2 "BLOCKED" 3 "ATTACHED_OBJECT" 4 "NO_OBJECT" 5 "ZONE_1" 6 "ZONE_2" 7 "ZONE_3" 8 "ZONE_4" 9 "ZONE_5" 10 "ZONE_6" 11 "OFF_NO_FAULT" 12 "RESERVED_1" 13 "RESERVED_2" 14 "RESERVED_3" ;
VAL_ 1147 HVBCC_DyOfWk 0 "Unknown" 1 "Sunday" 2 "Monday" 3 "Tuesday" 4 "Wednesday" 5 "Thursday" 6 "Friday" 7 "Saturday" ;
VAL_ 1147 HVBCC_TmDispFormat 0 "No Action" 1 "Display Complete Time" 2 "Display Minutes to Complete" ;
VAL_ 1147 HVBCC_MinRmn_DuD 0 "FALSE" 1 "TRUE" ;
VAL_ 1147 HVBCC_TmDispPwrLvl 0 "Unknown" 1 "Level 1" 2 "Level 2" 3 "DC" 4 "Wireless" ;
VAL_ 669 Sig0101 0 "FALSE" 1 "TRUE" ;
VAL_ 1321 DMSDrwDrvrCstSetAval 0 "FALSE" 1 "TRUE" ;
VAL_ 1321 DMSDrwDrvrCstAvlFlg7 0 "FALSE" 1 "TRUE" ;
VAL_ 1321 DMSDrwDrvrCstAvlFlg6 0 "FALSE" 1 "TRUE" ;
VAL_ 1321 DMSDrwDrvrCstAvlFlg5 0 "FALSE" 1 "TRUE" ;
VAL_ 1321 DMSDrwDrvrCstAvlFlg4 0 "FALSE" 1 "TRUE" ;
VAL_ 1321 DMSDrwDrvrCstAvlFlg3 0 "FALSE" 1 "TRUE" ;
VAL_ 1321 DMSDrwDrvrCstAvlFlg2 0 "FALSE" 1 "TRUE" ;
VAL_ 1321 DMSDrwDrvrCstAvlFlg1 0 "FALSE" 1 "TRUE" ;
VAL_ 1321 DMSIntnDrvrCstSetAval 0 "FALSE" 1 "TRUE" ;
VAL_ 1321 DMSIntnDrvrCstAvlFlg7 0 "FALSE" 1 "TRUE" ;
VAL_ 1321 DMSIntnDrvrCstAvlFlg6 0 "FALSE" 1 "TRUE" ;
VAL_ 1321 DMSIntnDrvrCstAvlFlg5 0 "FALSE" 1 "TRUE" ;
VAL_ 1321 DMSIntnDrvrCstAvlFlg4 0 "FALSE" 1 "TRUE" ;
VAL_ 1321 DMSIntnDrvrCstAvlFlg3 0 "FALSE" 1 "TRUE" ;
VAL_ 1321 DMSIntnDrvrCstAvlFlg2 0 "FALSE" 1 "TRUE" ;
VAL_ 1321 DMSIntnDrvrCstAvlFlg1 0 "FALSE" 1 "TRUE" ;
VAL_ 1318 DMSDrwIntnDrvrDtnAlrtMutReqd 0 "FALSE" 1 "TRUE" ;
VAL_ 1318 DMSDrwIntnDrvrLvl1ChmEvntStat 0 "No Action" 1 "Active" 2 "Cancel Chime" ;
VAL_ 1318 DMSDrwIntnDrvrLvl2ChmEvntStat 0 "No Action" 1 "Active" 2 "Cancel Chime" ;
VAL_ 1304 DMSDrwDrvrCstCurrSetVal 0 "Setting Unknown" 1 "Off" 2 "Normal" 3 "Low Sensitivity" ;
VAL_ 1304 DMSDrwIntnDrvrWrnIndReq 0 "No Indication" 1 "Level 1" 2 "Level 2" 3 "Level 3" 4 "Level 4a" 5 "Level 4b" 6 "Level 4c" 7 "Inattentive Alert" 8 "Drowsy Off" 9 "Inattentive Off" 10 "Failed" 11 "Unavailable" ;
VAL_ 1304 DMSDrwDrvrIndReq 0 "Indicator Off" 1 "White Indicator" 2 "Green Indicator" 3 "Amber Indicator" 4 "Amber Flashing Indicator" 5 "Red Indicator" ;
VAL_ 1304 DMSDrwDrvrDispLvl 0 "No Indication" 1 "4 bars" 2 "3 bars" 3 "2 bars" 4 "1 bar" 5 "1 bar pulse" ;
VAL_ 1304 DMSIntnDrvrIndReq 0 "Indicator Off" 1 "White Indicator" 2 "Green Indicator" 3 "Amber Indicator" 4 "Amber Flashing Indicator" 5 "Red Indicator" ;
VAL_ 1304 DMSIntnDrvrDispLvl 0 "No Indication" 1 "4 bars" 2 "3 bars" 3 "2 bars" 4 "1 bar" 5 "1 bar pulse" ;
VAL_ 1304 DMSIntnDrvrCstCurrSetVal 0 "Setting Unknown" 1 "Off" 2 "On" ;
VAL_ 1304 DMSTnDrvrDrwIntnOffUnvIndOn 0 "FALSE" 1 "TRUE" ;
VAL_ 1304 DMSIntnDrvrDispFcsInd 0 "Unknown" 1 "Off Road" 2 "On Road" ;
VAL_ 1304 DMSDrwIntnDrvrDtnMtzdStBltPulRq 0 "No Action" 1 "Tug Profile 1" ;
VAL_ 1341 VehDynsTkDtctSts 0 "No Detection" 1 "Track1" 2 "Track2" ;
VAL_ 1239 PrkAsstTrHtchPsntCstAvlFlg1 0 "FALSE" 1 "TRUE" ;
VAL_ 1239 PrkAsstONOFFCstAvlFlg7 0 "FALSE" 1 "TRUE" ;
VAL_ 1239 PrkAsstONOFFCstAvlFlg6 0 "FALSE" 1 "TRUE" ;
VAL_ 1239 PrkAsstONOFFCstAvlFlg5 0 "FALSE" 1 "TRUE" ;
VAL_ 1239 PrkAsstONOFFCstAvlFlg4 0 "FALSE" 1 "TRUE" ;
VAL_ 1239 PrkAsstONOFFCstAvlFlg3 0 "FALSE" 1 "TRUE" ;
VAL_ 1239 PrkAsstONOFFCstAvlFlg2 0 "FALSE" 1 "TRUE" ;
VAL_ 1239 PrkAsstONOFFCstAvlFlg1 0 "FALSE" 1 "TRUE" ;
VAL_ 1239 PrkAsstTrHtchPsntCstAvlFlg7 0 "FALSE" 1 "TRUE" ;
VAL_ 1239 PrkAsstTrHtchPsntCstAvlFlg6 0 "FALSE" 1 "TRUE" ;
VAL_ 1239 PrkAsstTrHtchPsntCstAvlFlg5 0 "FALSE" 1 "TRUE" ;
VAL_ 1239 PrkAsstTrHtchPsntCstAvlFlg4 0 "FALSE" 1 "TRUE" ;
VAL_ 1239 PrkAsstTrHtchPsntCstAvlFlg3 0 "FALSE" 1 "TRUE" ;
VAL_ 1239 PrkAsstTrHtchPsntCstAvlFlg2 0 "FALSE" 1 "TRUE" ;
VAL_ 942 ALCGI_VehTopSpdLimReqTyp 0 "Inactive" 1 "Faulted" 2 "Safety_woBrake" 3 "Safety_wBrake" 4 "OBD" 5 "nonOBD" 6 "Legislated" ;
VAL_ 942 ALCGI_RideHghtESCEnblReqd 0 "FALSE" 1 "TRUE" ;
VAL_ 943 VLCGI_4CrnrLvlTopSpdLimReqTyp 0 "Inactive" 1 "Faulted" 2 "Safety_woBrake" 3 "Safety_wBrake" 4 "OBD" 5 "nonOBD" 6 "Legislated" ;
VAL_ 943 VLCGI_4CrnrLvlESCEnblReqd 0 "FALSE" 1 "TRUE" ;
VAL_ 1346 RrwdImpMtgnAval 0 "FALSE" 1 "TRUE" ;
VAL_ 1251 SBMERDTC_SysDes 0 "P0_Powertrain Codes SAE Controlled" 1 "P1_Powertrain Codes MFG Controlled" 2 "P2_Powertrain Codes Reserved" 3 "P3_Powertrain Codes Reserved" 4 "C0_Chassis Codes SAE Controlled" 5 "C1_Chassis Codes MFG Controlled" 6 "C2_Chassis Codes Reserved" 7 "C3_Chassis Codes Reserved" 8 "B0_Body Codes SAE Controlled" 9 "B1_Body Codes MFG Controlled" 10 "B2_Body Codes Reserved" 11 "B3_Body Codes Reserved" 12 "U0_Network Codes SAE Controlled" 13 "U1_Network Codes MFG Controlled" 14 "U2_Network Codes Reserved" 15 "U3_Network Codes Reserved" ;
VAL_ 1251 PIMRI_SBM_PrmntDTCInd 0 "FALSE" 1 "TRUE" ;
VAL_ 1251 PIMRI_SBM_FltsPrsntInd 0 "FALSE" 1 "TRUE" ;
VAL_ 1251 SBMEmsRltMlfAtv 0 "FALSE" 1 "TRUE" ;
VAL_ 1429 RrClsrAjrStat 0 "FALSE" 1 "TRUE" ;
VAL_ 1429 RrClsrAjrStat_Inv 0 "FALSE" 1 "TRUE" ;
VAL_ 1810 CldrMth 0 "Unknown" 1 "January" 2 "February" 3 "March" 4 "April" 5 "May" 6 "June" 7 "July" 8 "August" 9 "September" 10 "October" 11 "November" 12 "December" ;
VAL_ 1443 TODCSR_ChrgSchedDyOfWkReq 0 "No Action" 1 "Sunday" 2 "Monday" 3 "Tuesday" 4 "Wednesday" 5 "Thursday" 6 "Friday" 7 "Saturday" 8 "All Days Same" 9 "Monday to Friday Same" 10 "Saturday and Sunday Same" ;
VAL_ 1443 TODCSR_ChrgSchedCstSetReq 0 "No Action" 1 "Off" 2 "On" ;
VAL_ 1443 TODCSR_ERSPrdDyReq 0 "No Action" 1 "Weekday 1" 2 "Weekday 2" 3 "Weekday 3" 4 "Weekday 4" 5 "Weekday 5" 6 "Weekend 1" 7 "Weekend 2" 8 "Weekend 3" 9 "Weekend 4" 10 "Weekend 5" ;
VAL_ 1443 TODCSR_ERSCstSetReq 0 "No Action" 1 "Off" 2 "On" ;
VAL_ 1443 TODCSR_ERSPrdLvlReq 0 "No Action" 1 "Low Rate" 2 "Medium Rate" 3 "High Rate" 4 "Reserved 1" 5 "Invalid Rate" ;
VAL_ 1443 PrtblChrgCordLimCstSetReq 0 "No Action" 1 "Reduced" 2 "Maximum" ;
VAL_ 1443 TODCSR_ERSPrfReq 0 "No Action" 1 "Low Rate" 2 "Medium Rate" 3 "High Rate" ;
VAL_ 1443 TODCCbnPrcndtngSetReq 0 "No Action" 1 "Off" 2 "On" ;
VAL_ 1443 TODCSR_LocNumReq 0 "No Action" 1 "Not in Stored Location" 2 "Stored Location 1" 3 "Stored Location 2" 4 "Stored Location 3" 5 "Stored Location 4" ;
VAL_ 1443 TODCSR_LocChrgPwrLvlReq 0 "Unknown" 1 "Level 1" 2 "Level 2" 3 "DC" 4 "Wireless" ;
VAL_ 1425 Sig0087 0 "FALSE" 1 "TRUE" ;
VAL_ 1425 Sig0084 0 "2000" 1 "2001" 2 "2002" 3 "2003" 4 "2004" 5 "2005" 6 "2006" 7 "2007" 8 "2008" 9 "2009" 10 "2010" 11 "2011" 12 "2012" 13 "2013" 14 "2014" 15 "2015" 16 "2016" 17 "2017" 18 "2018" 19 "2019" 20 "2020" 21 "2021" 22 "2022" 23 "2023" 24 "2024" 25 "2025" 26 "2026" 27 "2027" 28 "2028" 29 "2029" 30 "2030" 31 "2031" 32 "2032" 33 "2033" 34 "2034" 35 "2035" 36 "2036" 37 "2037" 38 "2038" 39 "2039" 40 "2040" 41 "2041" 42 "2042" 43 "2043" 44 "2044" 45 "2045" 46 "2046" 47 "2047" 48 "2048" 49 "2049" 50 "2050" 51 "2051" 52 "2052" 53 "2053" 54 "2054" 55 "2055" 56 "2056" 57 "2057" 58 "2058" 59 "2059" 60 "2060" 61 "2061" 62 "2062" 63 "NOT APPLICABLE" ;
VAL_ 1425 Sig0079 0 "UNKNOWN" 1 "<= 5 KM/H [MPH]" 2 "7 KM/H [MPH]" 3 "10 KM/H [MPH]" 4 "15 KM/H [MPH]" 5 "20 KM/H [MPH]" 6 "25 KM/H [MPH]" 7 "30 KM/H [MPH]" 8 "35 KM/H [MPH]" 9 "40 KM/H [MPH]" 10 "45 KM/H [MPH]" 11 "50 KM/H [MPH]" 12 "55 KM/H [MPH]" 13 "60 KM/H" 14 "MPH]65 KM/H [MPH]" 15 "70 KM/H [MPH]" 16 "75 KM/H [MPH]" 17 "80 KM/H [MPH]" 18 "85 KM/H [MPH]" 19 "90 KM/H [MPH]" 20 "95 KM/H [MPH]" 21 "100 KM/H [MPH]" 22 "105 KM/H [MPH]" 23 "110 KM/H [MPH]" 24 "115 KM/H [MPH]" 25 "120 KM/H[MPH]" 26 "130 KM/H [MPH]" 27 "140 KM/H [MPH]" 28 "150 KM/H [MPH]" 29 "160 KM/H [MPH]" 30 "UNLIMITED" 31 "NOT AVAILABLE" ;
VAL_ 1425 Sig0078 0 "> 130 KPH OR > 80 MPH" 1 "101-130 KPH OR 65\???80 MPH" 2 "91-100 KPH OR 55\???64 MPH" 3 "71-90 KPH OR 41\???54 MPH" 4 "51-70 KPH OR 31\???40 MPH" 5 "31-50 KPH OR 21\???30 MPH" 6 "11-30 KPH OR 6 \???20 MPH" 7 "<11 KPH OR < 6 MPH" 8 "UNKNOWN" ;
VAL_ 1425 Sig0083 0 "QUARTER 1" 1 "QUARTER 2" 2 "QUARTER 3" 3 "QUARTER 4" ;
VAL_ 1425 ADASIS_NAVILINK_FncRdClss 0 "LOCAL" 1 "SFREEWAY" 2 "FREEWAY" 3 "PED-MALL" 4 "HIGHWAY" 5 "ARTERIAL" 6 "ALLEY" 7 "COLLECTOR" ;
VAL_ 1425 Sig0081 0 "IMPLICIT" 1 "ON TRAFFIC SIGN" 2 "ONLY BY NIGHT" 3 "ONLY BY DAY" 4 "TIME OF DAY" 5 "ONLY BY RAIN" 6 "ONLY BY SNOW OR FOG" 7 "UNKOWN" ;
VAL_ 1425 Sig0090 0 "ROAD IS NOT CONTROLLED ACCESS ROAD" 1 "ROAD IS CONTROLLED ACCESS ROAD" ;
VAL_ 1425 Sig0089 0 "MILES/H" 1 "KM/H" ;
VAL_ 1425 ADASIS_NAVILINK_MpDtAv 0 "NOT VALID" 1 "VALID" ;
VAL_ 1425 Sig0082 0 "NOT ASSURED" 1 "ASSURED" ;
VAL_ 1425 Sig0080 0 "DRIVING SIDE LEFT" 1 "DRIVING SIDE RIGHT" ;
VAL_ 1425 Sig0085 0 "NO INFO AVAILABLE" 1 "ONE LANE" 2 "TWO OR THREE LANES" 3 "FOUR OR MORE LANES" ;
VAL_ 718 HVWrlsChrgStopReqd 0 "FALSE" 1 "TRUE" ;
VAL_ 718 HVWrlsChrgWiFiConctSts 0 "Unknown" 1 "Connected" 2 "Lost" ;
VAL_ 718 HVWrlsChrgSysFltSts 0 "No Fault" 1 "Over Voltage" 2 "Under Voltage" 3 "Overload" 4 "Over Temperature" 5 "Lost of Wifi Communication" 6 "Lost of CAN Communication" ;
VAL_ 730 HVWrlsChrgLivngObjDtd 0 "FALSE" 1 "TRUE" ;
VAL_ 730 HVWrlsChrgFrgnObjDtd 0 "FALSE" 1 "TRUE" ;
VAL_ 716 HVWrlsChrgRctfrTemp_Inv 0 "FALSE" 1 "TRUE" ;
VAL_ 716 HVWrlsChrgVehCoilTempA_Inv 0 "FALSE" 1 "TRUE" ;
VAL_ 716 HVWrlsChrgVehCoilTempB_Inv 0 "FALSE" 1 "TRUE" ;
VAL_ 717 HVWrlsChrgIntopbltCkSts 0 "Unknown" 1 "Pass" 2 "Fail" ;
VAL_ 717 HVWrlsChrgIntopbltCkFldRsn 0 "None" 1 "Wrong Charging Protocol" 2 "Unidentified Equipment" ;
VAL_ 177 HVWrlsChrgACGridPwr_Inv 0 "FALSE" 1 "TRUE" ;
VAL_ 177 HVWrlsChrgDCOutCurr_Inv 0 "FALSE" 1 "TRUE" ;
VAL_ 177 HVWrlsChrgSysCurrLim_Inv 0 "FALSE" 1 "TRUE" ;
VAL_ 177 HVWrlsChrgDCOutVltg_Inv 0 "FALSE" 1 "TRUE" ;
VAL_ 177 HVWrlsChrgAlgnCkRespVal_Inv 0 "FALSE" 1 "TRUE" ;
VAL_ 535 HVWrlsChrgSysStat 0 "Wireless Charging Inactive" 1 "Wireless Charging Pairing" 2 "Wireless Charging Standby" 3 "Wireless Charging Ready" 4 "Wireless Charging" 5 "Wireless Charging Complete" 6 "Wireless Charging Terminated" ;
VAL_ 1479 Sig3479 0 "TOWN" 1 "COUNTRY ROAD" 2 "MOTORWAY" 3 "RESERVED1" 4 "RESERVED2" 5 "RESERVED3" 6 "RESERVED 4" 7 "UNDEFINED" ;
VAL_ 1479 Sig3477 0 "UNKNOWN" 1 "NOT BLOCKED" 2 "FULL BLOCKAGE" 3 "PARTIAL BLOCKAGE" 4 "RESERVED3" 5 "RESERVED4" 6 "RESERVED5" 7 "RESERVED6" ;
VAL_ 1479 Sig3476 0 "CLEAR WEATHER" 1 "LIGHT FOG" 2 "MEDIUM FOG" 3 "HEAVY FOG" 4 "LIGHT SNOW" 5 "MEDIUM SNOW" 6 "HEAVY SNOW" 7 "LIGHT RAIN" 8 "MEDIUM RAIN" 9 "HEAVY RAIN" ;
VAL_ 1479 Sig3508 0 "OFF" 1 "AHBA" 2 "GFHB" ;
VAL_ 1479 Sig3478 0 "UNKNOWN" 1 "LIT ENVIRONMENT DURING NIGHT" 2 "UNLIT ENVIRONMENT DURING NIGHT" 3 "DAYLIGHT" ;
VAL_ 1824 Sig7678 0 "FALSE" 1 "TRUE" ;
VAL_ 1824 Sig7675 0 "FALSE" 1 "TRUE" ;
VAL_ 1824 Sig7674 0 "FALSE" 1 "TRUE" ;
VAL_ 1824 Sig7673 0 "FALSE" 1 "TRUE" ;
VAL_ 1824 Sig7672 0 "FALSE" 1 "TRUE" ;
VAL_ 1824 Sig7671 0 "FALSE" 1 "TRUE" ;
VAL_ 1824 Sig7670 0 "FALSE" 1 "TRUE" ;
VAL_ 1824 Sig7669 0 "FALSE" 1 "TRUE" ;
VAL_ 1824 Sig7686 0 "FALSE" 1 "TRUE" ;
VAL_ 1824 Sig7685 0 "FALSE" 1 "TRUE" ;
VAL_ 1824 Sig7684 0 "FALSE" 1 "TRUE" ;
VAL_ 1824 Sig7683 0 "FALSE" 1 "TRUE" ;
VAL_ 1824 Sig7682 0 "FALSE" 1 "TRUE" ;
VAL_ 1824 Sig7681 0 "FALSE" 1 "TRUE" ;
VAL_ 1824 Sig7680 0 "FALSE" 1 "TRUE" ;
VAL_ 1824 TrfcSgnMemOfstEnbld 0 "FALSE" 1 "TRUE" ;
VAL_ 1824 Sig7698 0 "FALSE" 1 "TRUE" ;
VAL_ 1824 Sig7697 0 "FALSE" 1 "TRUE" ;
VAL_ 1824 Sig7696 0 "FALSE" 1 "TRUE" ;
VAL_ 1824 Sig7695 0 "FALSE" 1 "TRUE" ;
VAL_ 1824 Sig7694 0 "FALSE" 1 "TRUE" ;
VAL_ 1824 Sig7693 0 "FALSE" 1 "TRUE" ;
VAL_ 1824 Sig7692 0 "FALSE" 1 "TRUE" ;
VAL_ 1824 Sig7688 0 "FALSE" 1 "TRUE" ;
VAL_ 1824 Sig7699 0 "FALSE" 1 "TRUE" ;
VAL_ 1339 Sig7687 0 "No Action" 1 "Off" 2 "On" ;
VAL_ 1339 Sig7676 0 "No Action" 1 "Off" 2 "On" ;
VAL_ 1339 Sig7667 0 "No Action" 1 "Off" 2 "On" ;
VAL_ 1242 Sig7691 0 "No Action" 1 "Active" 2 "Cancel Chime" ;
VAL_ 1242 Sig7689 0 "No Action" 1 "Active" 2 "Cancel Chime" ;
VAL_ 1952 Sig7677 0 "Setting Unknown" 1 "Off" 2 "On" ;
VAL_ 1952 Sig7668 0 "Setting Unknown" 1 "Off" 2 "On" ;
VAL_ 1952 Sig7666 0 "Setting Unknown" 1 "Off" 2 "On" ;
VAL_ 1952 Sig7690 0 "FALSE" 1 "TRUE" ;
VAL_ 1952 Sig7679 0 "FALSE" 1 "TRUE" ;
VAL_ 728 ACCompNormLd_Inv 0 "FALSE" 1 "TRUE" ;
VAL_ 728 OutsdAmbtLgtLvl_Inv 0 "FALSE" 1 "TRUE" ;
VAL_ 728 OutsdAmbtLgtLvl_DuD 0 "FALSE" 1 "TRUE" ;
VAL_ 728 PFMinIdlBsRq 0 "NO IDLE BOOST REQUESTED" 1 "BOOST LEVEL 1" 2 "BOOST LEVEL 2" 3 "BOOST LEVEL 3" 4 "BOOST LEVEL 4(NEW REQUEST)" ;
VAL_ 728 StBltShfIntlkReqSts 0 "Driver Seatbelt Shift Interlock Active" 1 "Passenger Seatbelt Shift Interlock Active" 2 "Seatbelt Shift Interlock Inactive" 3 "Seatbelt Shift Interlock Override Expired" ;
VAL_ 728 LDWCtrlSwSts 0 "Not Pressed" 1 "Pressed" 2 "Fault" 3 "Unknown" ;
VAL_ 728 EE46ecGridVltgOvrrdPrty 0 "None" 1 "Low" 2 "Medium" 3 "High" ;
VAL_ 728 ACCompModReq 0 "Disengage Immediately" 1 "Disengage" 2 "Engage" 3 "No Action" ;
VAL_ 728 FOPPriGridOvrrdActv 0 "FALSE" 1 "TRUE" ;
VAL_ 728 EPMGridIsltnReqd 0 "FALSE" 1 "TRUE" ;
VAL_ 728 ClntCircPmpRq 0 "Off" 1 "On" ;
VAL_ 728 ClmtCtrlHtrEngRunRq 0 "No Action" 1 "Engine Run Requested" ;
VAL_ 728 BdyCtrlEmsRltMlfAtv 0 "FALSE" 1 "TRUE" ;
VAL_ 728 ACCmpsrFldOn 0 "FALSE" 1 "TRUE" ;
VAL_ 728 ACCmEngRunReq 0 "No Action" 1 "Engine Run Requested" ;
VAL_ 728 PlatEngSpdCmdSysTyp 0 "No Platform Eng Speed Command Sys" 1 "Power Take Off" 2 "Reserved" ;
VAL_ 728 LdMeToCarActv 0 "FALSE" 1 "TRUE" ;
VAL_ 1442 IBS12VBatCurrExtndRng_Inv 0 "FALSE" 1 "TRUE" ;
VAL_ 1442 IBS12VEstdBatTemp_Inv 0 "FALSE" 1 "TRUE" ;
VAL_ 1442 IBSIntrnlFltPr_Inv 0 "FALSE" 1 "TRUE" ;
VAL_ 1442 IBSIntrnlFltPr 0 "FALSE" 1 "TRUE" ;
VAL_ 1442 BCERDTC_SysDes 0 "P0_Powertrain Codes SAE Controlled" 1 "P1_Powertrain Codes MFG Controlled" 2 "P2_Powertrain Codes Reserved" 3 "P3_Powertrain Codes Reserved" 4 "C0_Chassis Codes SAE Controlled" 5 "C1_Chassis Codes MFG Controlled" 6 "C2_Chassis Codes Reserved" 7 "C3_Chassis Codes Reserved" 8 "B0_Body Codes SAE Controlled" 9 "B1_Body Codes MFG Controlled" 10 "B2_Body Codes Reserved" 11 "B3_Body Codes Reserved" 12 "U0_Network Codes SAE Controlled" 13 "U1_Network Codes MFG Controlled" 14 "U2_Network Codes Reserved" 15 "U3_Network Codes Reserved" ;
VAL_ 1442 EngOffTmExtndRng_Inv 0 "FALSE" 1 "TRUE" ;
VAL_ 1442 EnhdElpsdTmCntDgrd 0 "FALSE" 1 "TRUE" ;
VAL_ 1442 ElpsdTimeCntRstOcc 0 "FALSE" 1 "TRUE" ;
VAL_ 1442 TrnstStrgLogisticsMdActivation 0 "FALSE" 1 "TRUE" ;
VAL_ 1442 RstrctdPwrtrnOpModeReqd 0 "FALSE" 1 "TRUE" ;
VAL_ 1442 PrtctdIdlShftrLckReq 0 "FALSE" 1 "TRUE" ;
VAL_ 1442 FgLmpFrtFncActv 0 "FALSE" 1 "TRUE" ;
VAL_ 1442 ExtLgtChrgphyFrtActvn 0 "No Animation" 1 "Animation 1" 2 "Animation 2" 3 "Animation 3" 4 "Animation 4" 5 "Animation 5" 6 "Animation 6" ;
VAL_ 1442 IBS12VBatVlt_Inv 0 "FALSE" 1 "TRUE" ;
VAL_ 702 BGI5_TrnLmpLtOtgDtd 0 "FALSE" 1 "TRUE" ;
VAL_ 702 BGI5_TrnLmpLtFncActv 0 "FALSE" 1 "TRUE" ;
VAL_ 702 BGI5_TrnLmpRtOtgDtd 0 "FALSE" 1 "TRUE" ;
VAL_ 702 BGI5_TrnLmpRtFncActv 0 "FALSE" 1 "TRUE" ;
VAL_ 1408 PerfTracMgmtModeSwSts 0 "Not Supported" 1 "No Activation" 2 "Increment" 3 "Decrement" 4 "Faulted" ;
VAL_ 1408 AirDflctrSysStat 0 "Unknown Position" 1 "Stowed Position" 2 "Drag Lowered Position" 3 "Drag Raised Position" 4 "Tow Haul Position" 5 "Brake Cooling Position" ;
VAL_ 1408 PIMRI_BCM_PrmntDTCInd 0 "FALSE" 1 "TRUE" ;
VAL_ 1408 PIMRI_BCM_FltsPrsntInd 0 "FALSE" 1 "TRUE" ;
VAL_ 1408 LDWCtrlSelctdStatRaw 0 "PRESSED" 1 "NOT PRESSED" 2 "UNKNOWN" ;
VAL_ 1408 DrvDrAjrStat 0 "FALSE" 1 "TRUE" ;
VAL_ 1408 DrvDrAjrStat_Inv 0 "FALSE" 1 "TRUE" ;
VAL_ 1408 AE44SeltdStatRw 0 "Not Pressed" 1 "Pressed" 2 "Unknown" 3 "Failed" ;
VAL_ 1408 WshldWshFtrActv 0 "FALSE" 1 "TRUE" ;
VAL_ 1408 WprFrActUnfltdStat 0 "FALSE" 1 "TRUE" ;
VAL_ 1408 WprFrActFltdStat 0 "FALSE" 1 "TRUE" ;
VAL_ 1408 EnhdDrvrSeltdMdSwChsUseActv 0 "FALSE" 1 "TRUE" ;
VAL_ 1408 VehDynMdSwAct 0 "FALSE" 1 "TRUE" ;
VAL_ 1408 VehDynMdSwAct_Inv 0 "FALSE" 1 "TRUE" ;
VAL_ 1408 PerfTracMgmtActvnConfSts 0 "No Action" 1 "PTM Confirmed" 2 "Cancel PTM Request" ;
VAL_ 1409 TrnSigSwRtActv 0 "FALSE" 1 "TRUE" ;
VAL_ 1409 TrnSigSwLtActv 0 "FALSE" 1 "TRUE" ;
VAL_ 1409 PrkBrkSwAtv 0 "FALSE" 1 "TRUE" ;
VAL_ 1409 BrkLtsAtv 0 "FALSE" 1 "TRUE" ;
VAL_ 932 RatlzdEVDCCompVlvLSDCurrFbk_Inv 0 "FALSE" 1 "TRUE" ;
VAL_ 932 CustmModePwrtrnStrdPerfMode 0 "Unknown" 1 "Normal" 2 "Powertrain Sport" 3 "Chassis Sport" 4 "Eco" 5 "Mountain" 6 "Hold" 7 "Snow Ice" 8 "Start Stop" 9 "Tow Haul" 10 "Grade Braking Disabled" 11 "Speed Matching" 12 "Track" 13 "Exhaust Brake" 14 "Normal AWD" ;
VAL_ 932 PltfTrnsTUDSwSt 0 "No Activation" 1 "Increment Switch Active" 2 "Decrement Switch Active" 3 "Illegal Up/Down Switch State Active" ;
VAL_ 932 PltfTrnsTUDSecSwSt 0 "No Activation" 1 "Increment Switch Active" 2 "Decrement Switch Active" 3 "Illegal Up/Down Switch State Active" ;
VAL_ 932 LIBCfg 0 "Not supported" 1 "LIB1" 2 "LIB2" ;
VAL_ 932 ShftFrmPrkAlwd 0 "FALSE" 1 "TRUE" ;
VAL_ 932 DrvrElecVehModeCmnd 0 "FALSE" 1 "TRUE" ;
VAL_ 1426 DM1Unavailable 0 "FALSE" 1 "TRUE" ;
VAL_ 1426 DM1Status 0 "Inactive" 1 "Active" ;
VAL_ 1426 DM1Pending 0 "FALSE" 1 "TRUE" ;
VAL_ 1426 DM1Name 0 "None" 1 "Tour" 2 "Sport" 3 "Track" 4 "Winter" 5 "Off Road" 6 "Tow/Haul" 7 "Hold" 8 "Mountain" 9 "Personal" 10 "Custom" 11 "AWD" 12 "Economy" 13 "Automatic" 14 "EV" 15 "grade braking" 16 "exhaust brake" 17 "active rev match" 18 "2WD" 19 "Comfort" 20 "start/stop disable" 21 "Crawl" 22 "Charge Plus" 23 "Baja" 24 "Max Power" 25 "Reserved 1 - Reserved 7" ;
VAL_ 1426 DM2Unavailable 0 "FALSE" 1 "TRUE" ;
VAL_ 1426 DM2Status 0 "Inactive" 1 "Active" ;
VAL_ 1426 DM2Pending 0 "FALSE" 1 "TRUE" ;
VAL_ 1426 DM2Name 0 "None" 1 "Tour" 2 "Sport" 3 "Track" 4 "Winter" 5 "Off Road" 6 "Tow/Haul" 7 "Hold" 8 "Mountain" 9 "Personal" 10 "Custom" 11 "AWD" 12 "Economy" 13 "Automatic" 14 "EV" 15 "grade braking" 16 "exhaust brake" 17 "active rev match" 18 "2WD" 19 "Comfort" 20 "start/stop disable" 21 "Crawl" 22 "Charge Plus" 23 "Baja" 24 "Max Power" 25 "Reserved 1 - Reserved 7" ;
VAL_ 1426 DM3Unavailable 0 "FALSE" 1 "TRUE" ;
VAL_ 1426 DM3Status 0 "Inactive" 1 "Active" ;
VAL_ 1426 DM3Pending 0 "FALSE" 1 "TRUE" ;
VAL_ 1426 DM3Name 0 "None" 1 "Tour" 2 "Sport" 3 "Track" 4 "Winter" 5 "Off Road" 6 "Tow/Haul" 7 "Hold" 8 "Mountain" 9 "Personal" 10 "Custom" 11 "AWD" 12 "Economy" 13 "Automatic" 14 "EV" 15 "grade braking" 16 "exhaust brake" 17 "active rev match" 18 "2WD" 19 "Comfort" 20 "start/stop disable" 21 "Crawl" 22 "Charge Plus" 23 "Baja" 24 "Max Power" 25 "Reserved 1 - Reserved 7" ;
VAL_ 1426 DM4Unavailable 0 "FALSE" 1 "TRUE" ;
VAL_ 1426 DM4Status 0 "Inactive" 1 "Active" ;
VAL_ 1426 DM4Pending 0 "FALSE" 1 "TRUE" ;
VAL_ 1426 DM4Name 0 "None" 1 "Tour" 2 "Sport" 3 "Track" 4 "Winter" 5 "Off Road" 6 "Tow/Haul" 7 "Hold" 8 "Mountain" 9 "Personal" 10 "Custom" 11 "AWD" 12 "Economy" 13 "Automatic" 14 "EV" 15 "grade braking" 16 "exhaust brake" 17 "active rev match" 18 "2WD" 19 "Comfort" 20 "start/stop disable" 21 "Crawl" 22 "Charge Plus" 23 "Baja" 24 "Max Power" 25 "Reserved 1 - Reserved 7" ;
VAL_ 1426 DM5Unavailable 0 "FALSE" 1 "TRUE" ;
VAL_ 1426 DM5Status 0 "Inactive" 1 "Active" ;
VAL_ 1426 DM5Pending 0 "FALSE" 1 "TRUE" ;
VAL_ 1426 DM5Name 0 "None" 1 "Tour" 2 "Sport" 3 "Track" 4 "Winter" 5 "Off Road" 6 "Tow/Haul" 7 "Hold" 8 "Mountain" 9 "Personal" 10 "Custom" 11 "AWD" 12 "Economy" 13 "Automatic" 14 "EV" 15 "grade braking" 16 "exhaust brake" 17 "active rev match" 18 "2WD" 19 "Comfort" 20 "start/stop disable" 21 "Crawl" 22 "Charge Plus" 23 "Baja" 24 "Max Power" 25 "Reserved 1 - Reserved 7" ;
VAL_ 1426 DM6Unavailable 0 "FALSE" 1 "TRUE" ;
VAL_ 1426 DM6Status 0 "Inactive" 1 "Active" ;
VAL_ 1426 DM6Pending 0 "FALSE" 1 "TRUE" ;
VAL_ 1426 DM6Name 0 "None" 1 "Tour" 2 "Sport" 3 "Track" 4 "Winter" 5 "Off Road" 6 "Tow/Haul" 7 "Hold" 8 "Mountain" 9 "Personal" 10 "Custom" 11 "AWD" 12 "Economy" 13 "Automatic" 14 "EV" 15 "grade braking" 16 "exhaust brake" 17 "active rev match" 18 "2WD" 19 "Comfort" 20 "start/stop disable" 21 "Crawl" 22 "Charge Plus" 23 "Baja" 24 "Max Power" 25 "Reserved 1 - Reserved 7" ;
VAL_ 1426 DM7Unavailable 0 "FALSE" 1 "TRUE" ;
VAL_ 1426 DM7Status 0 "Inactive" 1 "Active" ;
VAL_ 1426 DM7Pending 0 "FALSE" 1 "TRUE" ;
VAL_ 1426 DM7Name 0 "None" 1 "Tour" 2 "Sport" 3 "Track" 4 "Winter" 5 "Off Road" 6 "Tow/Haul" 7 "Hold" 8 "Mountain" 9 "Personal" 10 "Custom" 11 "AWD" 12 "Economy" 13 "Automatic" 14 "EV" 15 "grade braking" 16 "exhaust brake" 17 "active rev match" 18 "2WD" 19 "Comfort" 20 "start/stop disable" 21 "Crawl" 22 "Charge Plus" 23 "Baja" 24 "Max Power" 25 "Reserved 1 - Reserved 7" ;
VAL_ 1426 DM8Unavailable 0 "FALSE" 1 "TRUE" ;
VAL_ 1426 DM8Status 0 "Inactive" 1 "Active" ;
VAL_ 1426 DM8Pending 0 "FALSE" 1 "TRUE" ;
VAL_ 1426 DM8Name 0 "None" 1 "Tour" 2 "Sport" 3 "Track" 4 "Winter" 5 "Off Road" 6 "Tow/Haul" 7 "Hold" 8 "Mountain" 9 "Personal" 10 "Custom" 11 "AWD" 12 "Economy" 13 "Automatic" 14 "EV" 15 "grade braking" 16 "exhaust brake" 17 "active rev match" 18 "2WD" 19 "Comfort" 20 "start/stop disable" 21 "Crawl" 22 "Charge Plus" 23 "Baja" 24 "Max Power" 25 "Reserved 1 - Reserved 7" ;
VAL_ 1411 BatVlt_Inv 0 "FALSE" 1 "TRUE" ;
VAL_ 1411 BattCrntFltrd_Inv 0 "FALSE" 1 "TRUE" ;
VAL_ 1411 BattCrntFltrd_DuD 0 "FALSE" 1 "TRUE" ;
VAL_ 2147745822 Sig4411 0 "FALSE" 1 "TRUE" ;
VAL_ 963 NodeStsADIMb_CAN_9_LcFA 0 "FALSE" 1 "TRUE" ;
VAL_ 963 NodeStsADIMb_CAN_3_LcFA 0 "FALSE" 1 "TRUE" ;
VAL_ 963 NodeStsADIMb_CAN_2_LcFA 0 "FALSE" 1 "TRUE" ;
VAL_ 963 NodeStsADIMb_CAN_10_LcFA 0 "FALSE" 1 "TRUE" ;
VAL_ 963 NodeStsADIMa_CAN_9_LcFA 0 "FALSE" 1 "TRUE" ;
VAL_ 963 NodeStsADIMa_CAN_3_LcFA 0 "FALSE" 1 "TRUE" ;
VAL_ 963 NodeStsADIMa_CAN_2_LcFA 0 "FALSE" 1 "TRUE" ;
VAL_ 963 NodeStsADIMa_CAN_10_LcFA 0 "FALSE" 1 "TRUE" ;
VAL_ 963 NodeStsAE44_CAN_1_LcFA 0 "FALSE" 1 "TRUE" ;
VAL_ 963 NodeStsE5_LcFA 0 "FALSE" 1 "TRUE" ;
VAL_ 963 NodeStsAMP_LcFA 0 "FALSE" 1 "TRUE" ;
VAL_ 963 NodeStsALC_LcFA 0 "FALSE" 1 "TRUE" ;
VAL_ 963 NodeStsAHS_LcFA 0 "FALSE" 1 "TRUE" ;
VAL_ 963 NodeStsAHL_AFL_CAN_2_LcFA 0 "FALSE" 1 "TRUE" ;
VAL_ 963 NodeStsAGC_LcFA 0 "FALSE" 1 "TRUE" ;
VAL_ 963 NodeStsBSM_MH_LcFA 0 "FALSE" 1 "TRUE" ;
VAL_ 963 NodeStsBSM_CAN_3_LcFA 0 "FALSE" 1 "TRUE" ;
VAL_ 963 NodeStsBSM_CAN_2_LcFA 0 "FALSE" 1 "TRUE" ;
VAL_ 963 NodeStsBCM_LcFA 0 "FALSE" 1 "TRUE" ;
VAL_ 963 NodeStsARS_LcFA 0 "FALSE" 1 "TRUE" ;
VAL_ 963 NodeStsE8_LcFA 0 "FALSE" 1 "TRUE" ;
VAL_ 963 NodeStsAE44_CAN_2_LcFA 0 "FALSE" 1 "TRUE" ;
VAL_ 963 NodeStsEBCM_AV_CAN_2_LcFA 0 "FALSE" 1 "TRUE" ;
VAL_ 963 NodeStsDMS_LcFA 0 "FALSE" 1 "TRUE" ;
VAL_ 963 NodeStsE12_LcFA 0 "FALSE" 1 "TRUE" ;
VAL_ 963 NodeStsDCM_LcFA 0 "FALSE" 1 "TRUE" ;
VAL_ 963 NodeStsCSM_CAN_5_LcFA 0 "FALSE" 1 "TRUE" ;
VAL_ 963 NodeStsECP_E_CAN_9_LcFA 0 "FALSE" 1 "TRUE" ;
VAL_ 963 NodeStsECP_E_CAN_2_LcFA 0 "FALSE" 1 "TRUE" ;
VAL_ 963 NodeStsECM_CAN_3_LcFA 0 "FALSE" 1 "TRUE" ;
VAL_ 963 NodeStsECM_CAN_2_LcFA 0 "FALSE" 1 "TRUE" ;
VAL_ 963 NodeStsEBCM_CAN_3_LcFA 0 "FALSE" 1 "TRUE" ;
VAL_ 963 NodeStsEBCM_CAN_2_LcFA 0 "FALSE" 1 "TRUE" ;
VAL_ 963 NodeStsEBCM_AV_CAN_3_LcFA 0 "FALSE" 1 "TRUE" ;
VAL_ 963 NodeStsEOCM_CAN_3_LcFA 0 "FALSE" 1 "TRUE" ;
VAL_ 963 NodeStsEOCM_CAN_2_LcFA 0 "FALSE" 1 "TRUE" ;
VAL_ 963 NodeStsELM_LcFA 0 "FALSE" 1 "TRUE" ;
VAL_ 963 NodeStsECP_X1_CAN_3_LcFA 0 "FALSE" 1 "TRUE" ;
VAL_ 963 NodeStsECP_X1_CAN_2_LcFA 0 "FALSE" 1 "TRUE" ;
VAL_ 963 NodeStsECP_S_CAN_9_LcFA 0 "FALSE" 1 "TRUE" ;
VAL_ 963 NodeStsECP_S_CAN_2_LcFA 0 "FALSE" 1 "TRUE" ;
VAL_ 963 NodeStsECP_MC_LcFA 0 "FALSE" 1 "TRUE" ;
VAL_ 963 NodeStsEPSRAa_LcFA 0 "FALSE" 1 "TRUE" ;
VAL_ 963 NodeStsEPS_LcFA 0 "FALSE" 1 "TRUE" ;
VAL_ 963 NodeStsE19_LcFA 0 "FALSE" 1 "TRUE" ;
VAL_ 963 NodeStsEOCM_HCP2_LcFA 0 "FALSE" 1 "TRUE" ;
VAL_ 963 NodeStsEOCM_HCP1_CAN_8_LcFA 0 "FALSE" 1 "TRUE" ;
VAL_ 963 NodeStsEOCM_HCP1_CAN_3_LcFA 0 "FALSE" 1 "TRUE" ;
VAL_ 963 NodeStsEOCM_HCP1_CAN_2_LcFA 0 "FALSE" 1 "TRUE" ;
VAL_ 963 NodeStsEOCM_CAN_8_LcFA 0 "FALSE" 1 "TRUE" ;
VAL_ 963 NodeStsHVAC_FP_F_LcFA 0 "FALSE" 1 "TRUE" ;
VAL_ 963 NodeStsHUD_CAN_LcFA 0 "FALSE" 1 "TRUE" ;
VAL_ 963 NodeStsE22_LcFA 0 "FALSE" 1 "TRUE" ;
VAL_ 963 NodeStsFOPM_CAN_3_LcFA 0 "FALSE" 1 "TRUE" ;
VAL_ 963 NodeStsFOPM_CAN_2_LcFA 0 "FALSE" 1 "TRUE" ;
VAL_ 963 NodeStsFCM_LcFA 0 "FALSE" 1 "TRUE" ;
VAL_ 963 NodeStsFCM_LC_LcFA 0 "FALSE" 1 "TRUE" ;
VAL_ 963 NodeStsE20_LcFA 0 "FALSE" 1 "TRUE" ;
VAL_ 964 NodeStsMFC_LcFA 0 "FALSE" 1 "TRUE" ;
VAL_ 964 NodeStsLRR_LcFA 0 "FALSE" 1 "TRUE" ;
VAL_ 964 NodeStsLIB1_LcFA 0 "FALSE" 1 "TRUE" ;
VAL_ 964 NodeStsIPC_CAN_5_LcFA 0 "FALSE" 1 "TRUE" ;
VAL_ 964 NodeStsICS_Info_LcFA 0 "FALSE" 1 "TRUE" ;
VAL_ 964 NodeStsICCM_CAN_3_LcFA 0 "FALSE" 1 "TRUE" ;
VAL_ 964 NodeStsHVAC_FP_R_LcFA 0 "FALSE" 1 "TRUE" ;
VAL_ 964 NodeStsE38_LcFA 0 "FALSE" 1 "TRUE" ;
VAL_ 964 NodeStsE37_LcFA 0 "FALSE" 1 "TRUE" ;
VAL_ 964 NodeStsE36_LcFA 0 "FALSE" 1 "TRUE" ;
VAL_ 964 NodeStsE35_LcFA 0 "FALSE" 1 "TRUE" ;
VAL_ 964 NodeStsE34_LcFA 0 "FALSE" 1 "TRUE" ;
VAL_ 964 NodeStsE33_LcFA 0 "FALSE" 1 "TRUE" ;
VAL_ 964 NodeStsE32_LcFA 0 "FALSE" 1 "TRUE" ;
VAL_ 964 NodeStsE31_LcFA 0 "FALSE" 1 "TRUE" ;
VAL_ 964 NodeStsRDCM_LcFA 0 "FALSE" 1 "TRUE" ;
VAL_ 964 NodeStsRadioLow_LcFA 0 "FALSE" 1 "TRUE" ;
VAL_ 964 NodeStsE48_LcFA 0 "FALSE" 1 "TRUE" ;
VAL_ 964 NodeStsPDR_LcFA 0 "FALSE" 1 "TRUE" ;
VAL_ 964 NodeStsE44_LcFA 0 "FALSE" 1 "TRUE" ;
VAL_ 964 NodeStsNVM_LcFA 0 "FALSE" 1 "TRUE" ;
VAL_ 964 NodeStsE40_LcFA 0 "FALSE" 1 "TRUE" ;
VAL_ 964 NodeStsE39_LcFA 0 "FALSE" 1 "TRUE" ;
VAL_ 964 Sig4413 0 "FALSE" 1 "TRUE" ;
VAL_ 964 NodeStsE53_LcFA 0 "FALSE" 1 "TRUE" ;
VAL_ 964 NodeStsE52_LcFA 0 "FALSE" 1 "TRUE" ;
VAL_ 964 NodeStsE51_LcFA 0 "FALSE" 1 "TRUE" ;
VAL_ 964 NodeStsE50_LcFA 0 "FALSE" 1 "TRUE" ;
VAL_ 964 NodeStsSADS_LcFA 0 "FALSE" 1 "TRUE" ;
VAL_ 964 NodeStsRSC_LcFA 0 "FALSE" 1 "TRUE" ;
VAL_ 964 NodeStsSRR_RF_LcFA 0 "FALSE" 1 "TRUE" ;
VAL_ 964 NodeStsSRR_LR_CR_LcFA 0 "FALSE" 1 "TRUE" ;
VAL_ 964 NodeStsSRR_LF_LcFA 0 "FALSE" 1 "TRUE" ;
VAL_ 964 NodeStsSIB_LcFA 0 "FALSE" 1 "TRUE" ;
VAL_ 964 NodeStsSDM_LcFA 0 "FALSE" 1 "TRUE" ;
VAL_ 964 NodeStsE56_LcFA 0 "FALSE" 1 "TRUE" ;
VAL_ 964 NodeStsE55_LcFA 0 "FALSE" 1 "TRUE" ;
VAL_ 964 NodeStsE54_LcFA 0 "FALSE" 1 "TRUE" ;
VAL_ 964 NodeStsTCP_CAN_5_LcFA 0 "FALSE" 1 "TRUE" ;
VAL_ 964 NodeStsTCM_CAN_2_LcFA 0 "FALSE" 1 "TRUE" ;
VAL_ 964 NodeStsTCCM_LcFA 0 "FALSE" 1 "TRUE" ;
VAL_ 964 NodeStsE57_LcFA 0 "FALSE" 1 "TRUE" ;
VAL_ 964 NodeStsSRR_SRR_LcFA 0 "FALSE" 1 "TRUE" ;
VAL_ 964 NodeStsSRR_SLR_LcFA 0 "FALSE" 1 "TRUE" ;
VAL_ 964 NodeStsSRR_RR_LcFA 0 "FALSE" 1 "TRUE" ;
VAL_ 964 NodeStsWCM_LcFA 0 "FALSE" 1 "TRUE" ;
VAL_ 964 NodeStsE63_LcFA 0 "FALSE" 1 "TRUE" ;
VAL_ 964 NodeStsVLM_LcFA 0 "FALSE" 1 "TRUE" ;
VAL_ 964 NodeStsVKM_LcFA 0 "FALSE" 1 "TRUE" ;
VAL_ 964 NodeStsVICM_CAN_9_LcFA 0 "FALSE" 1 "TRUE" ;
VAL_ 964 NodeStsVICM_CAN_2_LcFA 0 "FALSE" 1 "TRUE" ;
VAL_ 964 NodeStsVCU_CAN_5_LcFA 0 "FALSE" 1 "TRUE" ;
VAL_ 964 NodeStsE60_LcFA 0 "FALSE" 1 "TRUE" ;
VAL_ 964 NodeStsECP_S2_CAN_2_LcFA 0 "FALSE" 1 "TRUE" ;
VAL_ 964 NodeStsE45_LcFA 0 "FALSE" 1 "TRUE" ;
VAL_ 964 NodeStsVDM_CAN_2_LcFA 0 "FALSE" 1 "TRUE" ;
VAL_ 964 NodeStsWE48_LcFA 0 "FALSE" 1 "TRUE" ;
VAL_ 964 NodeStsPCM_CAN_3_LcFA 0 "FALSE" 1 "TRUE" ;
VAL_ 964 NodeStsPCM_CAN_2_LcFA 0 "FALSE" 1 "TRUE" ;
VAL_ 964 NodeStsSDM_AV_LcFA 0 "FALSE" 1 "TRUE" ;
VAL_ 962 NodeStsACP2_MCU_CAN_8_LcFA 0 "FALSE" 1 "TRUE" ;
VAL_ 962 NodeStsACP2_MCU_CAN_2_LcFA 0 "FALSE" 1 "TRUE" ;
VAL_ 962 NodeStsVECM_CAN_2_LcFA 0 "FALSE" 1 "TRUE" ;
VAL_ 962 NodeStsVDM_CAN_9_LcFA 0 "FALSE" 1 "TRUE" ;
VAL_ 962 NodeStsE61_CAN_1_LcFA 0 "FALSE" 1 "TRUE" ;
VAL_ 962 NodeStsUPM_LcFA 0 "FALSE" 1 "TRUE" ;
VAL_ 962 NodeStsEPSb_LcFA 0 "FALSE" 1 "TRUE" ;
VAL_ 962 NodeStsSBM_CAN_10_LcFA 0 "FALSE" 1 "TRUE" ;
VAL_ 962 NodeStsVECM_CAN_9_LcFA 0 "FALSE" 1 "TRUE" ;
VAL_ 962 NodeStsECP_S2_CAN_9_LcFA 0 "FALSE" 1 "TRUE" ;
VAL_ 962 NodeStsCSM_AV_CAN_5_LcFA 0 "FALSE" 1 "TRUE" ;
VAL_ 962 NodeStsACP3_MCU_CAN_3_LcFA 0 "FALSE" 1 "TRUE" ;
VAL_ 962 NodeStsACP3_MCU_CAN_8_LcFA 0 "FALSE" 1 "TRUE" ;
VAL_ 962 NodeStsACP3_MCU_CAN_2_LcFA 0 "FALSE" 1 "TRUE" ;
VAL_ 1322 FrtPsngrAirbagDsblVisIndCmd 0 "On" 1 "Off" 2 "Flash" ;
VAL_ 1322 ORIP_EnvModPrsntRsp1Auth 0 "FALSE" 1 "TRUE" ;
VAL_ 1322 ORIP_DrvrStBltStsAuth_Inv 0 "FALSE" 1 "TRUE" ;
VAL_ 1322 ORIP_DrvrStBltStsAuth 0 "Unknown" 1 "UnFastened" 2 "Fastened" ;
VAL_ 1322 RstrntSysFltPrsnt 0 "FALSE" 1 "TRUE" ;
VAL_ 1322 FrtPsngrAirbagEnblVisIndCmd 0 "On" 1 "Off" 2 "Flash" ;
VAL_ 2147745833 Sig4429 0 "FALSE" 1 "TRUE" ;
VAL_ 1354 FE44RS_LtCntr 0 "OFF" 1 "FAILED" 2 "BLOCKED" 3 "ATTACHED_OBJECT" 4 "NO_OBJECT" 5 "ZONE_1" 6 "ZONE_2" 7 "ZONE_3" 8 "ZONE_4" 9 "ZONE_5" 10 "ZONE_6" 11 "OFF_NO_FAULT" 12 "RESERVED_1" 13 "RESERVED_2" 14 "RESERVED_3" ;
VAL_ 1354 FE44RS_Lt 0 "OFF" 1 "FAILED" 2 "BLOCKED" 3 "ATTACHED_OBJECT" 4 "NO_OBJECT" 5 "ZONE_1" 6 "ZONE_2" 7 "ZONE_3" 8 "ZONE_4" 9 "ZONE_5" 10 "ZONE_6" 11 "OFF_NO_FAULT" 12 "RESERVED_1" 13 "RESERVED_2" 14 "RESERVED_3" ;
VAL_ 1354 FE44RS_RtCntr 0 "OFF" 1 "FAILED" 2 "BLOCKED" 3 "ATTACHED_OBJECT" 4 "NO_OBJECT" 5 "ZONE_1" 6 "ZONE_2" 7 "ZONE_3" 8 "ZONE_4" 9 "ZONE_5" 10 "ZONE_6" 11 "OFF_NO_FAULT" 12 "RESERVED_1" 13 "RESERVED_2" 14 "RESERVED_3" ;
VAL_ 1354 FE44RS_Rt 0 "OFF" 1 "FAILED" 2 "BLOCKED" 3 "ATTACHED_OBJECT" 4 "NO_OBJECT" 5 "ZONE_1" 6 "ZONE_2" 7 "ZONE_3" 8 "ZONE_4" 9 "ZONE_5" 10 "ZONE_6" 11 "OFF_NO_FAULT" 12 "RESERVED_1" 13 "RESERVED_2" 14 "RESERVED_3" ;
VAL_ 1354 E44IM_FaildIndOn 0 "FALSE" 1 "TRUE" ;
VAL_ 1354 E44IM_DsbldIndOn 0 "FALSE" 1 "TRUE" ;
VAL_ 1354 E44VisObjIndStatReq 0 "No Action" 1 "Driver Tube Front" 2 "Driver Tube Rear" 3 "Full Active" ;
VAL_ 1354 E44Rgn 0 "Europe" 1 "North America" ;
VAL_ 1354 E44IM_TeenDrvrE44OffUnvIndOn 0 "FALSE" 1 "TRUE" ;
VAL_ 1354 E44IM_SnsrDstbdIndOn 0 "FALSE" 1 "TRUE" ;
VAL_ 1354 E44IM_SnsrClnIndOn 0 "FALSE" 1 "TRUE" ;
VAL_ 1354 E44IM_SnsrBlckdIndOn 0 "FALSE" 1 "TRUE" ;
VAL_ 1354 E44IM_RrOffIndOn 0 "FALSE" 1 "TRUE" ;
VAL_ 1354 E44IM_OffIndOn 0 "FALSE" 1 "TRUE" ;
VAL_ 1354 E44IM_FrtOffIndOn 0 "FALSE" 1 "TRUE" ;
VAL_ 1354 PrkAsstActIndCmnd 0 "FALSE" 1 "TRUE" ;
VAL_ 1354 PrkAsstStat 0 "OFF" 1 "STANDBY" 2 "DISABLED" 3 "FAILED" 4 "FRONT_REAR_ACTIVE" 5 "REAR_ACTIVE" 6 "FRONT_ACTIVE" 7 "UNKNOWN" ;
